VERSION ""

NS_ :

BS_:

BU_: AMP ETC GW ICM IVI NVS PDC TBOX VSP WCM

BO_ 1801 Diag_PhyReq_ICM: 8 GW
 SG_ Diag_PhyReq_ICM_Data : 0|64@1+ (1,0) [0|0] "N/A"  ICM

BO_ 1805 Diag_PhyReq_WCM: 8 GW
 SG_ Diag_PhyReq_WCM_Data : 0|64@1+ (1,0) [0|0] "N/A"  WCM

BO_ 1808 Diag_PhyReq_VSP: 8 GW
 SG_ Diag_PhyReq_VSP_Data : 0|64@1+ (1,0) [0|0] "N/A"  VSP

BO_ 1815 Diag_PhyReq_PDC: 8 GW
 SG_ Diag_PhyReq_PDC_Data : 0|64@1+ (1,0) [0|0] "N/A"  PDC

BO_ 1829 Diag_PhyReq_IVI: 8 GW
 SG_ Diag_PhyReq_IVI_Data : 0|64@1+ (1,0) [0|0] "N/A"  IVI

BO_ 1850 Diag_PhyReq_NVS: 8 GW
 SG_ Diag_PhyReq_NVS_Data : 0|64@1+ (1,0) [0|0] "N/A"  NVS

BO_ 1857 Diag_PhyReq_ETC: 8 GW
 SG_ Diag_PhyReq_ETC_Data : 0|64@1+ (1,0) [0|0] "N/A"  ETC

BO_ 1865 Diag_PhyReq_AMP: 8 GW
 SG_ Diag_PhyReq_AMP_Data : 0|64@1+ (1,0) [0|0] "N/A"  AMP

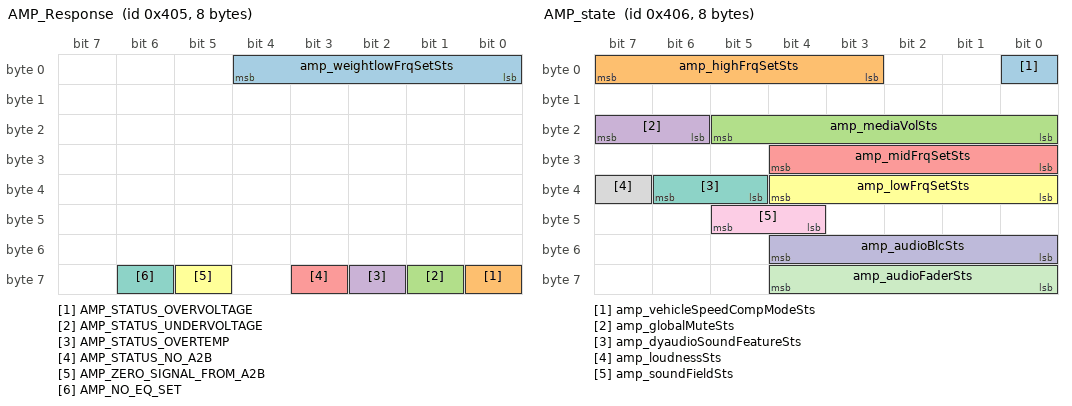
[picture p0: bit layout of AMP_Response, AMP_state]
BO_ 1029 AMP_Response: 8 AMP
 SG_ amp_weightlowFrqSetSts : 0|5@1+ (1,0) [0|31] ""  IVI
 SG_ AMP_STATUS_OVERVOLTAGE : 56|1@1+ (1,0) [0|1] "" Vector__XXX
 SG_ AMP_STATUS_UNDERVOLTAGE : 57|1@1+ (1,0) [0|1] "" Vector__XXX
 SG_ AMP_STATUS_OVERTEMP : 58|1@1+ (1,0) [0|1] "" Vector__XXX
 SG_ AMP_STATUS_NO_A2B : 59|1@1+ (1,0) [0|1] "" Vector__XXX
 SG_ AMP_ZERO_SIGNAL_FROM_A2B : 61|1@1+ (1,0) [0|1] "" Vector__XXX
 SG_ AMP_NO_EQ_SET : 62|1@1+ (1,0) [0|1] "" Vector__XXX

BO_ 1030 AMP_state: 8 AMP
 SG_ amp_vehicleSpeedCompModeSts : 0|1@1+ (1,0) [0|1] ""  IVI
 SG_ amp_highFrqSetSts : 3|5@1+ (1,0) [0|31] ""  IVI
 SG_ amp_mediaVolSts : 16|6@1+ (1,0) [0|63] ""  IVI
 SG_ amp_globalMuteSts : 22|2@1+ (1,0) [0|3] ""  IVI
 SG_ amp_midFrqSetSts : 24|5@1+ (1,0) [0|31] ""  IVI
 SG_ amp_lowFrqSetSts : 32|5@1+ (1,0) [0|31] ""  IVI
 SG_ amp_dyaudioSoundFeatureSts : 37|2@1+ (1,0) [0|3] ""  IVI
 SG_ amp_loudnessSts : 39|1@1+ (1,0) [0|1] ""  IVI
 SG_ amp_soundFieldSts : 44|2@1+ (1,0) [0|3] ""  IVI
 SG_ amp_audioBlcSts : 48|5@1+ (1,0) [0|31] ""  IVI
 SG_ amp_audioFaderSts : 56|5@1+ (1,0) [0|31] ""  IVI

BO_ 1609 NM_AMP: 8 AMP
 SG_ AMP_RMR : 8|1@1+ (1,0) [0|1] ""  ETC,GW,ICM,IVI,TBOX
 SG_ AMP_AWB : 12|1@1+ (1,0) [0|1] ""  ETC,GW,ICM,IVI,TBOX

BO_ 1993 Diag_Resp_AMP: 8 AMP
 SG_ Diag_Resp_AMP_Data : 0|64@1+ (1,0) [0|0] "N/A"  GW,TBOX

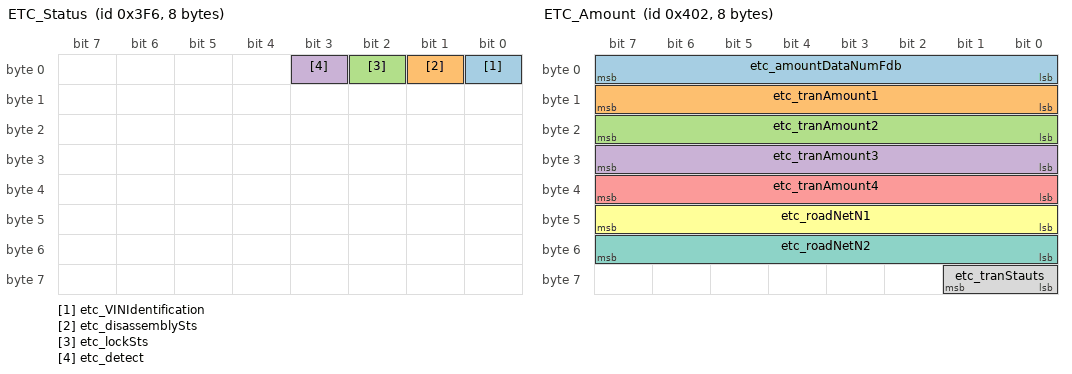
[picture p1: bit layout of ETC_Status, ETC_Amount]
BO_ 1014 ETC_Status: 8 ETC
 SG_ etc_VINIdentification : 0|1@1+ (1,0) [0|1] ""  IVI
 SG_ etc_disassemblySts : 1|1@1+ (1,0) [0|1] ""  IVI
 SG_ etc_lockSts : 2|1@1+ (1,0) [0|1] ""  IVI
 SG_ etc_detect : 3|1@1+ (1,0) [0|1] ""  IVI

BO_ 1026 ETC_Amount: 8 ETC
 SG_ etc_amountDataNumFdb : 0|8@1+ (1,0) [0|255] ""  IVI
 SG_ etc_tranAmount1 : 8|8@1+ (1,0) [0|255] "分"  IVI
 SG_ etc_tranAmount2 : 16|8@1+ (1,0) [0|255] "分"  IVI
 SG_ etc_tranAmount3 : 24|8@1+ (1,0) [0|255] "分"  IVI
 SG_ etc_tranAmount4 : 32|8@1+ (1,0) [0|255] "分"  IVI
 SG_ etc_roadNetN1 : 40|8@1+ (1,0) [0|255] ""  IVI
 SG_ etc_roadNetN2 : 48|8@1+ (1,0) [0|255] ""  IVI
 SG_ etc_tranStauts : 56|2@1+ (1,0) [0|3] ""  IVI

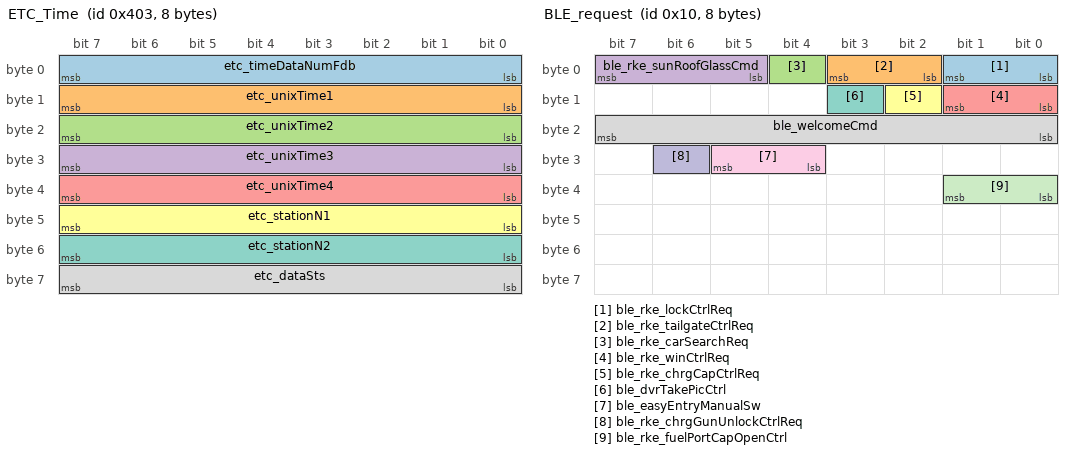
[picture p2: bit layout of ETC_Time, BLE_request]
BO_ 1027 ETC_Time: 8 ETC
 SG_ etc_timeDataNumFdb : 0|8@1+ (1,0) [0|255] ""  IVI
 SG_ etc_unixTime1 : 8|8@1+ (1,0) [0|255] "s"  IVI
 SG_ etc_unixTime2 : 16|8@1+ (1,0) [0|255] "s"  IVI
 SG_ etc_unixTime3 : 24|8@1+ (1,0) [0|255] "s"  IVI
 SG_ etc_unixTime4 : 32|8@1+ (1,0) [0|255] "s"  IVI
 SG_ etc_stationN1 : 40|8@1+ (1,0) [0|255] ""  IVI
 SG_ etc_stationN2 : 48|8@1+ (1,0) [0|255] ""  IVI
 SG_ etc_dataSts : 56|8@1+ (1,0) [0|255] ""  IVI

BO_ 1553 NM_ETC: 8 ETC
 SG_ ETC_RMR : 8|1@1+ (1,0) [0|1] ""  AMP,GW,ICM,IVI,TBOX
 SG_ ETC_AWB : 12|1@1+ (1,0) [0|1] ""  AMP,GW,ICM,IVI,TBOX

BO_ 1985 Diag_Resp_ETC: 8 ETC
 SG_ Diag_Resp_ETC_Data : 0|64@1+ (1,0) [0|0] "N/A"  GW,TBOX

BO_ 16 BLE_request: 8 GW
 SG_ ble_rke_lockCtrlReq : 0|2@1+ (1,0) [0|3] "" Vector__XXX
 SG_ ble_rke_tailgateCtrlReq : 2|2@1+ (1,0) [0|3] "" Vector__XXX
 SG_ ble_rke_carSearchReq : 4|1@1+ (1,0) [0|1] "" Vector__XXX
 SG_ ble_rke_sunRoofGlassCmd : 5|3@1+ (1,0) [0|7] "" Vector__XXX
 SG_ ble_rke_winCtrlReq : 8|2@1+ (1,0) [0|3] "" Vector__XXX
 SG_ ble_rke_chrgCapCtrlReq : 10|1@1+ (1,0) [0|1] "" Vector__XXX
 SG_ ble_dvrTakePicCtrl : 11|1@1+ (1,0) [0|1] ""  AMP,ICM
 SG_ ble_welcomeCmd : 16|8@1+ (1,0) [0|255] "" Vector__XXX
 SG_ ble_easyEntryManualSw : 28|2@1+ (1,0) [0|3] "" Vector__XXX
 SG_ ble_rke_chrgGunUnlockCtrlReq : 30|1@1+ (1,0) [0|1] "" Vector__XXX
 SG_ ble_rke_fuelPortCapOpenCtrl : 32|2@1+ (1,0) [0|3] "" Vector__XXX

BO_ 20 BMS_cellandmodulecnt: 8 GW
 SG_ bms_CellCnt : 0|13@1+ (1,0) [0|8191] ""  TBOX
 SG_ bms_ModuleCnt : 13|5@1+ (1,0) [0|31] ""  TBOX
 SG_ bms_packThermistorCnt : 18|7@1+ (1,0) [0|127] ""  TBOX
 SG_ bms_cellThermistorCnt : 25|7@1+ (1,0) [0|127] ""  TBOX
 SG_ bms_cellTemperatureDifferenceHig : 32|2@1+ (1,0) [0|3] ""  TBOX
 SG_ bms_batteryOverTemperature : 34|2@1+ (1,0) [0|3] ""  TBOX
 SG_ bms_overVoltage : 36|2@1+ (1,0) [0|3] ""  TBOX
 SG_ bms_lowVoltage : 38|2@1+ (1,0) [0|3] ""  TBOX
 SG_ bms_lowSoc : 40|2@1+ (1,0) [0|3] ""  TBOX
 SG_ bms_cellOverVoltage : 42|2@1+ (1,0) [0|3] ""  TBOX
 SG_ bms_cellLowVoltage : 44|2@1+ (1,0) [0|3] ""  TBOX
 SG_ bms_highSoc : 46|2@1+ (1,0) [0|3] ""  TBOX
 SG_ bms_socStepChange : 48|2@1+ (1,0) [0|3] ""  TBOX
 SG_ bms_chargerMismatch : 50|2@1+ (1,0) [0|3] ""  TBOX
 SG_ bms_cellOutOfBalance : 52|2@1+ (1,0) [0|3] ""  TBOX
 SG_ bms_isolationFault : 54|2@1+ (1,0) [0|3] ""  TBOX
 SG_ bms_hvilFault : 56|2@1+ (1,0) [0|3] ""  TBOX
 SG_ bms_batteryOverCharge : 58|2@1+ (1,0) [0|3] ""  TBOX

BO_ 65 BCM_tbox_auth: 8 GW
 SG_ bcm_challengeFrame1 : 0|64@1+ (1,0) [0|65535] ""  TBOX

BO_ 81 BCM_tbox_failCode: 8 GW
 SG_ bcm_failCode : 0|8@1+ (1,0) [0|255] ""  TBOX

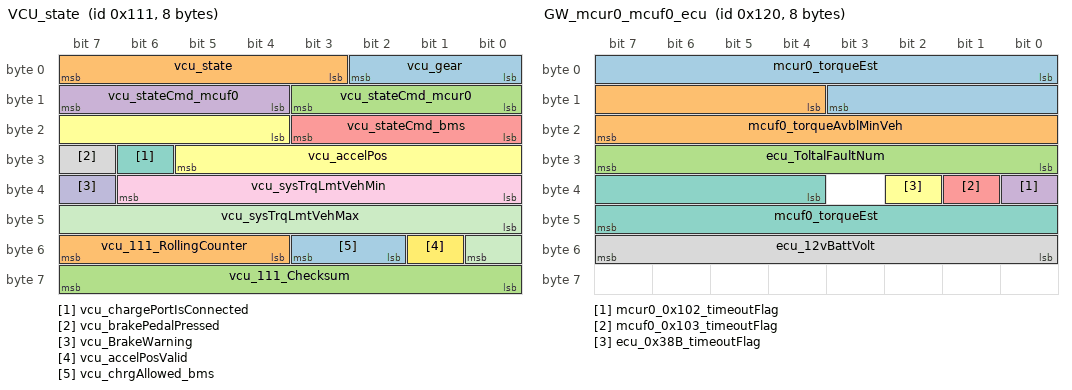
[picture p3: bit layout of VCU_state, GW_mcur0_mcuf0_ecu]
BO_ 273 VCU_state: 8 GW
 SG_ vcu_gear : 0|3@1+ (1,0) [0|7] ""  ETC,TBOX
 SG_ vcu_state : 3|5@1+ (1,0) [0|31] ""  TBOX
 SG_ vcu_stateCmd_mcur0 : 8|4@1+ (1,0) [0|15] ""  TBOX
 SG_ vcu_stateCmd_mcuf0 : 12|4@1+ (1,0) [0|15] ""  TBOX
 SG_ vcu_stateCmd_bms : 16|4@1+ (1,0) [0|15] ""  TBOX
 SG_ vcu_accelPos : 20|10@1+ (0.1,0) [0|100] "%"  IVI,NVS,TBOX
 SG_ vcu_chargePortIsConnected : 30|1@1+ (1,0) [0|1] ""  TBOX
 SG_ vcu_brakePedalPressed : 31|1@1+ (1,0) [0|1] ""  IVI,TBOX
 SG_ vcu_sysTrqLmtVehMin : 32|7@1+ (4,-500) [-500|0] "Nm"  TBOX
 SG_ vcu_BrakeWarning : 39|1@1+ (1,0) [0|1] ""  IVI
 SG_ vcu_sysTrqLmtVehMax : 40|9@1+ (3,0) [0|1200] "Nm"  TBOX
 SG_ vcu_accelPosValid : 49|1@1+ (1,0) [0|1] ""  IVI,NVS,TBOX
 SG_ vcu_chrgAllowed_bms : 50|2@1+ (1,0) [0|3] "" Vector__XXX
 SG_ vcu_111_RollingCounter : 52|4@1+ (1,0) [0|15] ""  IVI,NVS,TBOX
 SG_ vcu_111_Checksum : 56|8@1+ (1,0) [0|255] ""  IVI,NVS,TBOX

BO_ 276 BMS_state: 8 GW
 SG_ bms_state : 0|4@1+ (1,0) [0|15] ""  ICM,IVI,NVS,TBOX
 SG_ bms_dcChargeState : 4|3@1+ (1,0) [0|7] ""  IVI,TBOX
 SG_ bms_acChargeState : 7|3@1+ (1,0) [0|7] ""  IVI,TBOX
 SG_ bms_hvil : 10|1@1+ (1,0) [0|1] "" Vector__XXX
 SG_ bms_isolationState : 11|2@1+ (1,0) [0|3] "" Vector__XXX
 SG_ bms_contactorState : 13|4@1+ (1,0) [0|15] ""  TBOX
 SG_ bms_chargeInhibit : 17|1@1+ (1,0) [0|1] "" Vector__XXX
 SG_ bms_acChargeConnection : 18|1@1+ (1,0) [0|1] ""  IVI,TBOX
 SG_ bms_dcChargeConnection : 19|1@1+ (1,0) [0|1] ""  IVI,TBOX
 SG_ bms_alertLevel : 20|2@1+ (1,0) [0|3] ""  IVI
 SG_ bms_authenticationResult : 22|2@1+ (1,0) [0|3] ""  IVI
 SG_ bms_chargeReq : 24|1@1+ (1,0) [0|1] "" Vector__XXX
 SG_ bms_battWarmState : 25|2@1+ (1,0) [0|3] "" Vector__XXX
 SG_ bms_ptcEna : 27|2@1+ (1,0) [0|3] "" Vector__XXX
 SG_ bms_energyStatus : 29|10@1+ (0.1,0) [0|100] "" Vector__XXX
 SG_ bms_hvState : 39|3@1+ (1,0) [0|7] "" Vector__XXX
 SG_ bms_faultHvShutdownReq : 42|2@1+ (1,0) [0|3] "" Vector__XXX
 SG_ bms_114_Rollingcounter : 52|4@1+ (1,0) [0|15] ""  TBOX
 SG_ bms_114_Checksum : 56|8@1+ (1,0) [0|255] ""  TBOX

BO_ 288 GW_mcur0_mcuf0_ecu: 8 GW
 SG_ mcur0_torqueEst : 0|12@1- (0.8,0) [-1300|1300] "Nm"  TBOX
 SG_ mcuf0_torqueAvblMinVeh : 12|12@1+ (0.4,-1300) [-1300|0] "Nm"  TBOX
 SG_ ecu_ToltalFaultNum : 24|8@1+ (1,0) [0|252] ""  TBOX
 SG_ mcur0_0x102_timeoutFlag : 32|1@1+ (1,0) [0|1] "" Vector__XXX
 SG_ mcuf0_0x103_timeoutFlag : 33|1@1+ (1,0) [0|1] "" Vector__XXX
 SG_ ecu_0x38B_timeoutFlag : 34|1@1+ (1,0) [0|1] "" Vector__XXX
 SG_ mcuf0_torqueEst : 36|12@1- (0.8,0) [-1300|1300] "Nm"  TBOX
 SG_ ecu_12vBattVolt : 48|8@1+ (0.1,0) [0|25] "V"  TBOX

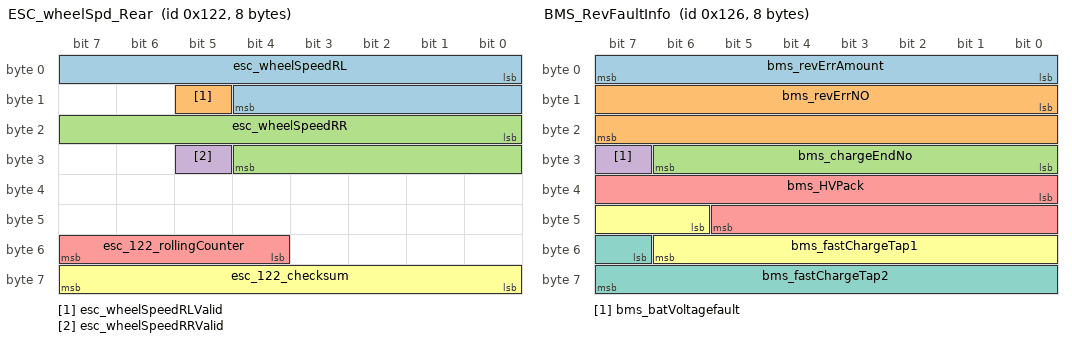
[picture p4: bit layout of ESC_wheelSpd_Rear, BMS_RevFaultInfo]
BO_ 290 ESC_wheelSpd_Rear: 8 GW
 SG_ esc_wheelSpeedRL : 0|13@1+ (0.05625,0) [0|270] "km/h"  IVI,TBOX
 SG_ esc_wheelSpeedRLValid : 13|1@1+ (1,0) [0|1] ""  IVI,TBOX
 SG_ esc_wheelSpeedRR : 16|13@1+ (0.05625,0) [0|270] "km/h"  IVI,TBOX
 SG_ esc_wheelSpeedRRValid : 29|1@1+ (1,0) [0|1] ""  IVI,TBOX
 SG_ esc_122_rollingCounter : 52|4@1+ (1,0) [0|15] ""  IVI
 SG_ esc_122_checksum : 56|8@1+ (1,0) [0|255] ""  IVI

BO_ 294 BMS_RevFaultInfo: 8 GW
 SG_ bms_revErrAmount : 0|8@1+ (1,0) [0|255] ""  TBOX
 SG_ bms_revErrNO : 8|16@1+ (1,0) [0|65535] ""  TBOX
 SG_ bms_chargeEndNo : 24|7@1+ (1,0) [0|127] ""  TBOX
 SG_ bms_batVoltagefault : 31|1@1+ (1,0) [0|1] "" Vector__XXX
 SG_ bms_HVPack : 32|14@1+ (0.05,0) [0|800] "V" Vector__XXX
 SG_ bms_fastChargeTap1 : 46|9@1+ (0.5,-40) [-40|215] "℃"  TBOX
 SG_ bms_fastChargeTap2 : 55|9@1+ (0.5,-40) [-40|215] "℃"  TBOX

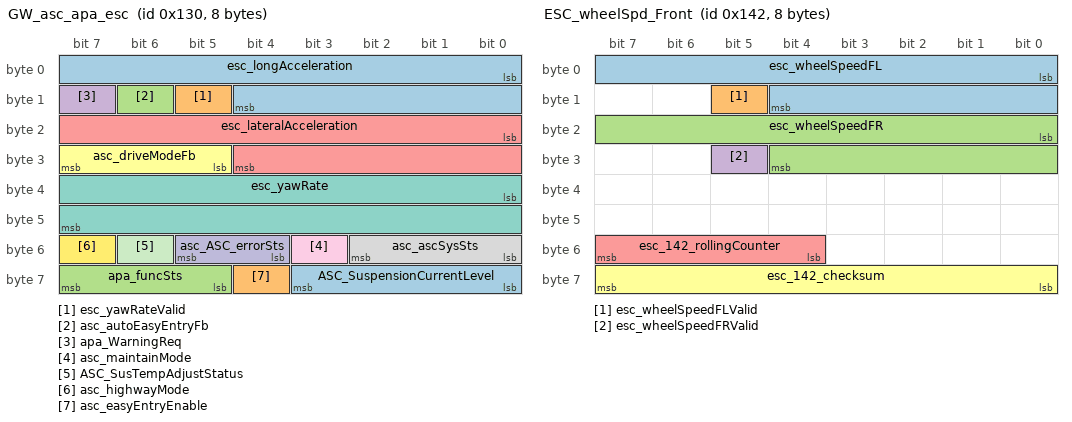
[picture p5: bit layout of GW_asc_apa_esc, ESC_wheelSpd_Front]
BO_ 304 GW_asc_apa_esc: 8 GW
 SG_ esc_longAcceleration : 0|13@1+ (0.01,-21) [-21|21] "m/s2"  ICM
 SG_ esc_yawRateValid : 13|1@1+ (1,0) [0|1] ""  ICM
 SG_ asc_autoEasyEntryFb : 14|1@1+ (1,0) [0|1] ""  IVI
 SG_ apa_WarningReq : 15|1@1+ (1,0) [0|1] ""  IVI
 SG_ esc_lateralAcceleration : 16|13@1+ (0.01,-21) [-21|21] "m/s2"  ICM
 SG_ asc_driveModeFb : 29|3@1+ (1,0) [0|7] ""  IVI
 SG_ esc_yawRate : 32|16@1+ (0.005,-163.84) [-163.84|163.835] "degree/s"  ICM
 SG_ asc_ascSysSts : 48|3@1+ (1,0) [0|7] ""  IVI
 SG_ asc_maintainMode : 51|1@1+ (1,0) [0|1] ""  IVI
 SG_ asc_ASC_errorSts : 52|2@1+ (1,0) [0|3] ""  IVI,TBOX
 SG_ ASC_SusTempAdjustStatus : 54|1@1+ (1,0) [0|1] ""  IVI
 SG_ asc_highwayMode : 55|1@1+ (1,0) [0|1] ""  IVI
 SG_ ASC_SuspensionCurrentLevel : 56|4@1+ (1,0) [0|15] ""  IVI
 SG_ asc_easyEntryEnable : 60|1@1+ (1,0) [0|1] ""  IVI
 SG_ apa_funcSts : 61|3@1+ (1,0) [0|7] ""  IVI

BO_ 320 GW_hcm: 8 GW
 SG_ hcm_0x100_timeoutFlag : 0|1@1+ (1,0) [0|1] ""  IVI
 SG_ hcm_0x110_timeoutFlag : 1|1@1+ (1,0) [0|1] ""  IVI
 SG_ hcm_leftHighBeamFaultSt : 7|1@1+ (1,0) [0|1] ""  IVI
 SG_ hcm_adbFuctionStsLt : 8|2@1+ (1,0) [0|3] ""  IVI
 SG_ hcm_rightHighBeamFaultSt : 10|1@1+ (1,0) [0|1] ""  IVI
 SG_ hcm_adbFuctionStsRt : 11|2@1+ (1,0) [0|3] ""  IVI
 SG_ AC_CompressorActualPower : 24|7@1+ (0.1,0) [0|10] "KW"  TBOX
 SG_ ac_0x3A6_timeoutFlag : 31|1@1+ (1,0) [0|1] ""  TBOX
 SG_ hcm_middleLeftPositionLampFault : 40|1@1+ (1,0) [0|1] ""  IVI
 SG_ hcm_middleRightPositionLampFault : 41|1@1+ (1,0) [0|1] ""  IVI
 SG_ hcm_hcmHeightSetLt : 42|3@1+ (1,0) [0|7] ""  IVI
 SG_ hcm_hcmHeightSetRt : 45|3@1+ (1,0) [0|7] ""  IVI
 SG_ hcm_leftHighBeamLedsFaultSt : 48|1@1+ (1,0) [0|1] ""  IVI
 SG_ hcm_leftHighBeamDriFaultWarning : 49|2@1+ (1,0) [0|2] ""  IVI
 SG_ hcm_leftLowBeamFaultSt : 51|1@1+ (1,0) [0|1] ""  IVI
 SG_ hcm_turnLampWarningLt : 52|1@1+ (1,0) [0|1] ""  IVI
 SG_ hcm_positionLampWarningLt : 53|1@1+ (1,0) [0|1] ""  IVI
 SG_ hcm_dayTimeRunningLampWarningLt : 54|1@1+ (1,0) [0|1] ""  IVI
 SG_ hcm_rightHighBeamLedsFaultSt : 56|1@1+ (1,0) [0|1] ""  IVI
 SG_ hcm_rightHighBeamDriFaultWarning : 57|2@1+ (1,0) [0|2] ""  IVI
 SG_ hcm_rightLowBeamFaultSt : 59|1@1+ (1,0) [0|1] ""  IVI
 SG_ hcm_turnLampWarningRt : 60|1@1+ (1,0) [0|1] ""  IVI
 SG_ hcm_positionLampWarningRt : 61|1@1+ (1,0) [0|1] ""  IVI
 SG_ hcm_dayTimeRunningLampWarningRt : 62|1@1+ (1,0) [0|1] ""  IVI

BO_ 322 ESC_wheelSpd_Front: 8 GW
 SG_ esc_wheelSpeedFL : 0|13@1+ (0.05625,0) [0|270] "km/h"  IVI,TBOX
 SG_ esc_wheelSpeedFLValid : 13|1@1+ (1,0) [0|1] ""  IVI,TBOX
 SG_ esc_wheelSpeedFR : 16|13@1+ (0.05625,0) [0|270] "km/h"  IVI,TBOX
 SG_ esc_wheelSpeedFRValid : 29|1@1+ (1,0) [0|1] ""  IVI,TBOX
 SG_ esc_142_rollingCounter : 52|4@1+ (1,0) [0|15] ""  IVI
 SG_ esc_142_checksum : 56|8@1+ (1,0) [0|255] ""  IVI

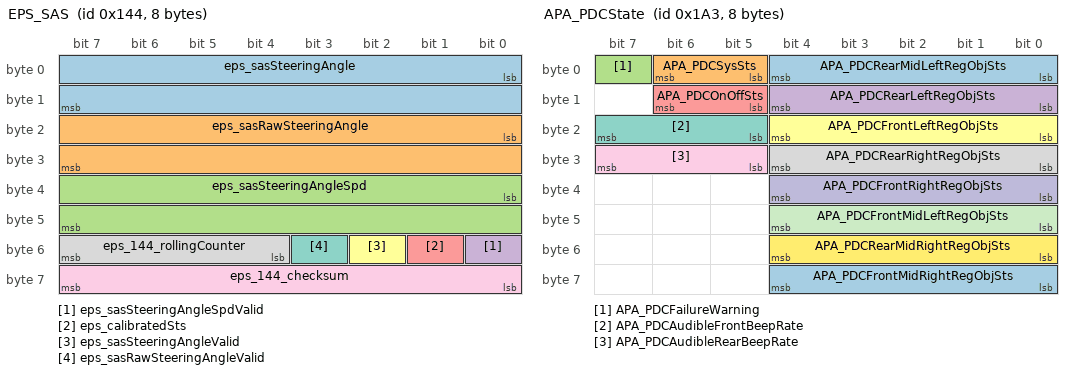
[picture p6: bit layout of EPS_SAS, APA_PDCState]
BO_ 324 EPS_SAS: 8 GW
 SG_ eps_sasSteeringAngle : 0|16@1+ (0.1,-780) [-780|779.9] "deg"  ICM,IVI,NVS,TBOX
 SG_ eps_sasRawSteeringAngle : 16|16@1+ (0.1,-780) [-780|779.9] "deg" Vector__XXX
 SG_ eps_sasSteeringAngleSpd : 32|16@1+ (0.1,-780) [-780|779.9] "deg/s"  NVS
 SG_ eps_sasSteeringAngleSpdValid : 48|1@1+ (1,0) [0|1] ""  NVS
 SG_ eps_calibratedSts : 49|1@1+ (1,0) [0|1] "" Vector__XXX
 SG_ eps_sasSteeringAngleValid : 50|1@1+ (1,0) [0|1] ""  ICM,IVI,NVS
 SG_ eps_sasRawSteeringAngleValid : 51|1@1+ (1,0) [0|1] "" Vector__XXX
 SG_ eps_144_rollingCounter : 52|4@1+ (1,0) [0|15] ""  ICM,IVI,TBOX
 SG_ eps_144_checksum : 56|8@1+ (1,0) [0|255] ""  ICM,IVI,TBOX

BO_ 419 APA_PDCState: 8 GW
 SG_ APA_PDCRearMidLeftRegObjSts : 0|5@1+ (1,0) [0|31] ""  IVI
 SG_ APA_PDCSysSts : 5|2@1+ (1,0) [0|3] ""  IVI
 SG_ APA_PDCFailureWarning : 7|1@1+ (1,0) [0|1] ""  IVI
 SG_ APA_PDCRearLeftRegObjSts : 8|5@1+ (1,0) [0|31] ""  IVI
 SG_ APA_PDCOnOffSts : 13|2@1+ (1,0) [0|3] ""  IVI
 SG_ APA_PDCFrontLeftRegObjSts : 16|5@1+ (1,0) [0|31] ""  IVI
 SG_ APA_PDCAudibleFrontBeepRate : 21|3@1+ (1,0) [0|7] ""  IVI
 SG_ APA_PDCRearRightRegObjSts : 24|5@1+ (1,0) [0|31] ""  IVI
 SG_ APA_PDCAudibleRearBeepRate : 29|3@1+ (1,0) [0|7] ""  IVI
 SG_ APA_PDCFrontRightRegObjSts : 32|5@1+ (1,0) [0|31] ""  IVI
 SG_ APA_PDCFrontMidLeftRegObjSts : 40|5@1+ (1,0) [0|31] ""  IVI
 SG_ APA_PDCRearMidRightRegObjSts : 48|5@1+ (1,0) [0|31] ""  IVI
 SG_ APA_PDCFrontMidRightRegObjSts : 56|5@1+ (1,0) [0|31] ""  IVI

BO_ 515 APA_avmState: 8 GW
 SG_ apa_avmSts : 0|4@1+ (1,0) [0|15] ""  IVI
 SG_ apa_avmHmiIndex : 4|4@1+ (1,0) [0|15] ""  IVI
 SG_ apa_avmViewMode : 8|2@1+ (1,0) [0|3] ""  IVI
 SG_ apa_avmDisplayReq : 10|2@1+ (1,0) [0|3] ""  IVI
 SG_ apa_avmMODSts : 12|2@1+ (1,0) [0|3] ""  IVI
 SG_ apa_avmFrontCaneraFailed : 14|1@1+ (1,0) [0|1] ""  IVI
 SG_ apa_avmRearCaneraFailed : 15|1@1+ (1,0) [0|1] ""  IVI
 SG_ apa_avmLeftCaneraFailed : 16|1@1+ (1,0) [0|1] ""  IVI
 SG_ apa_avmRightCaneraFailed : 17|1@1+ (1,0) [0|1] ""  IVI
 SG_ apa_avmVideoOutputFailed : 18|1@1+ (1,0) [0|1] ""  IVI
 SG_ apa_avmControllerOperatingFailed : 19|1@1+ (1,0) [0|1] ""  IVI
 SG_ apa_keytriggersts : 20|1@1+ (1,0) [0|1] ""  IVI
 SG_ apa_avmTrigByTurnningSts : 21|1@1+ (1,0) [0|1] ""  IVI
 SG_ apa_avmSingleViewSts : 24|5@1+ (1,0) [0|15] ""  IVI
 SG_ apa_avmFrontModWarningSts : 29|1@1+ (1,0) [0|1] ""  IVI
 SG_ apa_avmRearModWarningSts : 30|1@1+ (1,0) [0|1] ""  IVI
 SG_ apa_avmLeftModWarningSts : 31|1@1+ (1,0) [0|1] ""  IVI
 SG_ apa_avmRightModWarningSts : 32|1@1+ (1,0) [0|1] ""  IVI
 SG_ apa_avmCalibrationSts : 33|1@1+ (1,0) [0|1] ""  IVI
 SG_ apa_avmTrajectory_display : 34|1@1+ (1,0) [0|1] ""  IVI
 SG_ apa_avmAutoswitching_display : 35|1@1+ (1,0) [0|1] ""  IVI
 SG_ apa_avmCarBodyTransparent : 36|1@1+ (1,0) [0|1] ""  IVI
 SG_ apa_avmSwSts : 37|1@1+ (1,0) [0|1] ""  IVI
 SG_ apa_avmMonitVideoOutput : 38|1@1+ (1,0) [0|1] ""  IVI,TBOX
 SG_ apa_avmPDCfailureWarn : 40|3@1+ (1,0) [0|7] ""  IVI
 SG_ apa_avm_QuitSw : 43|1@1+ (1,0) [0|1] "" Vector__XXX
 SG_ APA_AVM_Voicefeedback : 44|5@1+ (1,0) [0|31] ""  IVI
 SG_ APA_203_RollingCounter : 52|4@1+ (1,0) [0|15] ""  IVI
 SG_ APA_203_Checksum : 56|8@1+ (1,0) [0|255] ""  IVI

BO_ 520 AVM_state: 8 GW
 SG_ avm_sts : 0|4@1+ (1,0) [0|15] ""  IVI
 SG_ avm_hmiIndex : 4|4@1+ (1,0) [0|15] ""  IVI
 SG_ avm_viewMode : 8|2@1+ (1,0) [0|3] ""  IVI
 SG_ avm_displayReq : 10|2@1+ (1,0) [0|3] ""  IVI
 SG_ avm_MODSts : 12|2@1+ (1,0) [0|3] ""  IVI
 SG_ avm_frontCaneraFailed : 14|1@1+ (1,0) [0|1] ""  IVI
 SG_ avm_rearCaneraFailed : 15|1@1+ (1,0) [0|1] ""  IVI
 SG_ avm_leftCaneraFailed : 16|1@1+ (1,0) [0|1] ""  IVI
 SG_ avm_rightCaneraFailed : 17|1@1+ (1,0) [0|1] ""  IVI
 SG_ avm_videoOutputFailed : 18|1@1+ (1,0) [0|1] ""  IVI
 SG_ avm_controllerOperatingFailed : 19|1@1+ (1,0) [0|1] ""  IVI
 SG_ avm_trigByTurnningSts : 21|1@1+ (1,0) [0|1] ""  IVI
 SG_ avm_singleViewSts : 24|5@1+ (1,0) [0|31] ""  IVI
 SG_ avm_frontModWarningSts : 29|1@1+ (1,0) [0|1] ""  IVI
 SG_ avm_rearModWarningSts : 30|1@1+ (1,0) [0|1] ""  IVI
 SG_ avm_leftModWarningSts : 31|1@1+ (1,0) [0|1] ""  IVI
 SG_ avm_rightModWarningSts : 32|1@1+ (1,0) [0|1] ""  IVI
 SG_ avm_calibrationSts : 33|1@1+ (1,0) [0|1] ""  IVI
 SG_ avm_Trajectory_display : 34|1@1+ (1,0) [0|1] ""  IVI
 SG_ avm_Autoswitching_display : 35|1@1+ (1,0) [0|1] ""  IVI
 SG_ avm_CarBodyTransparent : 36|1@1+ (1,0) [0|1] ""  IVI
 SG_ avm_SwSts : 37|1@1+ (1,0) [0|1] ""  IVI
 SG_ avm_PDCfailureWarn : 40|3@1+ (1,0) [0|7] ""  IVI
 SG_ avm_QuitSw : 43|1@1+ (1,0) [0|1] ""  IVI
 SG_ AVM_208_RollingCounter : 52|4@1+ (1,0) [0|15] ""  IVI
 SG_ AVM_208_Checksum : 56|8@1+ (1,0) [0|255] ""  IVI

BO_ 530 ESC_state1: 8 GW
 SG_ esc_vehicleSpeed : 0|13@1+ (0.05625,0) [0|270] "km/h"  AMP,ETC,ICM,IVI,NVS,PDC,TBOX,VSP
 SG_ esc_vehicleSpeedValid : 13|1@1+ (1,0) [0|1] ""  AMP,ETC,ICM,IVI,NVS,PDC,TBOX,VSP
 SG_ esc_absFault : 14|1@1+ (1,0) [0|1] ""  IVI,NVS,TBOX
 SG_ esc_absActive : 15|1@1+ (1,0) [0|1] ""  TBOX
 SG_ esc_vdcActive : 16|1@1+ (1,0) [0|1] ""  TBOX
 SG_ esc_escActive : 17|1@1+ (1,0) [0|1] ""  IVI,TBOX
 SG_ esc_tcsActive : 18|1@1+ (1,0) [0|1] ""  TBOX
 SG_ esc_OBD_MILOnRq : 20|1@1+ (1,0) [0|1] "" Vector__XXX
 SG_ esc_avhActive : 22|1@1+ (1,0) [0|1] ""  IVI
 SG_ esc_avhStandby : 23|1@1+ (1,0) [0|1] ""  IVI
 SG_ esc_avhAvailable : 24|1@1+ (1,0) [0|1] ""  IVI
 SG_ esc_cdpActive : 25|1@1+ (1,0) [0|1] ""  ICM,TBOX
 SG_ esc_cdpAvailable : 26|1@1+ (1,0) [0|1] "" Vector__XXX
 SG_ esc_hdcSts : 27|2@1+ (1,0) [0|3] ""  IVI
 SG_ esc_hdcAvailable : 29|1@1+ (1,0) [0|1] ""  IVI
 SG_ esc_hhcActive : 30|1@1+ (1,0) [0|1] ""  IVI
 SG_ esc_hhcAvailable : 31|1@1+ (1,0) [0|1] ""  IVI
 SG_ esc_masCylBrakePressure : 32|12@1+ (0.1,0) [0|250] "Bar"  TBOX
 SG_ esc_masCylBrakePressureValid : 44|1@1+ (1,0) [0|1] ""  TBOX
 SG_ esc_wheelCyBrakeForceExist : 45|1@1+ (1,0) [0|1] "" Vector__XXX
 SG_ esc_ebdFault : 46|1@1+ (1,0) [0|1] ""  IVI,TBOX
 SG_ esc_offSts : 47|1@1+ (1,0) [0|1] ""  IVI,TBOX
 SG_ esc_escFault : 48|1@1+ (1,0) [0|1] ""  IVI,TBOX
 SG_ esc_emergencyBrakeSts : 49|1@1+ (1,0) [0|1] "" Vector__XXX
 SG_ esc_dtcActive : 50|1@1+ (1,0) [0|1] ""  TBOX
 SG_ esc_gearholdRequst : 51|1@1+ (1,0) [0|1] "" Vector__XXX
 SG_ esc_212_rollingCounter : 52|4@1+ (1,0) [0|15] ""  IVI
 SG_ esc_212_checksum : 56|8@1+ (1,0) [0|255] ""  IVI

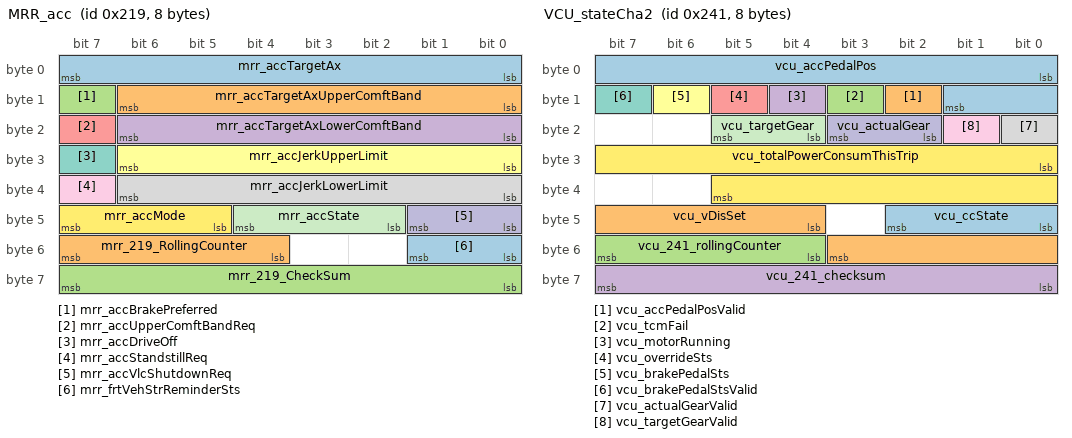
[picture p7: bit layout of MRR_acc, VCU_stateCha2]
BO_ 537 MRR_acc: 8 GW
 SG_ mrr_accTargetAx : 0|8@1+ (0.05,-5) [-5|7.75] "m/s2"  TBOX
 SG_ mrr_accTargetAxUpperComftBand : 8|7@1+ (0.05,0) [0|3.15] "m/s2" Vector__XXX
 SG_ mrr_accBrakePreferred : 15|1@1+ (1,0) [0|1] "" Vector__XXX
 SG_ mrr_accTargetAxLowerComftBand : 16|7@1+ (0.05,0) [0|3.15] "m/s2" Vector__XXX
 SG_ mrr_accUpperComftBandReq : 23|1@1+ (1,0) [0|1] "" Vector__XXX
 SG_ mrr_accJerkUpperLimit : 24|7@1+ (0.1,0) [0|12.7] "m/s3" Vector__XXX
 SG_ mrr_accDriveOff : 31|1@1+ (1,0) [0|1] "" Vector__XXX
 SG_ mrr_accJerkLowerLimit : 32|7@1+ (0.1,-12.7) [-12.7|0] "m/s3" Vector__XXX
 SG_ mrr_accStandstillReq : 39|1@1+ (1,0) [0|1] "" Vector__XXX
 SG_ mrr_accVlcShutdownReq : 40|2@1+ (1,0) [0|3] "" Vector__XXX
 SG_ mrr_accState : 42|3@1+ (1,0) [0|7] ""  TBOX
 SG_ mrr_accMode : 45|3@1+ (1,0) [0|7] ""  IVI
 SG_ mrr_frtVehStrReminderSts : 48|2@1+ (1,0) [0|3] ""  IVI
 SG_ mrr_219_RollingCounter : 52|4@1+ (1,0) [0|15] ""  IVI
 SG_ mrr_219_CheckSum : 56|8@1+ (1,0) [0|255] ""  IVI

BO_ 538 MPC_state: 8 GW
 SG_ mpc_leftVisualization : 0|2@1+ (1,0) [0|3] ""  ICM,IVI
 SG_ mpc_rightVisualization : 2|2@1+ (1,0) [0|3] ""  ICM,IVI
 SG_ mpc_laneAssitType : 4|3@1+ (1,0) [0|7] ""  IVI,TBOX
 SG_ mpc_adasTorqueReqSts : 7|1@1+ (1,0) [0|1] "" Vector__XXX
 SG_ mpc_lasSensitivity : 8|2@1+ (1,0) [0|3] ""  IVI
 SG_ mpc_lasSts : 10|3@1+ (1,0) [0|7] ""  IVI,TBOX
 SG_ mpc_adasTorqueReq : 16|11@1+ (0.02,-20.48) [-20.48|20.46] "Nm"  TBOX
 SG_ mpc_adasTakeoverReq : 27|2@1+ (1,0) [0|3] ""  IVI
 SG_ mpc_tjaSts : 29|3@1+ (1,0) [0|7] ""  IVI,TBOX
 SG_ mpc_isaOverSpdWarningSts : 32|1@1+ (1,0) [0|1] ""  IVI
 SG_ mpc_tjaindinfo : 33|3@1+ (1,0) [0|7] ""  IVI
 SG_ mpc_isaMode : 36|3@1+ (1,0) [0|7] ""  IVI
 SG_ mpc_adasTorqueReqValid : 39|1@1+ (1,0) [0|1] ""  TBOX
 SG_ mpc_isaSpeedLimit : 40|6@1+ (1,0) [0|63] ""  IVI
 SG_ mpc_isaOnOffSts : 48|2@1+ (1,0) [0|3] ""  IVI
 SG_ mpc_21A_rollingCounter : 52|4@1+ (1,0) [0|15] ""  ICM,IVI
 SG_ mpc_21A_checkSum : 56|8@1+ (1,0) [0|255] ""  ICM,IVI

BO_ 569 MRR_pss: 8 GW
 SG_ mrr_aebTargetAx : 0|10@1+ (0.05,-16) [-16|16] "m/s2"  TBOX
 SG_ mrr_aebReq : 10|1@1+ (1,0) [0|1] ""  ICM
 SG_ mrr_abaLevel : 12|2@1+ (1,0) [0|3] "" Vector__XXX
 SG_ mrr_abaReq : 14|1@1+ (1,0) [0|1] "" Vector__XXX
 SG_ mrr_awbReq : 15|1@1+ (1,0) [0|1] "" Vector__XXX
 SG_ mrr_awbLevel : 16|3@1+ (1,0) [0|7] "" Vector__XXX
 SG_ mrr_abpReq : 19|1@1+ (1,0) [0|1] "" Vector__XXX
 SG_ mrr_aebOnOffSts : 20|2@1+ (1,0) [0|3] ""  IVI
 SG_ mrr_accTakeOverReq : 23|1@1+ (1,0) [0|1] ""  IVI
 SG_ mrr_vSetDis : 24|9@1+ (0.5,0) [0|255.5] "KPH"  IVI
 SG_ mrr_PEBSWarning : 33|3@1+ (1,0) [0|7] ""  IVI
 SG_ mrr_timeGapSet : 36|3@1+ (1,0) [0|7] ""  IVI
 SG_ mrr_fcwOnOffSts : 40|2@1+ (1,0) [0|3] ""  IVI
 SG_ mrr_textInfo : 43|5@1+ (1,0) [0|15] ""  IVI
 SG_ mrr_fcwSts : 48|2@1+ (1,0) [0|3] ""  IVI,TBOX
 SG_ mrr_aebSts : 50|2@1+ (1,0) [0|3] ""  IVI,TBOX
 SG_ mrr_239_RollingCounter : 52|4@1+ (1,0) [0|15] ""  IVI
 SG_ mrr_239_CheckSum : 56|8@1+ (1,0) [0|255] "N/A"  IVI

BO_ 571 MRR_R1_state: 8 GW
 SG_ mrr_r1_systemErrorSts : 0|1@1+ (1,0) [0|1] ""  IVI,TBOX
 SG_ mrr_r1_BSDLCAWorkingSts : 1|1@1+ (1,0) [0|1] ""  IVI
 SG_ mrr_r1_RCTAWorkingSts : 2|1@1+ (1,0) [0|1] ""  IVI
 SG_ mrr_r1_DOWWorkingSts : 3|1@1+ (1,0) [0|1] ""  IVI
 SG_ mrr_r1_RCWWorkingSts : 4|1@1+ (1,0) [0|1] ""  IVI
 SG_ mrr_r1_leftBSDLCAWarning : 5|2@1+ (1,0) [0|3] ""  IVI
 SG_ mrr_r1_leftRCTAWarnning : 7|1@1+ (1,0) [0|1] ""  IVI
 SG_ mrr_r1_leftDOWWarnning : 8|2@1+ (1,0) [0|3] ""  IVI
 SG_ mrr_r1_rearCollisionWarning : 10|1@1+ (1,0) [0|1] ""  IVI
 SG_ mrr_r1_rightBSDLCAWarning : 11|2@1+ (1,0) [0|3] ""  IVI
 SG_ mrr_r1_rightRCTAWarnning : 13|1@1+ (1,0) [0|1] ""  IVI
 SG_ mrr_r1_rightDOWWarnning : 14|2@1+ (1,0) [0|3] ""  IVI
 SG_ mrr_r1_targetStsLR : 16|1@1+ (1,0) [0|1] ""  IVI,TBOX
 SG_ mrr_r1_targetLongDisLR : 17|7@1+ (1,-20) [-20|107] "m"  IVI,TBOX
 SG_ mrr_r1_targetLateralDistanceLR : 24|6@1+ (0.1,0) [0|6.3] "m"  IVI,TBOX
 SG_ mrr_r1_targetDangerLevelLR : 30|2@1+ (1,0) [0|3] ""  IVI,TBOX
 SG_ mrr_r1_targetStsRR : 32|1@1+ (1,0) [0|1] ""  IVI,TBOX
 SG_ mrr_r1_targetLongDisRR : 33|7@1+ (1,-20) [-20|107] "m"  IVI,TBOX
 SG_ mrr_r1_targetLateralDistanceRR : 40|6@1+ (0.1,0) [0|6.3] "m"  IVI,TBOX
 SG_ mrr_r1_targetDangerLevelRR : 46|2@1+ (1,0) [0|3] ""  IVI,TBOX
 SG_ mrr_r1_targetTypeLR : 48|3@1+ (1,0) [0|7] ""  IVI,TBOX
 SG_ mrr_r1_targetTypeRR : 51|3@1+ (1,0) [0|7] ""  IVI,TBOX

BO_ 577 VCU_stateCha2: 8 GW
 SG_ vcu_accPedalPos : 0|10@1+ (0.1,0) [0|100] "%"  ICM,TBOX
 SG_ vcu_accPedalPosValid : 10|1@1+ (1,0) [0|1] ""  ICM,TBOX
 SG_ vcu_tcmFail : 11|1@1+ (1,0) [0|1] ""  IVI
 SG_ vcu_motorRunning : 12|1@1+ (1,0) [0|1] "" Vector__XXX
 SG_ vcu_overrideSts : 13|1@1+ (1,0) [0|1] "" Vector__XXX
 SG_ vcu_brakePedalSts : 14|1@1+ (1,0) [0|1] ""  ICM,IVI,NVS,TBOX
 SG_ vcu_brakePedalStsValid : 15|1@1+ (1,0) [0|1] ""  ICM,IVI,NVS,TBOX
 SG_ vcu_actualGearValid : 16|1@1+ (1,0) [0|1] ""  ICM,IVI,NVS,PDC,TBOX,VSP
 SG_ vcu_targetGearValid : 17|1@1+ (1,0) [0|1] "" Vector__XXX
 SG_ vcu_actualGear : 18|2@1+ (1,0) [0|3] ""  ICM,IVI,NVS,PDC,TBOX,VSP
 SG_ vcu_targetGear : 20|2@1+ (1,0) [0|3] "" Vector__XXX
 SG_ vcu_totalPowerConsumThisTrip : 24|14@1+ (0.1,0) [0|1000] "kw/h"  IVI
 SG_ vcu_ccState : 40|3@1+ (1,0) [0|7] ""  IVI
 SG_ vcu_vDisSet : 44|8@1+ (1,0) [0|255] "kw/h"  IVI
 SG_ vcu_241_rollingCounter : 52|4@1+ (1,0) [0|15] ""  ICM,IVI,NVS,PDC,TBOX,VSP
 SG_ vcu_241_checksum : 56|8@1+ (1,0) [0|255] ""  ICM,IVI,NVS,PDC,TBOX,VSP

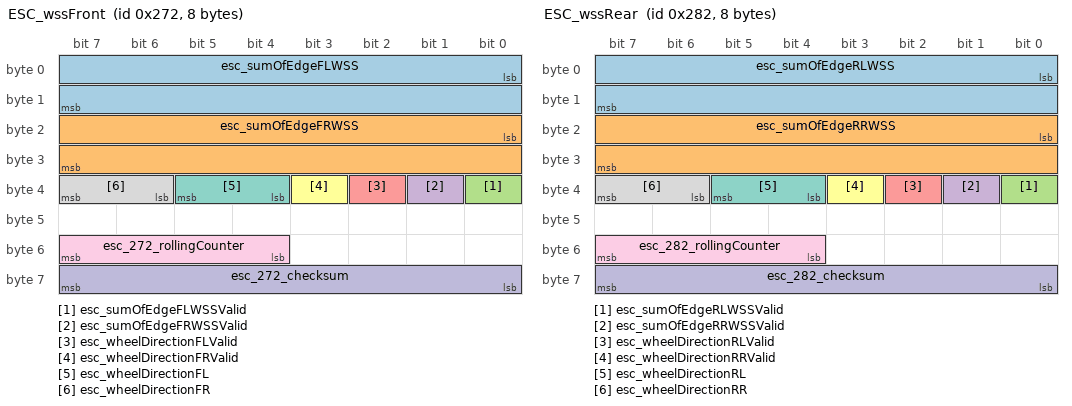
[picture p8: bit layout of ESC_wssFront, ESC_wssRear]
BO_ 626 ESC_wssFront: 8 GW
 SG_ esc_sumOfEdgeFLWSS : 0|16@1+ (1,0) [0|65535] "" Vector__XXX
 SG_ esc_sumOfEdgeFRWSS : 16|16@1+ (1,0) [0|65535] "" Vector__XXX
 SG_ esc_sumOfEdgeFLWSSValid : 32|1@1+ (1,0) [0|1] "" Vector__XXX
 SG_ esc_sumOfEdgeFRWSSValid : 33|1@1+ (1,0) [0|1] "" Vector__XXX
 SG_ esc_wheelDirectionFLValid : 34|1@1+ (1,0) [0|1] "" Vector__XXX
 SG_ esc_wheelDirectionFRValid : 35|1@1+ (1,0) [0|1] "" Vector__XXX
 SG_ esc_wheelDirectionFL : 36|2@1+ (1,0) [0|3] ""  PDC
 SG_ esc_wheelDirectionFR : 38|2@1+ (1,0) [0|3] ""  PDC
 SG_ esc_272_rollingCounter : 52|4@1+ (1,0) [0|15] ""  PDC
 SG_ esc_272_checksum : 56|8@1+ (1,0) [0|255] ""  PDC

BO_ 642 ESC_wssRear: 8 GW
 SG_ esc_sumOfEdgeRLWSS : 0|16@1+ (1,0) [0|65535] "" Vector__XXX
 SG_ esc_sumOfEdgeRRWSS : 16|16@1+ (1,0) [0|65535] "" Vector__XXX
 SG_ esc_sumOfEdgeRLWSSValid : 32|1@1+ (1,0) [0|1] "" Vector__XXX
 SG_ esc_sumOfEdgeRRWSSValid : 33|1@1+ (1,0) [0|1] "" Vector__XXX
 SG_ esc_wheelDirectionRLValid : 34|1@1+ (1,0) [0|1] "" Vector__XXX
 SG_ esc_wheelDirectionRRValid : 35|1@1+ (1,0) [0|1] "" Vector__XXX
 SG_ esc_wheelDirectionRL : 36|2@1+ (1,0) [0|3] ""  PDC
 SG_ esc_wheelDirectionRR : 38|2@1+ (1,0) [0|3] ""  PDC
 SG_ esc_282_rollingCounter : 52|4@1+ (1,0) [0|15] ""  PDC
 SG_ esc_282_checksum : 56|8@1+ (1,0) [0|255] ""  PDC

BO_ 673 BCM_state: 8 GW
 SG_ bcm_turnLampSerialReq : 0|2@1+ (1,0) [0|3] "" Vector__XXX
 SG_ bcm_turnLampFlickerReq : 2|2@1+ (1,0) [0|3] "" Vector__XXX
 SG_ bcm_drlReq : 4|1@1+ (1,0) [0|1] "" Vector__XXX
 SG_ bcm_posLampReq : 5|1@1+ (1,0) [0|1] "" Vector__XXX
 SG_ bcm_lowBeamReq : 6|1@1+ (1,0) [0|1] "" Vector__XXX
 SG_ bcm_highBeamReq : 7|1@1+ (1,0) [0|1] "" Vector__XXX
 SG_ bcm_leftTurnLampReq : 8|1@1+ (1,0) [0|1] "" Vector__XXX
 SG_ bcm_rightTurnLampReq : 9|1@1+ (1,0) [0|1] "" Vector__XXX
 SG_ bcm_hoodSts : 10|1@1+ (1,0) [0|1] ""  IVI,TBOX
 SG_ bcm_hazardLightSts : 11|1@1+ (1,0) [0|1] ""  TBOX
 SG_ bcm_leftTurnLampSwSts : 12|1@1+ (1,0) [0|1] ""  IVI
 SG_ bcm_leftTurnLampSts : 13|1@1+ (1,0) [0|1] ""  ICM,IVI,NVS,TBOX
 SG_ bcm_WipperMaintenanceSts : 14|1@1+ (1,0) [0|1] ""  IVI
 SG_ bcm_pdcSwitchSet : 15|1@1+ (1,0) [0|1] ""  PDC
 SG_ bcm_rightTurnLampSts : 16|1@1+ (1,0) [0|1] ""  ICM,IVI,NVS,TBOX
 SG_ bcm_HornSts : 17|1@1+ (1,0) [0|1] ""  TBOX
 SG_ bcm_brakeLightReq : 18|1@1+ (1,0) [0|0] "" Vector__XXX
 SG_ bcm_rightTurnLampSwSts : 19|1@1+ (1,0) [0|1] ""  IVI
 SG_ bcm_doorFLSts : 20|1@1+ (1,0) [0|1] ""  ICM,IVI,TBOX,WCM
 SG_ bcm_doorFRSts : 21|1@1+ (1,0) [0|1] ""  ICM,IVI,TBOX
 SG_ bcm_doorRLSts : 22|1@1+ (1,0) [0|1] ""  ICM,IVI,TBOX
 SG_ bcm_doorRRSts : 23|1@1+ (1,0) [0|1] ""  ICM,IVI,TBOX
 SG_ bcm_doorFLLockSts : 24|1@1+ (1,0) [0|1] ""  ICM,IVI,TBOX
 SG_ bcm_LeftMirrorSw : 25|1@1+ (1,0) [0|1] "" Vector__XXX
 SG_ bcm_rightMirrorSw : 26|1@1+ (1,0) [0|1] "" Vector__XXX
 SG_ bcm_frontWiperParkingSts : 27|1@1+ (1,0) [0|1] "" Vector__XXX
 SG_ bcm_rearWiperParkingSts : 28|1@1+ (1,0) [0|1] "" Vector__XXX
 SG_ bcm_antiTheftSts : 29|3@1+ (1,0) [0|7] ""  ICM,IVI,TBOX
 SG_ bcm_fuelCapSts : 32|2@1+ (1,0) [0|3] ""  IVI,TBOX
 SG_ bcm_frontWiperSts : 34|3@1+ (1,0) [0|7] ""  IVI,TBOX
 SG_ bcm_chrgCapSts : 37|1@1+ (1,0) [0|1] ""  IVI,TBOX
 SG_ bcm_gunUnlockCtrlReq : 38|1@1+ (1,0) [0|1] "" Vector__XXX
 SG_ bcm_readyReq : 39|1@1+ (1,0) [0|1] ""  IVI
 SG_ bcm_mirrorAdjust : 40|3@1+ (1,0) [0|7] "" Vector__XXX
 SG_ bcm_tailgateOpenSW : 43|1@1+ (1,0) [0|1] "" Vector__XXX
 SG_ bcm_apaOnOffSet : 44|1@1+ (1,0) [0|1] "" Vector__XXX
 SG_ bcm_avmOnOffSet : 45|1@1+ (1,0) [0|1] "" Vector__XXX
 SG_ bcm_driveMode : 46|1@1+ (1,0) [0|1] ""  IVI
 SG_ bcm_parkAutoCloseDRLSts : 47|1@1+ (1,0) [0|1] ""  IVI
 SG_ bcm_HvReq : 48|2@1+ (1,0) [0|3] ""  IVI,TBOX
 SG_ BCM_CloselightReq : 50|1@1+ (1,0) [0|1] "" Vector__XXX
 SG_ bcm_2A1_rollingCounter : 52|4@1+ (1,0) [0|15] ""  NVS
 SG_ bcm_2A1_checksum : 56|8@1+ (1,0) [0|255] ""  NVS

BO_ 674 ESC_state2: 8 GW
 SG_ esc_cddActive : 0|1@1+ (1,0) [0|1] ""  TBOX
 SG_ esc_cddAvailable : 1|1@1+ (1,0) [0|1] "" Vector__XXX
 SG_ esc_cddError : 2|1@1+ (1,0) [0|1] "" Vector__XXX
 SG_ esc_cddTempOff : 3|1@1+ (1,0) [0|1] "" Vector__XXX
 SG_ esc_abaActive : 4|1@1+ (1,0) [0|1] "" Vector__XXX
 SG_ esc_abaAvailable : 5|1@1+ (1,0) [0|1] "" Vector__XXX
 SG_ esc_abpActive : 6|1@1+ (1,0) [0|1] "" Vector__XXX
 SG_ esc_abpAvailable : 7|1@1+ (1,0) [0|1] "" Vector__XXX
 SG_ esc_aebActive : 8|1@1+ (1,0) [0|1] ""  TBOX
 SG_ esc_aebAvailable : 9|1@1+ (1,0) [0|1] "" Vector__XXX
 SG_ esc_awbActive : 10|1@1+ (1,0) [0|1] "" Vector__XXX
 SG_ esc_awbAvailable : 11|1@1+ (1,0) [0|1] "" Vector__XXX
 SG_ esc_vehicleStandstill : 12|2@1+ (1,0) [0|3] ""  TBOX
 SG_ esc_vehicleStandstillValid : 14|1@1+ (1,0) [0|1] ""  TBOX
 SG_ esc_brakelightIlluminate : 15|1@1+ (1,0) [0|1] "" Vector__XXX
 SG_ esc_vlcTorqReq : 16|13@1+ (1,-500) [-500|7690] "N.m"  IVI
 SG_ esc_vlcTorqReqActive : 29|1@1+ (1,0) [0|1] ""  IVI
 SG_ esc_vlcError : 30|1@1+ (1,0) [0|1] ""  IVI
 SG_ esc_vlcAvalible : 31|1@1+ (1,0) [0|1] ""  IVI
 SG_ esc_vlcInterTargetAx : 32|8@1+ (0.05,-7) [-7|5.7] "m/s2"  IVI
 SG_ esc_hmiWarningOn : 40|2@1+ (1,0) [0|3] ""  IVI
 SG_ esc_hmiWarningOn_Q : 42|2@1+ (1,0) [0|3] ""  IVI
 SG_ esc_vlcActive : 48|1@1+ (1,0) [0|1] "" Vector__XXX
 SG_ esc_hbbSts : 49|2@1+ (1,0) [0|3] ""  IVI
 SG_ esc_hbbActive : 51|1@1+ (1,0) [0|1] ""  IVI
 SG_ esc_2A2_rollingCounter : 52|4@1+ (1,0) [0|15] ""  IVI
 SG_ esc_2A2_checksum : 56|8@1+ (1,0) [0|255] ""  IVI

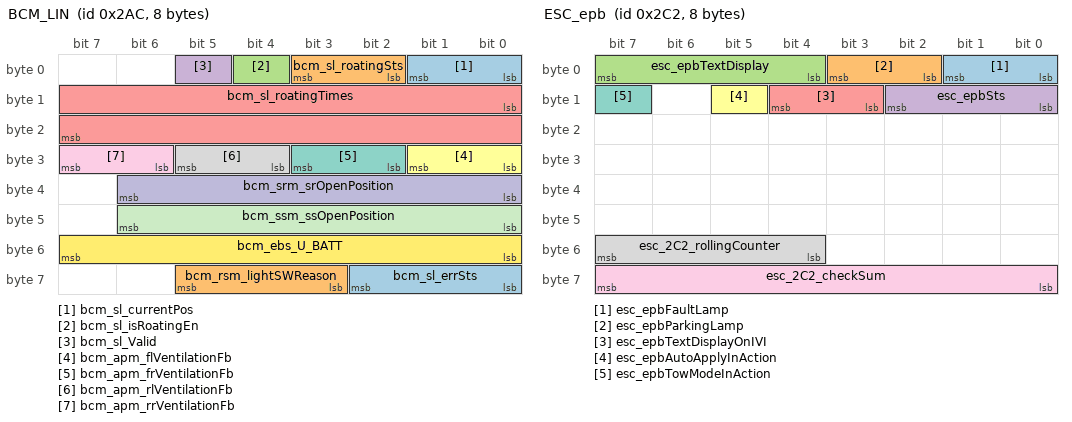
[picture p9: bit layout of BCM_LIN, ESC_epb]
BO_ 684 BCM_LIN: 8 GW
 SG_ bcm_sl_currentPos : 0|2@1+ (1,0) [0|3] ""  IVI,NVS
 SG_ bcm_sl_roatingSts : 2|2@1+ (1,0) [0|3] ""  IVI,NVS
 SG_ bcm_sl_isRoatingEn : 4|1@1+ (1,0) [0|1] ""  IVI,NVS
 SG_ bcm_sl_Valid : 5|1@1+ (1,0) [0|1] ""  IVI,NVS
 SG_ bcm_sl_roatingTimes : 8|16@1+ (1,0) [0|65535] ""  IVI,NVS
 SG_ bcm_apm_flVentilationFb : 24|2@1+ (1,0) [0|3] ""  IVI,TBOX
 SG_ bcm_apm_frVentilationFb : 26|2@1+ (1,0) [0|3] ""  IVI,TBOX
 SG_ bcm_apm_rlVentilationFb : 28|2@1+ (1,0) [0|3] ""  IVI,TBOX
 SG_ bcm_apm_rrVentilationFb : 30|2@1+ (1,0) [0|3] ""  IVI,TBOX
 SG_ bcm_srm_srOpenPosition : 32|7@1+ (1,0) [0|100] ""  IVI
 SG_ bcm_ssm_ssOpenPosition : 40|7@1+ (1,0) [0|100] ""  IVI
 SG_ bcm_ebs_U_BATT : 48|8@1+ (0.1,0) [0|25] ""  ICM,IVI,NVS,TBOX
 SG_ bcm_sl_errSts : 56|3@1+ (1,0) [0|7] ""  IVI
 SG_ bcm_rsm_lightSWReason : 59|3@1+ (1,0) [0|7] ""  IVI,NVS

BO_ 705 BCM_peps: 8 GW
 SG_ bcm_pepsPowerMode : 0|3@1+ (1,0) [0|7] ""  AMP,ETC,ICM,IVI,NVS,TBOX,VSP,WCM
 SG_ bcm_IMMOReleaseIndication : 3|1@1+ (1,0) [0|1] ""  IVI
 SG_ bcm_pepsKeyNotInCarInd : 4|1@1+ (1,0) [0|1] ""  IVI
 SG_ bcm_keyValid : 5|2@1+ (1,0) [0|3] "" Vector__XXX
 SG_ bcm_pepsKeySerchFailInd : 7|1@1+ (1,0) [0|1] ""  IVI
 SG_ bcm_pepsKeyCloserInd : 8|1@1+ (1,0) [0|1] ""  IVI
 SG_ bcm_pepsFobLowBatWarning : 9|1@1+ (1,0) [0|1] ""  IVI
 SG_ bcm_pepsPowerRelayErrWarning : 10|1@1+ (1,0) [0|1] ""  IVI
 SG_ bcm_RearWindowLockSts : 11|1@1+ (1,0) [0|1] ""  IVI
 SG_ bcm_IndicationPressBrake : 12|1@1+ (1,0) [0|1] ""  IVI
 SG_ bcm_LowFrequencyAntennaFault : 13|1@1+ (1,0) [0|1] ""  IVI
 SG_ bcm_remoteMode : 14|2@1+ (1,0) [0|3] ""  IVI,TBOX
 SG_ bcm_ble_response : 16|2@1+ (1,0) [0|3] "" Vector__XXX
 SG_ bcm_autoGlassCloseWarning : 18|1@1+ (1,0) [0|1] ""  IVI,TBOX
 SG_ bcm_rke_fuelPortCapOpenCtrl : 19|2@1+ (1,0) [0|3] "" Vector__XXX
 SG_ bcm_fhcActionLeftFront : 24|2@1+ (1,0) [0|3] "" Vector__XXX
 SG_ bcm_fhcActionRightFront : 26|2@1+ (1,0) [0|3] "" Vector__XXX
 SG_ bcm_fhcActionLeftRear : 28|2@1+ (1,0) [0|3] "" Vector__XXX
 SG_ bcm_fhcActionRightRear : 30|2@1+ (1,0) [0|3] "" Vector__XXX
 SG_ bcm_12VBatterySOC : 32|8@1+ (1,0) [0|100] "%"  IVI,TBOX
 SG_ bcm_pepsKeyInCarInd : 40|1@1+ (1,0) [0|1] ""  IVI,TBOX
 SG_ bcm_tbox_response : 48|2@1+ (1,0) [0|3] ""  ICM,IVI,TBOX
 SG_ bcm_approachingUnlockFedb : 54|2@1+ (1,0) [0|3] ""  IVI
 SG_ bcm_followMeHomeFedb : 56|3@1+ (1,0) [0|7] ""  IVI
 SG_ bcm_awayLockFeedback : 59|2@1+ (1,0) [0|3] ""  IVI
 SG_ bcm_MirrorAutoFoldUnfoldSts : 61|2@1+ (1,0) [0|3] ""  IVI

BO_ 706 ESC_epb: 8 GW
 SG_ esc_epbFaultLamp : 0|2@1+ (1,0) [0|3] ""  IVI,PDC
 SG_ esc_epbParkingLamp : 2|2@1+ (1,0) [0|3] ""  IVI
 SG_ esc_epbTextDisplay : 4|4@1+ (1,0) [0|15] ""  IVI
 SG_ esc_epbSts : 8|3@1+ (1,0) [0|7] ""  ICM,IVI,PDC,TBOX
 SG_ esc_epbTextDisplayOnIVI : 11|2@1+ (1,0) [0|3] ""  IVI
 SG_ esc_epbAutoApplyInAction : 13|1@1+ (1,0) [0|1] "" Vector__XXX
 SG_ esc_epbTowModeInAction : 15|1@1+ (1,0) [0|1] "" Vector__XXX
 SG_ esc_2C2_rollingCounter : 52|4@1+ (1,0) [0|15] ""  ICM,PDC
 SG_ esc_2C2_checkSum : 56|8@1+ (1,0) [0|255] "N/A"  ICM,PDC

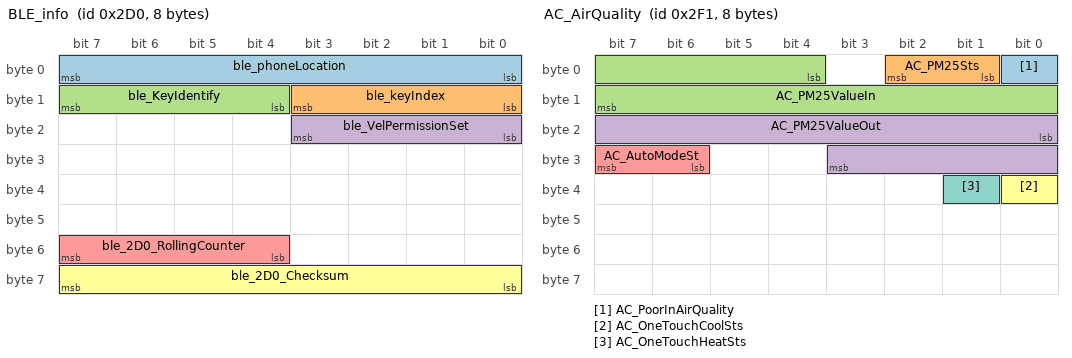
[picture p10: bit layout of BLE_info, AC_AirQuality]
BO_ 720 BLE_info: 8 GW
 SG_ ble_phoneLocation : 0|8@1+ (1,0) [0|255] ""  IVI
 SG_ ble_keyIndex : 8|4@1+ (1,0) [0|15] "" Vector__XXX
 SG_ ble_KeyIdentify : 12|4@1+ (1,0) [0|15] ""  IVI
 SG_ ble_VelPermissionSet : 16|4@1+ (1,0) [0|15] "" Vector__XXX
 SG_ ble_2D0_RollingCounter : 52|4@1+ (1,0) [0|15] ""  IVI
 SG_ ble_2D0_Checksum : 56|8@1+ (1,0) [0|255] ""  IVI

BO_ 753 AC_AirQuality: 8 GW
 SG_ AC_PoorInAirQuality : 0|1@1+ (1,0) [0|1] "" Vector__XXX
 SG_ AC_PM25Sts : 1|2@1+ (1,0) [0|3] ""  IVI
 SG_ AC_PM25ValueIn : 4|12@1+ (1,0) [0|1575] ""  IVI
 SG_ AC_PM25ValueOut : 16|12@1+ (1,0) [0|1575] ""  IVI
 SG_ AC_AutoModeSt : 30|2@1+ (1,0) [0|3] ""  IVI
 SG_ AC_OneTouchCoolSts : 32|1@1+ (1,0) [0|1] ""  TBOX
 SG_ AC_OneTouchHeatSts : 33|1@1+ (1,0) [0|1] ""  TBOX

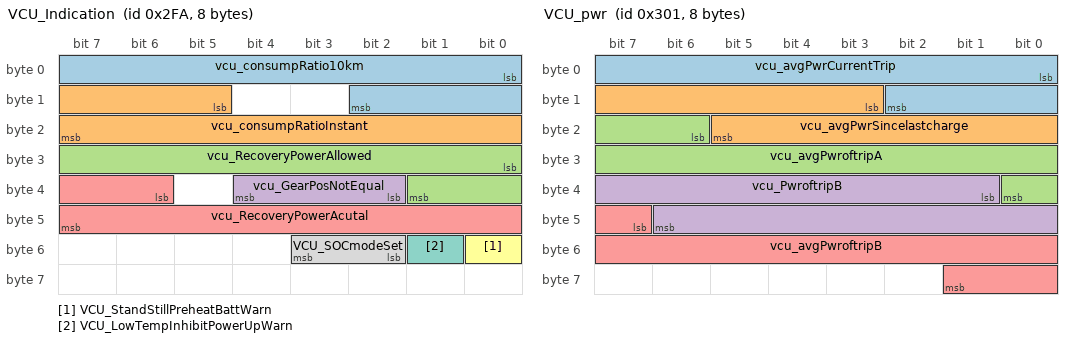
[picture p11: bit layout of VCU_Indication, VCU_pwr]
BO_ 762 VCU_Indication: 8 GW
 SG_ vcu_consumpRatio10km : 0|11@1+ (0.1,-50) [-50|150] "KWh/100km"  TBOX
 SG_ vcu_consumpRatioInstant : 13|11@1+ (0.1,-50) [-50|150] "KWh/100km"  IVI,TBOX
 SG_ vcu_RecoveryPowerAllowed : 24|10@1+ (0.5,0) [0|511] "kW"  IVI
 SG_ vcu_GearPosNotEqual : 34|3@1+ (1,0) [0|7] ""  IVI
 SG_ vcu_RecoveryPowerAcutal : 38|10@1+ (0.5,0) [0|511] "kW"  IVI
 SG_ VCU_StandStillPreheatBattWarn : 48|1@1+ (1,0) [0|1] ""  IVI
 SG_ VCU_LowTempInhibitPowerUpWarn : 49|1@1+ (1,0) [0|1] ""  IVI
 SG_ VCU_SOCmodeSet : 50|2@1+ (1,0) [0|3] ""  IVI

BO_ 769 VCU_pwr: 8 GW
 SG_ vcu_avgPwrCurrentTrip : 0|11@1+ (0.1,-50) [-50|150] "kWh/100km"  IVI,TBOX
 SG_ vcu_avgPwrSincelastcharge : 11|11@1+ (0.1,-50) [-50|150] "kWh/100km"  IVI,TBOX
 SG_ vcu_avgPwroftripA : 22|11@1+ (0.1,-50) [-50|150] "kWh/100km"  IVI
 SG_ vcu_PwroftripB : 33|14@1+ (0.1,-500) [-500|1000] "kWh"  IVI
 SG_ vcu_avgPwroftripB : 47|11@1+ (0.1,-50) [-50|150] "kWh/100km"  IVI

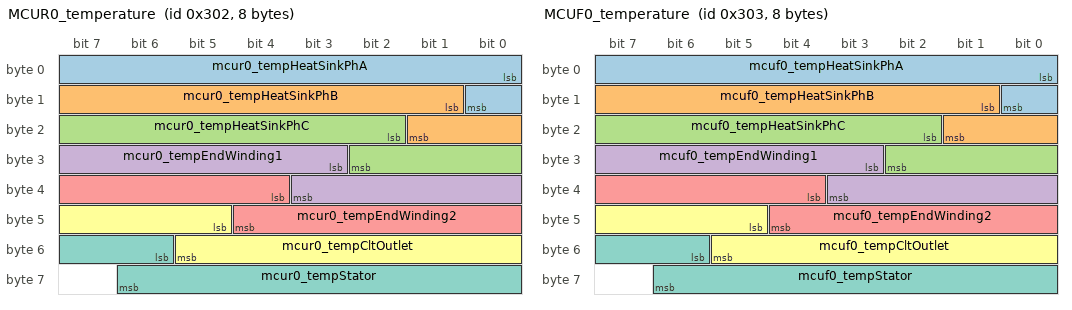
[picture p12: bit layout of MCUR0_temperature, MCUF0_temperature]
BO_ 770 MCUR0_temperature: 8 GW
 SG_ mcur0_tempHeatSinkPhA : 0|9@1+ (0.5,-40) [-40|215.5] "℃"  TBOX
 SG_ mcur0_tempHeatSinkPhB : 9|9@1+ (0.5,-40) [-40|215.5] "℃" Vector__XXX
 SG_ mcur0_tempHeatSinkPhC : 18|9@1+ (0.5,-40) [-40|215.5] "℃" Vector__XXX
 SG_ mcur0_tempEndWinding1 : 27|9@1+ (0.5,-40) [-40|215.5] "℃"  TBOX
 SG_ mcur0_tempEndWinding2 : 36|9@1+ (0.5,-40) [-40|215.5] "℃" Vector__XXX
 SG_ mcur0_tempCltOutlet : 45|9@1+ (0.5,-40) [-40|215.5] "℃"  TBOX
 SG_ mcur0_tempStator : 54|9@1+ (0.5,-40) [-40|215.5] "℃"  TBOX

BO_ 771 MCUF0_temperature: 8 GW
 SG_ mcuf0_tempHeatSinkPhA : 0|9@1+ (0.5,-40) [-40|215.5] "℃"  TBOX
 SG_ mcuf0_tempHeatSinkPhB : 9|9@1+ (0.5,-40) [-40|215.5] "℃" Vector__XXX
 SG_ mcuf0_tempHeatSinkPhC : 18|9@1+ (0.5,-40) [-40|215.5] "℃" Vector__XXX
 SG_ mcuf0_tempEndWinding1 : 27|9@1+ (0.5,-40) [-40|215.5] "℃"  TBOX
 SG_ mcuf0_tempEndWinding2 : 36|9@1+ (0.5,-40) [-40|215.5] "℃" Vector__XXX
 SG_ mcuf0_tempCltOutlet : 45|9@1+ (0.5,-40) [-40|215.5] "℃"  TBOX
 SG_ mcuf0_tempStator : 54|9@1+ (0.5,-40) [-40|215.5] "℃"  TBOX

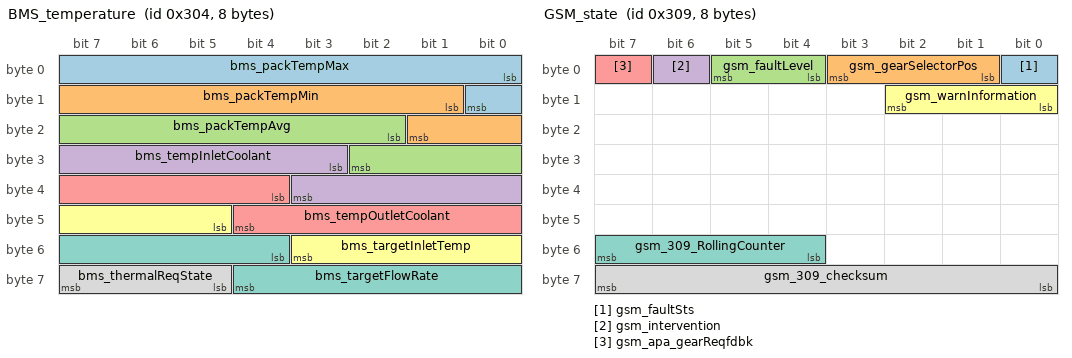
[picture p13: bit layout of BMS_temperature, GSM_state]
BO_ 772 BMS_temperature: 8 GW
 SG_ bms_packTempMax : 0|9@1+ (0.5,-40) [-40|125] "℃"  TBOX
 SG_ bms_packTempMin : 9|9@1+ (0.5,-40) [-40|125] "℃"  TBOX
 SG_ bms_packTempAvg : 18|9@1+ (0.5,-40) [-40|125] "℃"  TBOX
 SG_ bms_tempInletCoolant : 27|9@1+ (0.5,-40) [-40|125] "℃"  TBOX
 SG_ bms_tempOutletCoolant : 36|9@1+ (0.5,-40) [-40|125] "℃"  TBOX
 SG_ bms_targetInletTemp : 45|7@1+ (0.5,-20) [-20|40] "℃"  TBOX
 SG_ bms_targetFlowRate : 52|9@1+ (0.5,0) [0|100] "L/min"  TBOX
 SG_ bms_thermalReqState : 61|3@1+ (1,0) [0|7] ""  TBOX

BO_ 777 GSM_state: 8 GW
 SG_ gsm_faultSts : 0|1@1+ (1,0) [0|1] "" Vector__XXX
 SG_ gsm_gearSelectorPos : 1|3@1+ (1,0) [0|7] ""  IVI
 SG_ gsm_faultLevel : 4|2@1+ (1,0) [0|3] ""  IVI
 SG_ gsm_intervention : 6|1@1+ (1,0) [0|1] "" Vector__XXX
 SG_ gsm_apa_gearReqfdbk : 7|1@1+ (1,0) [0|1] "" Vector__XXX
 SG_ gsm_warnInformation : 8|3@1+ (1,0) [0|7] ""  IVI
 SG_ gsm_309_RollingCounter : 52|4@1+ (1,0) [0|15] ""  IVI
 SG_ gsm_309_checksum : 56|8@1+ (1,0) [0|255] ""  IVI

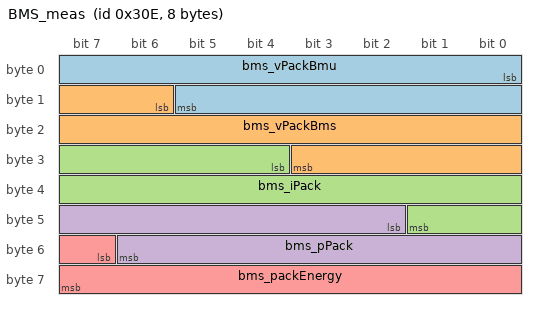
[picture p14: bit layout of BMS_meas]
BO_ 782 BMS_meas: 8 GW
 SG_ bms_vPackBmu : 0|14@1+ (0.05,0) [0|800] "V"  IVI,TBOX
 SG_ bms_vPackBms : 14|14@1+ (0.05,0) [0|800] "V"  IVI,TBOX
 SG_ bms_iPack : 28|14@1+ (0.2,-600) [-600|2500] "A"  IVI,TBOX
 SG_ bms_pPack : 42|13@1+ (0.25,-200) [-200|1000] "KW"  IVI,TBOX
 SG_ bms_packEnergy : 55|9@1+ (0.2,0) [0|100] "kWh" Vector__XXX

BO_ 793 SWM_Set: 8 GW
 SG_ swm_Photo : 0|1@1+ (1,0) [0|1] ""  ICM,IVI
 SG_ swm_ACCSW : 1|1@1+ (1,0) [0|1] ""  IVI
 SG_ swm_ACCSWValid : 2|1@1+ (1,0) [0|1] ""  IVI
 SG_ swm_ACCRESorAdd : 3|1@1+ (1,0) [0|1] ""  IVI
 SG_ swm_ACCRESorAddValid : 4|1@1+ (1,0) [0|1] ""  IVI
 SG_ swm_ACCSETorSub : 5|1@1+ (1,0) [0|1] ""  IVI
 SG_ swm_ACCSETorSubValid : 6|1@1+ (1,0) [0|1] ""  IVI
 SG_ swm_ACCInterval : 7|1@1+ (1,0) [0|1] ""  IVI
 SG_ swm_ACCIntervalValid : 8|1@1+ (1,0) [0|1] ""  IVI
 SG_ swm_CNCL : 11|1@1+ (1,0) [0|1] ""  IVI
 SG_ swm_CNCLValid : 12|1@1+ (1,0) [0|1] ""  IVI
 SG_ swm_TJAHWASwtich : 13|1@1+ (1,0) [0|1] ""  IVI
 SG_ swm_TJAHWASwtichValid : 14|1@1+ (1,0) [0|1] ""  IVI
 SG_ swm_menu : 15|1@1+ (1,0) [0|1] ""  IVI
 SG_ swm_OK : 16|1@1+ (1,0) [0|1] ""  IVI
 SG_ swm_upAdd : 17|1@1+ (1,0) [0|1] ""  IVI
 SG_ swm_downMinus : 18|1@1+ (1,0) [0|1] ""  IVI
 SG_ swm_leftLast : 19|1@1+ (1,0) [0|1] ""  IVI
 SG_ swm_rightNext : 20|1@1+ (1,0) [0|1] ""  IVI
 SG_ swm_nvsSwitch : 21|1@1+ (1,0) [0|1] ""  IVI,NVS
 SG_ swm_phone : 22|1@1+ (1,0) [0|1] ""  IVI
 SG_ swm_voice : 23|1@1+ (1,0) [0|1] ""  IVI
 SG_ swm_highbeam : 24|1@1+ (1,0) [0|1] ""  IVI
 SG_ swm_overtakingLight : 25|1@1+ (1,0) [0|1] ""  IVI
 SG_ swm_turnSW : 26|2@1+ (1,0) [0|3] ""  IVI
 SG_ swm_changeLaneSW : 28|2@1+ (1,0) [0|3] ""  IVI
 SG_ swm_frontWashing : 30|1@1+ (1,0) [0|1] ""  IVI
 SG_ swm_frontWiper : 32|3@1+ (1,0) [0|7] ""  IVI
 SG_ swm_backWiper : 35|2@1+ (1,0) [0|3] ""  IVI
 SG_ swm_backWashing : 37|1@1+ (1,0) [0|1] ""  IVI
 SG_ swm_autoWiper : 40|3@1+ (1,0) [0|7] ""  IVI
 SG_ swm_trumpet : 43|1@1+ (1,0) [0|1] ""  IVI
 SG_ swm_userdefined : 44|1@1+ (1,0) [0|1] ""  IVI
 SG_ swm_CCSwitch : 45|1@1+ (1,0) [0|1] ""  IVI
 SG_ swm_CCSwitchInvalid : 46|1@1+ (1,0) [0|1] ""  IVI
 SG_ swm_319_Rollingcounter : 52|4@1+ (1,0) [0|15] ""  IVI
 SG_ swm_319_Checksum : 56|8@1+ (1,0) [0|255] ""  IVI

BO_TX_BU_ 1801 : GW,TBOX;
BO_TX_BU_ 1805 : GW,TBOX;
BO_TX_BU_ 1808 : GW,TBOX;
BO_TX_BU_ 1815 : GW,TBOX;
BO_TX_BU_ 1829 : GW,TBOX;
BO_TX_BU_ 1850 : GW,TBOX;
BO_TX_BU_ 1857 : GW,TBOX;
BO_TX_BU_ 1865 : GW,TBOX;

CM_ "Version:V1.0,Date:2019/8/31,Author:付余,Review:,Approval:,Description:(ASC/VCU/APA/AVM/EPS/ESC/BCM/IVI/OBC/TBOX/POT/AC/MPC/MRR)CHACAN中节点
1、删除ASC原发送报文和信号，新建发送的报文ASC_state1、ASC_state2【ASC为新增件】
2、根据ASC的子系统功能规范确定ASC要接收的信号，并在这些信号的接收方中添加ASC
3、在ASC发送的信号的接收方中添加MPC、MRR、APA；并在ASC发送的表示故障、高度、状态、开关的信号接收方中添加AVM
4、报文ASC_state1中的信号asc_ascSysSts的信号值描述值增加0x4:Function Shutdown（随速调节功能屏蔽）
5、修改报文ASC_state2中的4个车轮高度信号的内容【信号的长度由11bit变成12bit、最小最大值由-45/45变成-150/150、单位由deg变成mm】
6、报文ASC_state2中表示限速请求的信号asc_limitingVelocityRequest排布到报文ASC_state1中
7、ASC接收BCM发送的报文BCM_state（0x2AE）中的信号bcm_doorFLLockSts
8、ASC接收BCM发送的报文报文BCM_peps（0x2CE）中的信号bcm_remoteMode
9、ASC接收BCM发送的报文BCM_state2中表示迎宾状态的信号bcm_welcomeSts;
Version:V1.0,Date:2019/9/4,Author:付余,Review:,Approval:,Description:(ACU/ESC/EPS/VCU/BCM/MRR)";
CM_ SG_ 1801 Diag_PhyReq_ICM_Data "Diagnostic Physical Request Data to ICM";
CM_ SG_ 1805 Diag_PhyReq_WCM_Data "Diagnostic Physical Request Data to WCM";
CM_ SG_ 1808 Diag_PhyReq_VSP_Data "Diagnostic Physical Request Data to VSP";
CM_ SG_ 1815 Diag_PhyReq_PDC_Data "Diagnostic Physical Request Data to PDC";
CM_ SG_ 1829 Diag_PhyReq_IVI_Data "Diagnostic Physical Request Data to IVI";
CM_ SG_ 1850 Diag_PhyReq_NVS_Data "Diagnostic Physical Request Data to NVS";
CM_ SG_ 1857 Diag_PhyReq_ETC_Data "Diagnostic Physical Request Data to ETC";
CM_ SG_ 1865 Diag_PhyReq_AMP_Data "Diagnostic Physical Request Data to AMP";
CM_ SG_ 1029 amp_weightlowFrqSetSts "重低音设置反馈";
CM_ SG_ 1029 AMP_STATUS_OVERVOLTAGE "AMP侦测电压>18V";
CM_ SG_ 1029 AMP_STATUS_UNDERVOLTAGE "AMP侦测电压<9V";
CM_ SG_ 1029 AMP_STATUS_OVERTEMP "温度超出范围，温度>85℃";
CM_ SG_ 1029 AMP_STATUS_NO_A2B "AMP没有A2B信号";
CM_ SG_ 1029 AMP_ZERO_SIGNAL_FROM_A2B "AMP没有收到任何A2B信号";
CM_ SG_ 1029 AMP_NO_EQ_SET "没有设置EQ";
CM_ SG_ 1030 amp_vehicleSpeedCompModeSts "Vehicle Speed Compensation Mode (on/off) request";
CM_ SG_ 1030 amp_highFrqSetSts "AMP feedback high frequency audio set";
CM_ SG_ 1030 amp_mediaVolSts "Media Volume Adjustment  (A2B Ch 5~6)";
CM_ SG_ 1030 amp_globalMuteSts "Mute all speakers";
CM_ SG_ 1030 amp_midFrqSetSts "Mid Frequency Audio Status";
CM_ SG_ 1030 amp_lowFrqSetSts "AMP feedback low frequency audio set";
CM_ SG_ 1030 amp_dyaudioSoundFeatureSts "音响模式";
CM_ SG_ 1030 amp_loudnessSts "声音补偿状态";
CM_ SG_ 1030 amp_soundFieldSts "声场状态";
CM_ SG_ 1030 amp_audioBlcSts "Left/Right Audio Balance Status";
CM_ SG_ 1030 amp_audioFaderSts "Front/Rear Audio Fader Status";
CM_ SG_ 1609 AMP_RMR "Repeat Message Request";
CM_ SG_ 1609 AMP_AWB "Active Wakeup Bit";
CM_ SG_ 1993 Diag_Resp_AMP_Data "Diagnostic Physical response Data from AMP";
CM_ SG_ 1014 etc_VINIdentification "VIN码认证状态";
CM_ SG_ 1014 etc_disassemblySts "ETC激活状态";
CM_ SG_ 1014 etc_lockSts "ETC锁定状态";
CM_ SG_ 1014 etc_detect "ETC自检状态";
CM_ SG_ 1026 etc_amountDataNumFdb "交易数据编号（用于读取历史记录，预留）";
CM_ SG_ 1026 etc_tranAmount1 "ETC本次交易金额";
CM_ SG_ 1026 etc_tranAmount2 "ETC本次交易金额";
CM_ SG_ 1026 etc_tranAmount3 "ETC本次交易金额";
CM_ SG_ 1026 etc_tranAmount4 "ETC本次交易金额";
CM_ SG_ 1026 etc_roadNetN1 "省级行政区划分代码";
CM_ SG_ 1026 etc_roadNetN2 "省级网络编码";
CM_ SG_ 1026 etc_tranStauts "交易状态（成功/失败）";
CM_ SG_ 1027 etc_timeDataNumFdb "交易数据编号（用于读取历史记录，预留）";
CM_ SG_ 1027 etc_unixTime1 "交易时间";
CM_ SG_ 1027 etc_unixTime2 "交易时间";
CM_ SG_ 1027 etc_unixTime3 "交易时间";
CM_ SG_ 1027 etc_unixTime4 "交易时间";
CM_ SG_ 1027 etc_stationN1 "网内公路序号";
CM_ SG_ 1027 etc_stationN2 "收费站编号";
CM_ SG_ 1027 etc_dataSts "高速出入口状态";
CM_ SG_ 1553 ETC_RMR "Repeat Message Request";
CM_ SG_ 1553 ETC_AWB "Active Wakeup Bit";
CM_ SG_ 1985 Diag_Resp_ETC_Data "Diagnostic Physical response Data from ETC";
CM_ SG_ 16 ble_rke_lockCtrlReq "蓝牙遥控解闭锁请求";
CM_ SG_ 16 ble_rke_tailgateCtrlReq "蓝牙遥控后背门请求";
CM_ SG_ 16 ble_rke_carSearchReq "蓝牙遥控寻车请求";
CM_ SG_ 16 ble_rke_sunRoofGlassCmd "蓝牙遥控天窗请求";
CM_ SG_ 16 ble_rke_winCtrlReq "蓝牙遥控车窗请求";
CM_ SG_ 16 ble_rke_chrgCapCtrlReq "蓝牙遥控充电口盖解锁请求";
CM_ SG_ 16 ble_dvrTakePicCtrl "蓝牙DVR拍照请求";
CM_ SG_ 16 ble_welcomeCmd "蓝牙钥匙迎宾命令";
CM_ SG_ 16 ble_easyEntryManualSw "蓝牙钥匙手动悬架升降开关";
CM_ SG_ 16 ble_rke_chrgGunUnlockCtrlReq "蓝牙钥匙充电枪解锁";
CM_ SG_ 16 ble_rke_fuelPortCapOpenCtrl "加油口盖蓝牙控制";
CM_ SG_ 20 bms_CellCnt "Cell counter.";
CM_ SG_ 20 bms_ModuleCnt "Module counter.";
CM_ SG_ 20 bms_packThermistorCnt "Pack thermistor counter.";
CM_ SG_ 20 bms_cellThermistorCnt "Cell thermistor counter.";
CM_ SG_ 20 bms_cellTemperatureDifferenceHig "Cell temperature difference high.";
CM_ SG_ 20 bms_batteryOverTemperature "Battery over temperature.";
CM_ SG_ 20 bms_overVoltage "Over voltage warming.";
CM_ SG_ 20 bms_lowVoltage "Low voltage warming.";
CM_ SG_ 20 bms_lowSoc "Low SOC warming";
CM_ SG_ 20 bms_cellOverVoltage "Cell over voltage.";
CM_ SG_ 20 bms_cellLowVoltage "Cell low voltage warming.";
CM_ SG_ 20 bms_highSoc "High SOC warming.";
CM_ SG_ 20 bms_socStepChange "Warning for battery pack SOC step change.";
CM_ SG_ 20 bms_chargerMismatch "Charger mismatch.";
CM_ SG_ 20 bms_cellOutOfBalance "Cell out of balance.";
CM_ SG_ 20 bms_isolationFault "Isolation fault.";
CM_ SG_ 20 bms_hvilFault "High voltage interlock fault.";
CM_ SG_ 20 bms_batteryOverCharge "Battery over charge.";
CM_ SG_ 65 bcm_challengeFrame1 "BCM challenge Frame1.";
CM_ SG_ 81 bcm_failCode "Remote Control Fail Code";
CM_ SG_ 273 vcu_gear "Vehicle gear.";
CM_ SG_ 273 vcu_state "VCU state.";
CM_ SG_ 273 vcu_stateCmd_mcur0 "VCU State command for MCUR0.";
CM_ SG_ 273 vcu_stateCmd_mcuf0 "VCU State command for MCUF0.";
CM_ SG_ 273 vcu_stateCmd_bms "VCU State command for BMS.";
CM_ SG_ 273 vcu_accelPos "Acceleration pedal position.";
CM_ SG_ 273 vcu_chargePortIsConnected "Charge portIs connected.";
CM_ SG_ 273 vcu_brakePedalPressed "Brake pedal pressed.";
CM_ SG_ 273 vcu_sysTrqLmtVehMin "The system limits the minimum torque of the vehicle.";
CM_ SG_ 273 vcu_BrakeWarning "Brake warning.";
CM_ SG_ 273 vcu_sysTrqLmtVehMax "The system limits the maximum torque of the vehicle.";
CM_ SG_ 273 vcu_accelPosValid "Acceleration pedal position valid.";
CM_ SG_ 273 vcu_chrgAllowed_bms "Charge request allowed for BMS.";
CM_ SG_ 273 vcu_111_RollingCounter "State counter.";
CM_ SG_ 273 vcu_111_Checksum "State checksum.";
CM_ SG_ 276 bms_state "BMS state.";
CM_ SG_ 276 bms_dcChargeState "DC charge state.";
CM_ SG_ 276 bms_acChargeState "AC charge state.";
CM_ SG_ 276 bms_hvil "High voltage interlock.";
CM_ SG_ 276 bms_isolationState "Isolation state.";
CM_ SG_ 276 bms_contactorState "Contactor state.";
CM_ SG_ 276 bms_chargeInhibit "Charge inhibit.";
CM_ SG_ 276 bms_acChargeConnection "AC charge connection.";
CM_ SG_ 276 bms_dcChargeConnection "DC charge connection.";
CM_ SG_ 276 bms_alertLevel "Alert level.";
CM_ SG_ 276 bms_authenticationResult "Authentication result.";
CM_ SG_ 276 bms_chargeReq "Charge request.";
CM_ SG_ 276 bms_battWarmState "Battery warm state.";
CM_ SG_ 276 bms_ptcEna "Battery PTC enable.";
CM_ SG_ 276 bms_faultHvShutdownReq "High voltage fault shutdown request.";
CM_ SG_ 276 bms_114_Rollingcounter "State counter.";
CM_ SG_ 276 bms_114_Checksum "State checksum.";
CM_ SG_ 288 mcur0_torqueEst "MCU R0 estimated torque.";
CM_ SG_ 288 mcuf0_torqueAvblMinVeh "MCU F0 available torque min in vehicle frame.";
CM_ SG_ 288 ecu_ToltalFaultNum "ECU Toltal Fault Number.";
CM_ SG_ 288 mcur0_0x102_timeoutFlag "GW信号指示MCUR0节点在源网段是否超时。
指示以下信号是否超时：
1. mcur0_torqueEst";
CM_ SG_ 288 mcuf0_0x103_timeoutFlag "GW信号指示MCUF0节点在源网段是否超时。
指示以下信号是否超时：
1. mcuf0_torqueAvblMinVeh";
CM_ SG_ 288 ecu_0x38B_timeoutFlag "GW信号指示ECU节点在源网段是否超时。
指示以下信号是否超时：
1. ecu_tankState（BOCAN判断该信号）
2. ecu_ToltalFaultNum（INFOCAN判断该信号）";
CM_ SG_ 288 mcuf0_torqueEst "MCU F0 estimated torque.";
CM_ SG_ 288 ecu_12vBattVolt "12v Power Supply voltage.";
CM_ SG_ 290 esc_wheelSpeedRL "Rear left wheel speed .";
CM_ SG_ 290 esc_wheelSpeedRLValid "Rear left wheel speed front valid signal.";
CM_ SG_ 290 esc_wheelSpeedRR "Rear right wheel speed.";
CM_ SG_ 290 esc_wheelSpeedRRValid "Rear right wheel speed front valid signal.";
CM_ SG_ 290 esc_122_rollingCounter "every message increments the counter.";
CM_ SG_ 290 esc_122_checksum "CRC8, checksum.";
CM_ SG_ 294 bms_revErrAmount "Error Amount.";
CM_ SG_ 294 bms_revErrNO "Error number.";
CM_ SG_ 294 bms_chargeEndNo "charge end number.";
CM_ SG_ 294 bms_batVoltagefault "BMS battery Voltage fault.";
CM_ SG_ 294 bms_HVPack "High voltage pack .";
CM_ SG_ 294 bms_fastChargeTap1 "fast Charge temperature1.";
CM_ SG_ 294 bms_fastChargeTap2 "fast Charge temperature2.";
CM_ SG_ 304 esc_longAcceleration "longitudinal acceleration signal.";
CM_ SG_ 304 esc_yawRateValid "Yaw rate valid signal.
clockwise is negative；counterclockwise is positive";
CM_ SG_ 304 asc_autoEasyEntryFb "IVI自动便利上下车设置反馈";
CM_ SG_ 304 apa_WarningReq "APA sound alarm request.
APA声音提醒";
CM_ SG_ 304 esc_lateralAcceleration "Laterak acceleration signal.
clockwise is negative；counterclockwise is positive";
CM_ SG_ 304 asc_driveModeFb "驾驶模式反馈信号";
CM_ SG_ 304 esc_yawRate "Yaw rate.
clockwise is negative；counterclockwise is positive";
CM_ SG_ 304 asc_ascSysSts "空气弹簧系统当前状态";
CM_ SG_ 304 asc_maintainMode "indicte the AirS is in maintain mode or not.";
CM_ SG_ 304 asc_ASC_errorSts "空气弹簧系统故障";
CM_ SG_ 304 ASC_SusTempAdjustStatus "空气悬架系统暂时不可调节，比如：车门开启，压缩机过热，气罐压力无法支持便捷上下车功能。";
CM_ SG_ 304 asc_highwayMode "自动设置高速公路调节功能的反馈信号";
CM_ SG_ 304 ASC_SuspensionCurrentLevel "当前车身高度等级";
CM_ SG_ 304 asc_easyEntryEnable "easy Entry Enable.";
CM_ SG_ 304 apa_funcSts "APA function status.";
CM_ SG_ 320 hcm_0x100_timeoutFlag "GW信号指示HCM节点在源网段是否超时。
指示以下信号是否超时：
1. hcm_leftHighBeamFaultSt
2. hcm_adbFuctionStsLt
3. hcm_middleLeftPositionLampFault
4. hcm_hcmHeightSetLt
5. hcm_leftHighBeamLedsFaultSt
6. hcm_leftHighBeamDriFaultWarning
7. hcm_leftLowBeamFaultSt
8. hcm_turnLampWarningLt
9. hcm_positionLampWarningLt
10. hcm_dayTimeRunningLampWarningLt";
CM_ SG_ 320 hcm_0x110_timeoutFlag "GW信号指示HCM节点在源网段是否超时。
指示以下信号是否超时：
1. hcm_rightHighBeamFaultSt
2. hcm_adbFuctionStsRt
3. hcm_middleRightPositionLampFault
4. hcm_hcmHeightSetRt
5. hcm_rightHighBeamLedsFaultSt
6. hcm_rightHighBeamDriFaultWarning
7. hcm_rightLowBeamFaultSt
8. hcm_turnLampWarningRt
9. hcm_positionLampWarningRt
10. hcm_dayTimeRunningLampWarningRt";
CM_ SG_ 320 hcm_leftHighBeamFaultSt "left High beam fault status.";
CM_ SG_ 320 hcm_adbFuctionStsLt "The status of left ADB module.";
CM_ SG_ 320 hcm_rightHighBeamFaultSt "Right High beam fault status.";
CM_ SG_ 320 hcm_adbFuctionStsRt "The status of right ADB module.";
CM_ SG_ 320 AC_CompressorActualPower "AC compressor actual power.";
CM_ SG_ 320 ac_0x3A6_timeoutFlag "GW信号指示AC节点在源网段是否超时。
指示以下信号是否超时：
1. AC_CompressorActualPower";
CM_ SG_ 320 hcm_middleLeftPositionLampFault "前部中间位置灯故障";
CM_ SG_ 320 hcm_middleRightPositionLampFault "前部中间位置灯故障";
CM_ SG_ 320 hcm_hcmHeightSetLt "left hcm Height Set";
CM_ SG_ 320 hcm_hcmHeightSetRt "right hcm Height Set";
CM_ SG_ 320 hcm_leftHighBeamLedsFaultSt "Left light source module LED fault status alarm.";
CM_ SG_ 320 hcm_leftHighBeamDriFaultWarning "Left HCM fault alarm.";
CM_ SG_ 320 hcm_leftLowBeamFaultSt "left low beam fault status.";
CM_ SG_ 320 hcm_turnLampWarningLt "left turn Lamp abnormal warning.";
CM_ SG_ 320 hcm_positionLampWarningLt "位置灯异常提醒";
CM_ SG_ 320 hcm_dayTimeRunningLampWarningLt "日行灯异常提醒";
CM_ SG_ 320 hcm_rightHighBeamLedsFaultSt "Right light source module LED fault status alarm.";
CM_ SG_ 320 hcm_rightHighBeamDriFaultWarning "Right HCM fault alarm.";
CM_ SG_ 320 hcm_rightLowBeamFaultSt "Right low beam fault status.";
CM_ SG_ 320 hcm_turnLampWarningRt "Right turn Lamp abnormal warning.";
CM_ SG_ 320 hcm_positionLampWarningRt "位置灯异常提醒";
CM_ SG_ 320 hcm_dayTimeRunningLampWarningRt "日行灯异常提醒";
CM_ SG_ 322 esc_wheelSpeedFL "Front left wheel speed.";
CM_ SG_ 322 esc_wheelSpeedFLValid "Front left wheel speed front valid signal.";
CM_ SG_ 322 esc_wheelSpeedFR "Front right wheel speed.";
CM_ SG_ 322 esc_wheelSpeedFRValid "Front right wheel speed front valid signal.";
CM_ SG_ 322 esc_142_rollingCounter "every message increments the counter.";
CM_ SG_ 322 esc_142_checksum "CRC8, checksum.";
CM_ SG_ 324 eps_sasSteeringAngle "SAS steering angle(Left positive, right negtive).";
CM_ SG_ 324 eps_sasRawSteeringAngle "The current angle of the steering wheel without offset value(Left positive, right negtive).";
CM_ SG_ 324 eps_sasSteeringAngleSpd "SAS steering angle speed.";
CM_ SG_ 324 eps_sasSteeringAngleSpdValid "SAS steering angle speed valid signal.";
CM_ SG_ 324 eps_calibratedSts "The calibration status of steering angle sensor.";
CM_ SG_ 324 eps_sasSteeringAngleValid "Valid data of signal EPS_SAS steering angle.";
CM_ SG_ 324 eps_sasRawSteeringAngleValid "Valid data of signal EPS_SAS raw steering angle.";
CM_ SG_ 324 eps_144_rollingCounter "144 Message counter for the message.";
CM_ SG_ 324 eps_144_checksum "CRC8, 144 message checksum.";
CM_ SG_ 419 APA_PDCRearMidLeftRegObjSts "Parking Assistantce Rear Middle Left Region Object Status.";
CM_ SG_ 419 APA_PDCSysSts "PAS System Status.";
CM_ SG_ 419 APA_PDCFailureWarning "PDC failure warning";
CM_ SG_ 419 APA_PDCRearLeftRegObjSts "Parking Assistantce Rear Left Region Object Status.";
CM_ SG_ 419 APA_PDCOnOffSts "indicate the PAS switch status.";
CM_ SG_ 419 APA_PDCFrontLeftRegObjSts "Parking Assistantce Front Left Region Object Status.";
CM_ SG_ 419 APA_PDCAudibleFrontBeepRate "audible Beep Rate.";
CM_ SG_ 419 APA_PDCRearRightRegObjSts "Parking Assistantce Rear Right Region Object Status.";
CM_ SG_ 419 APA_PDCAudibleRearBeepRate "audible Beep Rate.";
CM_ SG_ 419 APA_PDCFrontRightRegObjSts "Parking Assistantce Front Right Region Object Status.";
CM_ SG_ 419 APA_PDCFrontMidLeftRegObjSts "Parking Assistantce Front Middle Left Region Object Status.";
CM_ SG_ 419 APA_PDCRearMidRightRegObjSts "Parking Assistantce Rear Middle Right Region Object Status.";
CM_ SG_ 419 APA_PDCFrontMidRightRegObjSts "Parking Assistantce Front Middle Right Region Object Status.";
CM_ SG_ 515 apa_avmSts "Indicate the current work status of AVM.";
CM_ SG_ 515 apa_avmHmiIndex "Indicate the current HMI interface of AVM.";
CM_ SG_ 515 apa_avmViewMode "The view state of AVM mode.";
CM_ SG_ 515 apa_avmDisplayReq "Indicate the current display requirement of AVM.";
CM_ SG_ 515 apa_avmMODSts "Indicate the MOD running status of AVM. When the system is in initializtion, the signal is set to 0x0.";
CM_ SG_ 515 apa_avmFrontCaneraFailed "Indicate failed of front camera";
CM_ SG_ 515 apa_avmRearCaneraFailed "Indicate failed of rear camera.";
CM_ SG_ 515 apa_avmLeftCaneraFailed "Indicate failed of left camera.";
CM_ SG_ 515 apa_avmRightCaneraFailed "Indicate failed of right camera.";
CM_ SG_ 515 apa_avmVideoOutputFailed "Indicate failed of video output.";
CM_ SG_ 515 apa_avmControllerOperatingFailed "Indicate failed of controller operating.";
CM_ SG_ 515 apa_keytriggersts "Keys triggering status";
CM_ SG_ 515 apa_avmTrigByTurnningSts "The function status of AVM_TRIGGER_BY_TURNNING'.";
CM_ SG_ 515 apa_avmSingleViewSts "Indicate the status of single view .";
CM_ SG_ 515 apa_avmFrontModWarningSts "Indicate the front MOD warning status of AVM.";
CM_ SG_ 515 apa_avmRearModWarningSts "Indicate the rear MOD warning status of AVM.";
CM_ SG_ 515 apa_avmLeftModWarningSts "Indicate the left MOD warning status of AVM.";
CM_ SG_ 515 apa_avmRightModWarningSts "Indicate the right MOD warning status of AVM.";
CM_ SG_ 515 apa_avmCalibrationSts "Indicate the status of calibration.";
CM_ SG_ 515 apa_avmTrajectory_display "Indicate the status of trajectory display（轨迹线显示）";
CM_ SG_ 515 apa_avmAutoswitching_display "Indicate the status of Auto switching display(智能视角切换)";
CM_ SG_ 515 apa_avmCarBodyTransparent "Indicate the status of car body transparent(透明车辆)";
CM_ SG_ 515 apa_avmSwSts "AVM switch status. ( AVM开关状态)";
CM_ SG_ 515 apa_avmMonitVideoOutput "AVM monitor video output request.(哨兵功能AVM录制视频信号输出请求)";
CM_ SG_ 515 apa_avmPDCfailureWarn "APA/ AVM / PDC failure warning. (IVI显示的弹窗提醒信号)";
CM_ SG_ 515 apa_avm_QuitSw "AVM Quit switch status.";
CM_ SG_ 515 APA_AVM_Voicefeedback "APA语音播报反馈信号";
CM_ SG_ 515 APA_203_RollingCounter "Rolling Counter";
CM_ SG_ 515 APA_203_Checksum "CRC8 checksum.";
CM_ SG_ 520 avm_sts "Indicate the current work status of AVM.";
CM_ SG_ 520 avm_hmiIndex "Indicate the current HMI interface of AVM.";
CM_ SG_ 520 avm_viewMode "The view state of AVM mode.";
CM_ SG_ 520 avm_displayReq "Indicate the current display requirement of AVM.";
CM_ SG_ 520 avm_MODSts "Indicate the MOD running status of AVM. When the system is in initializtion, the signal is set to 0x0.";
CM_ SG_ 520 avm_frontCaneraFailed "Indicate failed of front camera";
CM_ SG_ 520 avm_rearCaneraFailed "Indicate failed of rear camera.";
CM_ SG_ 520 avm_leftCaneraFailed "Indicate failed of left camera.";
CM_ SG_ 520 avm_rightCaneraFailed "Indicate failed of right camera.";
CM_ SG_ 520 avm_videoOutputFailed "Indicate failed of video output.";
CM_ SG_ 520 avm_controllerOperatingFailed "Indicate failed of controller operating.";
CM_ SG_ 520 avm_trigByTurnningSts "The function status of AVM_TRIGGER_BY_TURNNING'.";
CM_ SG_ 520 avm_singleViewSts "Indicate the status of single view .";
CM_ SG_ 520 avm_frontModWarningSts "Indicate the front MOD warning status of AVM.";
CM_ SG_ 520 avm_rearModWarningSts "Indicate the rear MOD warning status of AVM.";
CM_ SG_ 520 avm_leftModWarningSts "Indicate the left MOD warning status of AVM.";
CM_ SG_ 520 avm_rightModWarningSts "Indicate the right MOD warning status of AVM.";
CM_ SG_ 520 avm_calibrationSts "Indicate the status of calibration.";
CM_ SG_ 520 avm_Trajectory_display "Indicate the status of trajectory display（轨迹线显示）";
CM_ SG_ 520 avm_Autoswitching_display "Indicate the status of Auto switching display(智能视角切换)";
CM_ SG_ 520 avm_CarBodyTransparent "Indicate the status of car body transparent(透明车辆)";
CM_ SG_ 520 avm_SwSts "AVM switch status. ( AVM开关状态)";
CM_ SG_ 520 avm_PDCfailureWarn "APA/ AVM / PDC failure warning. (IVI显示的弹窗提醒信号)";
CM_ SG_ 520 avm_QuitSw "AVM Quit switch status.";
CM_ SG_ 520 AVM_208_RollingCounter "Rolling Counter";
CM_ SG_ 520 AVM_208_Checksum "CRC8 checksum.";
CM_ SG_ 530 esc_vehicleSpeed "vehicle reference speed.";
CM_ SG_ 530 esc_vehicleSpeedValid "vehicle reference speed valid signal.";
CM_ SG_ 530 esc_absFault "ABS system has detected a failure which does not allow a reliable ABS regulation and is therefore switched off.";
CM_ SG_ 530 esc_absActive "indicates  ABS intervention active.";
CM_ SG_ 530 esc_vdcActive "VDC controller active: Oversteering brake intervention or Understeering brake intervention.";
CM_ SG_ 530 esc_escActive "Indication that VDC/TCS(engine torque control or brake torque control) system currently performs a brake/engine intervention.";
CM_ SG_ 530 esc_tcsActive "indicates  TCS intervention active，TCS will detect spinning wheels and request torque reduction/limitation.";
CM_ SG_ 530 esc_OBD_MILOnRq "MIL indicator light";
CM_ SG_ 530 esc_avhActive "indicates AVH in active or not .";
CM_ SG_ 530 esc_avhStandby "indicates AVH in standby mode or not.";
CM_ SG_ 530 esc_avhAvailable "HMI Responsible,CAN get degrateAVH statement from DSW and send out.";
CM_ SG_ 530 esc_cdpActive "Indicate CDP Control Active";
CM_ SG_ 530 esc_cdpAvailable "HMI Responsible,CAN get degrateCDP statement from DSW and send out.";
CM_ SG_ 530 esc_hdcSts "indicates HDC control status.";
CM_ SG_ 530 esc_hdcAvailable "HMI Responsible,CAN get degrateHDC statement from DSW and send out.";
CM_ SG_ 530 esc_hhcActive "Indicate HHC active signal";
CM_ SG_ 530 esc_hhcAvailable "HMI Responsible, CAN get degrade HHC statement from DSW and send out.";
CM_ SG_ 530 esc_masCylBrakePressure "Pressure in the master cylinder (offset included).";
CM_ SG_ 530 esc_masCylBrakePressureValid "master cylinder pressure valid.";
CM_ SG_ 530 esc_wheelCyBrakeForceExist "LDM indication brake force at wheel.";
CM_ SG_ 530 esc_ebdFault "ABS system has detected a heavy fault, which does not even allow a reliable electronic brake distribution and is therefore completely shut down.";
CM_ SG_ 530 esc_offSts "ESP OFF SW  close,ESP function passive(PATA)";
CM_ SG_ 530 esc_escFault "VDC/TCS is switched off due to detected failure.";
CM_ SG_ 530 esc_emergencyBrakeSts "Emergency brakes status signal.";
CM_ SG_ 530 esc_dtcActive "Drag torque control active.";
CM_ SG_ 530 esc_gearholdRequst "Gearhold-requst (reserved).";
CM_ SG_ 530 esc_212_rollingCounter "every message increments the counter.";
CM_ SG_ 530 esc_212_checksum "CRC8, message checksum.";
CM_ SG_ 537 mrr_accTargetAx "ACC target acceleration.";
CM_ SG_ 537 mrr_accTargetAxUpperComftBand "Upper boundary of the comfort tolerance band.";
CM_ SG_ 537 mrr_accBrakePreferred "BrakePreferred from ACC request and relevant request.";
CM_ SG_ 537 mrr_accTargetAxLowerComftBand "Lower boundary of the comfort tolerance band.";
CM_ SG_ 537 mrr_accUpperComftBandReq "From ACC side, after override, ACC should send the bit until the vehcile speed decease and reach the ACC set speed in order to have a smooth brake.";
CM_ SG_ 537 mrr_accJerkUpperLimit "Maximum allowed jerk of the target acceleration.";
CM_ SG_ 537 mrr_accDriveOff "ACC request the VLC to drive off.";
CM_ SG_ 537 mrr_accJerkLowerLimit "Minimum allowed jerk of the target acceleration.";
CM_ SG_ 537 mrr_accStandstillReq "ACC request the VLC to decelerate to stop.";
CM_ SG_ 537 mrr_accVlcShutdownReq "The shutdown mode request to ESC VLC.";
CM_ SG_ 537 mrr_accState "The status of the ACC control unit.
The ACC mode should be contained in every message sent by ACC.";
CM_ SG_ 537 mrr_accMode "ACC mode received by HMI.";
CM_ SG_ 537 mrr_frtVehStrReminderSts "前车驶离提醒功能使能状态";
CM_ SG_ 537 mrr_219_RollingCounter "every message increments the counter.";
CM_ SG_ 537 mrr_219_CheckSum "CRC8, message checksum.";
CM_ SG_ 538 mpc_leftVisualization "Left line tracking status.";
CM_ SG_ 538 mpc_rightVisualization "Right line tracking status.";
CM_ SG_ 538 mpc_laneAssitType "Operation mode of LKS.";
CM_ SG_ 538 mpc_adasTorqueReqSts "LKS torque request staus.";
CM_ SG_ 538 mpc_lasSensitivity "LAS sensitivity.";
CM_ SG_ 538 mpc_lasSts "LAS status.";
CM_ SG_ 538 mpc_adasTorqueReq "Output LKS torque request.";
CM_ SG_ 538 mpc_adasTakeoverReq "Take over request to driver.";
CM_ SG_ 538 mpc_tjaSts "TJA/ICA  status";
CM_ SG_ 538 mpc_isaOverSpdWarningSts "ISA Over speed warning status.";
CM_ SG_ 538 mpc_tjaindinfo "TJA/ICA indicator information";
CM_ SG_ 538 mpc_isaMode "ISA function Status.";
CM_ SG_ 538 mpc_adasTorqueReqValid "Output LKS torque request valid signal.";
CM_ SG_ 538 mpc_isaSpeedLimit "RSF output speed limit.";
CM_ SG_ 538 mpc_isaOnOffSts "SLA ON/OFF set.";
CM_ SG_ 538 mpc_21A_rollingCounter "every message increments the counter.";
CM_ SG_ 538 mpc_21A_checkSum "CRC8, message checksum.";
CM_ SG_ 569 mrr_aebTargetAx "target deceleration value from AEB/EBA/AEB-VRU.";
CM_ SG_ 569 mrr_aebReq "Request of the AEB deceleration control.";
CM_ SG_ 569 mrr_abaLevel "ABA level to the ESP HBA.";
CM_ SG_ 569 mrr_abaReq "Request of the ABA support from ESP.";
CM_ SG_ 569 mrr_awbReq "Request of the brake jerk warning to ESP.";
CM_ SG_ 569 mrr_awbLevel "Different level request of the brake jerk.";
CM_ SG_ 569 mrr_abpReq "Request of the Prefill to ESP.";
CM_ SG_ 569 mrr_aebOnOffSts "AEB ON OFF status for HMI.";
CM_ SG_ 569 mrr_accTakeOverReq "The limits of the ACC control reaches, driver should take over.";
CM_ SG_ 569 mrr_vSetDis "The set speed from driver, should be available as long as ACC is active.";
CM_ SG_ 569 mrr_PEBSWarning "PEBSWarning，include PreWarning and emergency Warning.";
CM_ SG_ 569 mrr_timeGapSet "The set timeGap from driver, should be displayed to driver and if the set value changes.";
CM_ SG_ 569 mrr_fcwOnOffSts "Indicating FCW function OnOff status for HMI";
CM_ SG_ 569 mrr_textInfo "Textinfo for Driver which is displayed in Dashboard.";
CM_ SG_ 569 mrr_fcwSts "FCW status.";
CM_ SG_ 569 mrr_aebSts "AEB status.";
CM_ SG_ 569 mrr_239_RollingCounter "every message increments the counter.";
CM_ SG_ 569 mrr_239_CheckSum "CRC8, message checksum.";
CM_ SG_ 571 mrr_r1_systemErrorSts "system Error Status.";
CM_ SG_ 571 mrr_r1_BSDLCAWorkingSts "BSD/LCA Working Status.";
CM_ SG_ 571 mrr_r1_RCTAWorkingSts "RCTA Working Status.";
CM_ SG_ 571 mrr_r1_DOWWorkingSts "DOW Working Status.";
CM_ SG_ 571 mrr_r1_RCWWorkingSts "RCW Working Status.";
CM_ SG_ 571 mrr_r1_leftBSDLCAWarning "left BSD/LCA Warning.";
CM_ SG_ 571 mrr_r1_leftRCTAWarnning "left RCTA Warning.";
CM_ SG_ 571 mrr_r1_leftDOWWarnning "left DOW Warning.";
CM_ SG_ 571 mrr_r1_rearCollisionWarning "rear Collision Warning.";
CM_ SG_ 571 mrr_r1_rightBSDLCAWarning "right BSD/LCA Warning.";
CM_ SG_ 571 mrr_r1_rightRCTAWarnning "right RCTA Warnning.";
CM_ SG_ 571 mrr_r1_rightDOWWarnning "right DOW Warnning.";
CM_ SG_ 571 mrr_r1_targetStsLR "Left rear target status.";
CM_ SG_ 571 mrr_r1_targetLongDisLR "Left rear target longitudinal distance.";
CM_ SG_ 571 mrr_r1_targetLateralDistanceLR "Left rear target lateral distance.";
CM_ SG_ 571 mrr_r1_targetDangerLevelLR "Left rear target danger level.";
CM_ SG_ 571 mrr_r1_targetStsRR "Right rear target status.";
CM_ SG_ 571 mrr_r1_targetLongDisRR "Right  rear target longitudinal distance.";
CM_ SG_ 571 mrr_r1_targetLateralDistanceRR "Right  rear target lateral distance.";
CM_ SG_ 571 mrr_r1_targetDangerLevelRR "Right  rear target danger level.";
CM_ SG_ 571 mrr_r1_targetTypeLR "Left rear target type.";
CM_ SG_ 571 mrr_r1_targetTypeRR "Right rear target type.";
CM_ SG_ 577 vcu_accPedalPos "Actual acceleration pedal position.";
CM_ SG_ 577 vcu_accPedalPosValid "Acceleration pedal position valid .";
CM_ SG_ 577 vcu_tcmFail "Indicating VCU in limp-home (error) mode.";
CM_ SG_ 577 vcu_motorRunning "Indicator of electronic engine running or not.";
CM_ SG_ 577 vcu_overrideSts "Indicating the torque demanded by the driver is higher than the torque demanded by ACC.";
CM_ SG_ 577 vcu_brakePedalSts "Indicating brake pedal activated by driver or not.";
CM_ SG_ 577 vcu_brakePedalStsValid "Indicating the valid bit for brake pedal status.";
CM_ SG_ 577 vcu_actualGearValid "Actual gear valid signal.";
CM_ SG_ 577 vcu_targetGearValid "Target gear valid .";
CM_ SG_ 577 vcu_actualGear "Actual gear engaged.";
CM_ SG_ 577 vcu_targetGear "Target gear.";
CM_ SG_ 577 vcu_totalPowerConsumThisTrip "total power consum this trip";
CM_ SG_ 577 vcu_ccState "定速巡航状态";
CM_ SG_ 577 vcu_vDisSet "定速巡航设置速度";
CM_ SG_ 577 vcu_241_rollingCounter "Message counter for the message";
CM_ SG_ 577 vcu_241_checksum "CRC8, message checksum.";
CM_ SG_ 626 esc_sumOfEdgeFLWSS "Sum of the front left edges wheel speed status.";
CM_ SG_ 626 esc_sumOfEdgeFRWSS "Sum of the front righ edges wheel speed status.";
CM_ SG_ 626 esc_sumOfEdgeFLWSSValid "Sum of the front left edges wheel speed status Valid.";
CM_ SG_ 626 esc_sumOfEdgeFRWSSValid "Sum of the front righ edges wheel speed status Valid.";
CM_ SG_ 626 esc_wheelDirectionFLValid "Front left wheel moving direction.";
CM_ SG_ 626 esc_wheelDirectionFRValid "Front right wheel moving direction.";
CM_ SG_ 626 esc_wheelDirectionFL "Front left wheel moving direction.";
CM_ SG_ 626 esc_wheelDirectionFR "Front right wheel moving direction.";
CM_ SG_ 626 esc_272_rollingCounter "every message increments the counter.";
CM_ SG_ 626 esc_272_checksum "CRC8, message checksum.";
CM_ SG_ 642 esc_sumOfEdgeRLWSS "Sum of the rear left edges wheel speed status.";
CM_ SG_ 642 esc_sumOfEdgeRRWSS "Sum of the rear righ edges wheel speed status.";
CM_ SG_ 642 esc_sumOfEdgeRLWSSValid "Sum of the rear left edges wheel speed status Valid.";
CM_ SG_ 642 esc_sumOfEdgeRRWSSValid "Sum of the rear righ edges wheel speed status Valid.";
CM_ SG_ 642 esc_wheelDirectionRLValid "Rear left wheel moving direction.";
CM_ SG_ 642 esc_wheelDirectionRRValid "Rear right wheel moving direction.";
CM_ SG_ 642 esc_wheelDirectionRL "Rear left wheel moving direction.";
CM_ SG_ 642 esc_wheelDirectionRR "Rear right wheel moving direction.";
CM_ SG_ 642 esc_282_rollingCounter "every message increments the counter.";
CM_ SG_ 642 esc_282_checksum "CRC8, message checksum.";
CM_ SG_ 673 bcm_turnLampSerialReq "turn Lamp Serial  Request";
CM_ SG_ 673 bcm_turnLampFlickerReq "turn Lamp Flicker Request";
CM_ SG_ 673 bcm_drlReq "DRL  Request.";
CM_ SG_ 673 bcm_posLampReq "Position lamp Request.";
CM_ SG_ 673 bcm_lowBeamReq "Low beam Request.";
CM_ SG_ 673 bcm_highBeamReq "high beam Request.";
CM_ SG_ 673 bcm_leftTurnLampReq "left turn lamp request";
CM_ SG_ 673 bcm_rightTurnLampReq "right turn lamp request";
CM_ SG_ 673 bcm_hoodSts "Hood status.";
CM_ SG_ 673 bcm_hazardLightSts "Hazard light status.
bcm_hazardLightSts触发的功能只包括危险报警灯、远程危险报警灯。当功能激活时bcm_hazardLightSts=0x1:on，当功能退出时，bcm_hazardLightSts=0x0:off";
CM_ SG_ 673 bcm_leftTurnLampSwSts "left turn lamp switch status.";
CM_ SG_ 673 bcm_leftTurnLampSts "left turn lamp status.";
CM_ SG_ 673 bcm_WipperMaintenanceSts "Wipper Maintenance State";
CM_ SG_ 673 bcm_pdcSwitchSet "PDC Switch set";
CM_ SG_ 673 bcm_rightTurnLampSts "right turn lamp status.";
CM_ SG_ 673 bcm_HornSts "喇叭状态";
CM_ SG_ 673 bcm_brakeLightReq "brake light request";
CM_ SG_ 673 bcm_rightTurnLampSwSts "right turn lamp switch status.";
CM_ SG_ 673 bcm_doorFLSts "Front left door status.";
CM_ SG_ 673 bcm_doorFRSts "Front right door status.";
CM_ SG_ 673 bcm_doorRLSts "Rear left door status.";
CM_ SG_ 673 bcm_doorRRSts "Rear right door status.";
CM_ SG_ 673 bcm_doorFLLockSts "Front left door lock status.";
CM_ SG_ 673 bcm_LeftMirrorSw "left mirror switch.";
CM_ SG_ 673 bcm_rightMirrorSw "right mirror switch.";
CM_ SG_ 673 bcm_frontWiperParkingSts "Front wiper park status.";
CM_ SG_ 673 bcm_rearWiperParkingSts "rear wiper park status.";
CM_ SG_ 673 bcm_antiTheftSts "Anti-theft status.";
CM_ SG_ 673 bcm_fuelCapSts "Fuel cap status.";
CM_ SG_ 673 bcm_frontWiperSts "Front wiper status.";
CM_ SG_ 673 bcm_chrgCapSts "Charging cap status.";
CM_ SG_ 673 bcm_gunUnlockCtrlReq "遥控钥匙触发的枪解锁";
CM_ SG_ 673 bcm_readyReq "BCM ready request";
CM_ SG_ 673 bcm_mirrorAdjust "Rearview mirror adjust.";
CM_ SG_ 673 bcm_tailgateOpenSW "Tailgate open switch.";
CM_ SG_ 673 bcm_apaOnOffSet "APA开关信号";
CM_ SG_ 673 bcm_avmOnOffSet "AVM开关信号";
CM_ SG_ 673 bcm_driveMode "驾驶模式切换";
CM_ SG_ 673 bcm_parkAutoCloseDRLSts "驻车自动关闭日行灯状态信号";
CM_ SG_ 673 bcm_HvReq "High voltage on request.";
CM_ SG_ 673 BCM_CloselightReq "接近照明请求";
CM_ SG_ 673 bcm_2A1_rollingCounter "every message increments the counter.";
CM_ SG_ 673 bcm_2A1_checksum "CRC8, checksum.";
CM_ SG_ 674 esc_cddActive "Indicate CDD is active or not.";
CM_ SG_ 674 esc_cddAvailable "Indicate CDD is available or not.";
CM_ SG_ 674 esc_cddError "Means not able to execute ACC commands.";
CM_ SG_ 674 esc_cddTempOff "Indicating brake temperature too high or not.";
CM_ SG_ 674 esc_abaActive "Indicate HBA(ABA) is active or not.";
CM_ SG_ 674 esc_abaAvailable "Indicate HBA(ABA) is available or not.";
CM_ SG_ 674 esc_abpActive "Prefill(ABP) is active or not.";
CM_ SG_ 674 esc_abpAvailable "Prefill(ABP) is available or not.";
CM_ SG_ 674 esc_aebActive "ESP is excuting AEB/EBA/AEB-VRU  braking function.";
CM_ SG_ 674 esc_aebAvailable "AEB/EBA/AEB-VRU is available.";
CM_ SG_ 674 esc_awbActive "Indicate AWB is active or not.";
CM_ SG_ 674 esc_awbAvailable "Indicate AWB is available or not.";
CM_ SG_ 674 esc_vehicleStandstill "Indicating whether the vehicle is standstill or not; Cannot be set until standstill is surely reached.";
CM_ SG_ 674 esc_vehicleStandstillValid "Vehicle Standstill state valid signal.";
CM_ SG_ 674 esc_brakelightIlluminate "LDM requires to illuminate brake light.";
CM_ SG_ 674 esc_vlcTorqReq "VLC engine Torque Request.";
CM_ SG_ 674 esc_vlcTorqReqActive "VLC engine Torque Request Active.";
CM_ SG_ 674 esc_vlcError "Indicate the failure status of VLC.";
CM_ SG_ 674 esc_vlcAvalible "Indicating whether VLC is basically ready for activation or not. It could be combined with VLCFail.";
CM_ SG_ 674 esc_vlcInterTargetAx "Internal VLC target acceleration.";
CM_ SG_ 674 esc_hmiWarningOn "With this signal ESC requests the warning lamp  in the dashboard.";
CM_ SG_ 674 esc_hmiWarningOn_Q "Qualifier of esc_hmiWarningOn.";
CM_ SG_ 674 esc_vlcActive "Indicates VLC is active or not.";
CM_ SG_ 674 esc_hbbSts "This signal indicates the status of HBB.";
CM_ SG_ 674 esc_hbbActive "This signal indicates if HBB is active or not.";
CM_ SG_ 674 esc_2A2_rollingCounter "every message increments the counter";
CM_ SG_ 674 esc_2A2_checksum "CRC8, message checksum.";
CM_ SG_ 684 bcm_sl_currentPos "Current Position";
CM_ SG_ 684 bcm_sl_roatingSts "Roating Status";
CM_ SG_ 684 bcm_sl_isRoatingEn "Whether or not Roating";
CM_ SG_ 684 bcm_sl_Valid "Valid signal";
CM_ SG_ 684 bcm_sl_roatingTimes "Roating time";
CM_ SG_ 684 bcm_apm_flVentilationFb "左前车窗通风降窗反馈";
CM_ SG_ 684 bcm_apm_frVentilationFb "右前车窗通风降窗反馈";
CM_ SG_ 684 bcm_apm_rlVentilationFb "左后车窗通风降窗反馈";
CM_ SG_ 684 bcm_apm_rrVentilationFb "右后车窗通风降窗反馈";
CM_ SG_ 684 bcm_srm_srOpenPosition "valid value from 0 to 100,which means 0~100%";
CM_ SG_ 684 bcm_ssm_ssOpenPosition "valid value from 0 to 100,which means 0~100%";
CM_ SG_ 684 bcm_ebs_U_BATT "Battery voltage";
CM_ SG_ 684 bcm_sl_errSts "Error Status";
CM_ SG_ 684 bcm_rsm_lightSWReason "Light_Switch_Reason
光线传感器亮度级别";
CM_ SG_ 705 bcm_pepsPowerMode "peps Power Mode.";
CM_ SG_ 705 bcm_IMMOReleaseIndication "IMMO Release Indication.";
CM_ SG_ 705 bcm_pepsKeyNotInCarInd "peps Key is not in car indication.";
CM_ SG_ 705 bcm_keyValid "key Valid.";
CM_ SG_ 705 bcm_pepsKeySerchFailInd "Search key failed warning.";
CM_ SG_ 705 bcm_pepsKeyCloserInd "peps Key Closer indication.";
CM_ SG_ 705 bcm_pepsFobLowBatWarning "peps Fob battery low warning.";
CM_ SG_ 705 bcm_pepsPowerRelayErrWarning "peps Power relay error warning.";
CM_ SG_ 705 bcm_RearWindowLockSts "后窗和儿童锁状态";
CM_ SG_ 705 bcm_IndicationPressBrake "提示请踩刹车启动";
CM_ SG_ 705 bcm_LowFrequencyAntennaFault "提示低频天线故障";
CM_ SG_ 705 bcm_remoteMode "Remote mode.";
CM_ SG_ 705 bcm_ble_response "ble_response.";
CM_ SG_ 705 bcm_autoGlassCloseWarning "下雨自动关窗失败报警";
CM_ SG_ 705 bcm_rke_fuelPortCapOpenCtrl "加油口盖RKE控制";
CM_ SG_ 705 bcm_fhcActionLeftFront "Left Front Handle Action to Perform.
如果事件触发，相应的信号值连发3~5帧，然后跳变到信号值0x0；";
CM_ SG_ 705 bcm_fhcActionRightFront "Right Front Handle Action to Perform.
如果事件触发，相应的信号值连发3~5帧，然后跳变到信号值0x0；";
CM_ SG_ 705 bcm_fhcActionLeftRear "Left Rear Handle Action to Perform.
如果事件触发，相应的信号值连发3~5帧，然后跳变到信号值0x0；";
CM_ SG_ 705 bcm_fhcActionRightRear "Right Rear Handle Action to Perform.
如果事件触发，相应的信号值连发3~5帧，然后跳变到信号值0x0；";
CM_ SG_ 705 bcm_12VBatterySOC "12V Battery SOC.";
CM_ SG_ 705 bcm_pepsKeyInCarInd "peps Key in car indication.";
CM_ SG_ 705 bcm_tbox_response "tbox_response.";
CM_ SG_ 705 bcm_approachingUnlockFedb "approaching unlock set feedback.";
CM_ SG_ 705 bcm_followMeHomeFedb "Follow me home function set feedback .";
CM_ SG_ 705 bcm_awayLockFeedback "away lock control status.";
CM_ SG_ 705 bcm_MirrorAutoFoldUnfoldSts "Mirror auto fold/unfold function set status.";
CM_ SG_ 706 esc_epbFaultLamp "EPB fault lamp.";
CM_ SG_ 706 esc_epbParkingLamp "EPB parking lamp.";
CM_ SG_ 706 esc_epbTextDisplay "EPB text information for display.";
CM_ SG_ 706 esc_epbSts "EPB system status.";
CM_ SG_ 706 esc_epbTextDisplayOnIVI "epb text display on IVI.";
CM_ SG_ 706 esc_epbAutoApplyInAction "epb Auto ApplyIn Action.";
CM_ SG_ 706 esc_epbTowModeInAction "epb Tow Mode In Action.";
CM_ SG_ 706 esc_2C2_rollingCounter "every message increments the counter.";
CM_ SG_ 706 esc_2C2_checkSum "CRC8, message checksum.";
CM_ SG_ 720 ble_phoneLocation "蓝牙钥匙位置信息";
CM_ SG_ 720 ble_keyIndex "蓝牙钥匙索引号";
CM_ SG_ 720 ble_KeyIdentify "钥匙身份信号";
CM_ SG_ 720 ble_VelPermissionSet "分享钥匙权限设置";
CM_ SG_ 720 ble_2D0_RollingCounter "Message counter for the message.";
CM_ SG_ 720 ble_2D0_Checksum "CRC8, checksum.";
CM_ SG_ 753 AC_PoorInAirQuality "Poor Air Quality Indoor
车内空气质量差";
CM_ SG_ 753 AC_PM25Sts "PM2.5的运行状态";
CM_ SG_ 753 AC_PM25ValueIn "车内PM2.5数值";
CM_ SG_ 753 AC_PM25ValueOut "车外PM2.5数值";
CM_ SG_ 753 AC_AutoModeSt "AUTO MODE Status";
CM_ SG_ 753 AC_OneTouchCoolSts "AC one touch cool status（一键清凉）";
CM_ SG_ 753 AC_OneTouchHeatSts "AC one touch heat status（一键加热）";
CM_ SG_ 762 vcu_RecoveryPowerAllowed "allowed driving power, for IC INDICATION";
CM_ SG_ 762 vcu_GearPosNotEqual "vcu_gear is not equal to gsm_gearSelectorPos, for IC INDICATION";
CM_ SG_ 762 vcu_RecoveryPowerAcutal "actual driving power, for IC INDICATION";
CM_ SG_ 762 VCU_StandStillPreheatBattWarn "Battery warm warning when battery temperature is low.";
CM_ SG_ 762 VCU_LowTempInhibitPowerUpWarn "Inhibit HV power up when battery temperature is lower than -30℃.";
CM_ SG_ 762 VCU_SOCmodeSet "Feedback SOC set mode to IVI.";
CM_ SG_ 769 vcu_avgPwrCurrentTrip "Average Power of Current Trip.";
CM_ SG_ 769 vcu_avgPwrSincelastcharge "Average Power Since the last charge.";
CM_ SG_ 769 vcu_avgPwroftripA "Average Power of tripA.";
CM_ SG_ 769 vcu_PwroftripB "Power of tripB.";
CM_ SG_ 769 vcu_avgPwroftripB "Average Power of tripB.";
CM_ SG_ 770 mcur0_tempHeatSinkPhA "Temperature heat sink PhA.";
CM_ SG_ 770 mcur0_tempHeatSinkPhB "Temperature heat sink PhB.";
CM_ SG_ 770 mcur0_tempHeatSinkPhC "Temperature heat sink PhC.";
CM_ SG_ 770 mcur0_tempEndWinding1 "Temperature end winding1.";
CM_ SG_ 770 mcur0_tempEndWinding2 "Temperature end winding2.";
CM_ SG_ 770 mcur0_tempCltOutlet "Temperature  coolant outlet.";
CM_ SG_ 770 mcur0_tempStator "Temperature stator.";
CM_ SG_ 771 mcuf0_tempHeatSinkPhA "Temperature heat sink PhA.";
CM_ SG_ 771 mcuf0_tempHeatSinkPhB "Temperature heat sink PhB.";
CM_ SG_ 771 mcuf0_tempHeatSinkPhC "Temperature heat sink PhC.";
CM_ SG_ 771 mcuf0_tempEndWinding1 "Temperature end winding1.";
CM_ SG_ 771 mcuf0_tempEndWinding2 "Temperature end winding2.";
CM_ SG_ 771 mcuf0_tempCltOutlet "Temperature coolant Outlet.";
CM_ SG_ 771 mcuf0_tempStator "Temperature stator.";
CM_ SG_ 772 bms_packTempMax "Maximum pack temperature.";
CM_ SG_ 772 bms_packTempMin "Minimum pack temperature.";
CM_ SG_ 772 bms_packTempAvg "Pack temperature average.";
CM_ SG_ 772 bms_tempInletCoolant "Temperature  inlet coolant.";
CM_ SG_ 772 bms_tempOutletCoolant "Temperature outlet coolant.";
CM_ SG_ 772 bms_targetInletTemp "Target inlet temperature.";
CM_ SG_ 772 bms_targetFlowRate "Target flow rate.";
CM_ SG_ 772 bms_thermalReqState "Battery pack thermal state request.";
CM_ SG_ 777 gsm_faultSts "GSM fault status.";
CM_ SG_ 777 gsm_gearSelectorPos "Gear selector position.";
CM_ SG_ 777 gsm_faultLevel "GSM fault level.";
CM_ SG_ 777 gsm_intervention "Driver intervention";
CM_ SG_ 777 gsm_apa_gearReqfdbk "Gear request feedback";
CM_ SG_ 777 gsm_warnInformation "warn informations";
CM_ SG_ 777 gsm_309_RollingCounter "Message counter for the message.";
CM_ SG_ 777 gsm_309_checksum "CRC8, message checksum.";
CM_ SG_ 782 bms_vPackBmu "Current battery pack voltage.";
CM_ SG_ 782 bms_vPackBms "Current battery pack voltage.";
CM_ SG_ 782 bms_iPack "Current battery pack current.";
CM_ SG_ 782 bms_pPack "Current battery pack power.";
CM_ SG_ 782 bms_packEnergy "battery pack  Energy";
CM_ SG_ 793 swm_Photo "Photo.";
CM_ SG_ 793 swm_ACCSW "ACC Swich.";
CM_ SG_ 793 swm_ACCSWValid "ACC Swich Valid.";
CM_ SG_ 793 swm_ACCRESorAdd "ACC RES/+.";
CM_ SG_ 793 swm_ACCRESorAddValid "ACC RES/+ Valid.";
CM_ SG_ 793 swm_ACCSETorSub "ACC SET/-.";
CM_ SG_ 793 swm_ACCSETorSubValid "ACC SET/-Valid.";
CM_ SG_ 793 swm_ACCInterval "ACC Interval Swich.";
CM_ SG_ 793 swm_ACCIntervalValid "ACC Interval Swich Valid.";
CM_ SG_ 793 swm_CNCL "CNCL.";
CM_ SG_ 793 swm_CNCLValid "CNCL Valid.";
CM_ SG_ 793 swm_TJAHWASwtich "TJA/HWA Swtich.";
CM_ SG_ 793 swm_TJAHWASwtichValid "TJA/HWA Swtich Valid.";
CM_ SG_ 793 swm_menu "menu.";
CM_ SG_ 793 swm_OK "OK.";
CM_ SG_ 793 swm_upAdd "up/ volume Add.";
CM_ SG_ 793 swm_downMinus "down / volume minus";
CM_ SG_ 793 swm_leftLast "left/Last.";
CM_ SG_ 793 swm_rightNext "right/Next.";
CM_ SG_ 793 swm_nvsSwitch "Night vision switch.";
CM_ SG_ 793 swm_phone "Phone answer/end.";
CM_ SG_ 793 swm_voice "voice recognition.";
CM_ SG_ 793 swm_highbeam "High beam switch.";
CM_ SG_ 793 swm_overtakingLight "Overtaking light switch.";
CM_ SG_ 793 swm_turnSW "Left and right turn light switch.";
CM_ SG_ 793 swm_changeLaneSW "Left and right lane change light switch.";
CM_ SG_ 793 swm_frontWashing "Front washing switch.";
CM_ SG_ 793 swm_frontWiper "Working status of front wiper.";
CM_ SG_ 793 swm_backWiper "Working status of rear wiper.";
CM_ SG_ 793 swm_backWashing "Rear washing switch.";
CM_ SG_ 793 swm_autoWiper "Working state of the wiper when the front wiper is auto.";
CM_ SG_ 793 swm_trumpet "trumpet switch.";
CM_ SG_ 793 swm_userdefined "user defined switch.";
CM_ SG_ 793 swm_CCSwitch "CC Swich.";
CM_ SG_ 793 swm_CCSwitchInvalid "CC Swich Valid.";
CM_ SG_ 793 swm_319_Rollingcounter "Message counter for the message.";
CM_ SG_ 793 swm_319_Checksum "CRC8, message checksum.";
BA_DEF_ BO_  "NmMessage" ENUM  "No","Yes";
BA_DEF_ BO_  "DiagState" ENUM  "No","Yes";
BA_DEF_ BO_  "GenMsgSendType" ENUM  "Cyclic","Event","IfActive","CE","CA","NoMsgSendType";
BA_DEF_ BO_  "GenMsgCycleTime" INT 0 0;
BA_DEF_ SG_  "GenSigSendType" ENUM  "Cyclic","OnChange","OnWrite","IfActive","OnChangeWithRepetition","OnWriteWithRepetition","IfActiveWithRepetition","NoSigSendType","OnChangeAndIfActive","OnChangeAndIfActiveWithRepetition","CA","CE","Event";
BA_DEF_ SG_  "GenSigStartValue" INT 0 0;
BA_DEF_ SG_  "GenSigInactiveValue" INT 0 0;
BA_DEF_ BO_  "GenMsgCycleTimeFast" INT 0 0;
BA_DEF_ BO_  "GenMsgNrOfRepetition" INT 0 0;
BA_DEF_  "DBName" STRING ;
BA_DEF_ BU_  "NodeLayerModules" STRING ;
BA_DEF_ BU_  "NmNode" ENUM  "Not","Yes";
BA_DEF_  "NmBaseAddress" HEX 0 2047;
BA_DEF_  "NmMessageCount" INT 0 255;
BA_DEF_  "BusType" STRING ;
BA_DEF_DEF_  "NmMessage" "No";
BA_DEF_DEF_  "DiagState" "No";
BA_DEF_DEF_  "GenMsgSendType" "Cyclic";
BA_DEF_DEF_  "GenMsgCycleTime" 0;
BA_DEF_DEF_  "GenSigSendType" "Cyclic";
BA_DEF_DEF_  "GenSigStartValue" 0;
BA_DEF_DEF_  "GenSigInactiveValue" 0;
BA_DEF_DEF_  "GenMsgCycleTimeFast" 0;
BA_DEF_DEF_  "GenMsgNrOfRepetition" 0;
BA_DEF_DEF_  "DBName" "";
BA_DEF_DEF_  "NodeLayerModules" "CANoeILNLVector.dll";
BA_DEF_DEF_  "NmNode" "Not";
BA_DEF_DEF_  "NmBaseAddress" 1024;
BA_DEF_DEF_  "NmMessageCount" 128;
BA_DEF_DEF_  "BusType" "CAN";
BA_ "DBName" "HiFire_H97_INFOCAN_Matrix_CAN_V2";
BA_ "GenMsgSendType" BO_ 1801 1;
BA_ "GenMsgSendType" BO_ 1805 1;
BA_ "GenMsgSendType" BO_ 1808 1;
BA_ "GenMsgSendType" BO_ 1815 1;
BA_ "GenMsgSendType" BO_ 1829 1;
BA_ "GenMsgSendType" BO_ 1850 1;
BA_ "GenMsgSendType" BO_ 1857 1;
BA_ "GenMsgSendType" BO_ 1865 1;
BA_ "GenMsgCycleTime" BO_ 1029 200;
BA_ "GenMsgCycleTime" BO_ 1030 200;
BA_ "GenMsgSendType" BO_ 1609 1;
BA_ "NmMessage" BO_ 1609 1;
BA_ "GenMsgSendType" BO_ 1993 1;
BA_ "GenMsgCycleTime" BO_ 1014 1000;
BA_ "GenMsgSendType" BO_ 1026 1;
BA_ "GenMsgSendType" BO_ 1027 1;
BA_ "GenMsgSendType" BO_ 1553 1;
BA_ "NmMessage" BO_ 1553 1;
BA_ "GenMsgSendType" BO_ 1985 1;
BA_ "GenMsgSendType" BO_ 16 1;
BA_ "GenMsgCycleTime" BO_ 20 1000;
BA_ "GenMsgSendType" BO_ 65 1;
BA_ "GenMsgSendType" BO_ 81 1;
BA_ "GenMsgCycleTime" BO_ 273 10;
BA_ "GenMsgCycleTime" BO_ 276 100;
BA_ "GenMsgCycleTime" BO_ 288 10;
BA_ "GenMsgCycleTime" BO_ 290 20;
BA_ "GenMsgCycleTime" BO_ 294 100;
BA_ "GenMsgCycleTime" BO_ 304 20;
BA_ "GenMsgCycleTime" BO_ 320 40;
BA_ "GenMsgCycleTime" BO_ 322 20;
BA_ "GenMsgCycleTime" BO_ 324 10;
BA_ "GenMsgCycleTime" BO_ 419 50;
BA_ "GenMsgCycleTime" BO_ 515 100;
BA_ "GenMsgCycleTime" BO_ 520 100;
BA_ "GenMsgCycleTime" BO_ 530 20;
BA_ "GenMsgCycleTime" BO_ 537 20;
BA_ "GenMsgCycleTime" BO_ 538 20;
BA_ "GenMsgCycleTime" BO_ 569 20;
BA_ "GenMsgNrOfRepetition" BO_ 571 3;
BA_ "GenMsgCycleTimeFast" BO_ 571 20;
BA_ "GenMsgCycleTime" BO_ 571 100;
BA_ "GenMsgSendType" BO_ 571 3;
BA_ "GenMsgCycleTime" BO_ 577 20;
BA_ "GenMsgCycleTime" BO_ 626 20;
BA_ "GenMsgCycleTime" BO_ 642 20;
BA_ "GenMsgCycleTime" BO_ 673 20;
BA_ "GenMsgCycleTime" BO_ 674 20;
BA_ "GenMsgCycleTime" BO_ 684 100;
BA_ "GenMsgCycleTime" BO_ 705 20;
BA_ "GenMsgCycleTime" BO_ 706 20;
BA_ "GenMsgCycleTime" BO_ 720 100;
BA_ "GenMsgCycleTime" BO_ 753 100;
BA_ "GenMsgCycleTime" BO_ 762 100;
BA_ "GenMsgCycleTime" BO_ 769 100;
BA_ "GenMsgCycleTime" BO_ 770 100;
BA_ "GenMsgCycleTime" BO_ 771 100;
BA_ "GenMsgCycleTime" BO_ 772 100;
BA_ "GenMsgCycleTime" BO_ 777 20;
BA_ "GenMsgCycleTime" BO_ 782 50;
BA_ "GenMsgCycleTime" BO_ 793 100;
BA_ "GenSigSendType" SG_ 1801 Diag_PhyReq_ICM_Data 2;
BA_ "GenSigSendType" SG_ 1805 Diag_PhyReq_WCM_Data 2;
BA_ "GenSigSendType" SG_ 1808 Diag_PhyReq_VSP_Data 2;
BA_ "GenSigSendType" SG_ 1815 Diag_PhyReq_PDC_Data 2;
BA_ "GenSigSendType" SG_ 1829 Diag_PhyReq_IVI_Data 2;
BA_ "GenSigSendType" SG_ 1850 Diag_PhyReq_NVS_Data 2;
BA_ "GenSigSendType" SG_ 1857 Diag_PhyReq_ETC_Data 2;
BA_ "GenSigSendType" SG_ 1865 Diag_PhyReq_AMP_Data 2;
BA_ "GenSigStartValue" SG_ 1029 amp_weightlowFrqSetSts 31;
BA_ "GenSigStartValue" SG_ 1030 amp_highFrqSetSts 31;
BA_ "GenSigStartValue" SG_ 1030 amp_mediaVolSts 63;
BA_ "GenSigStartValue" SG_ 1030 amp_globalMuteSts 3;
BA_ "GenSigStartValue" SG_ 1030 amp_midFrqSetSts 31;
BA_ "GenSigStartValue" SG_ 1030 amp_lowFrqSetSts 31;
BA_ "GenSigStartValue" SG_ 1030 amp_audioBlcSts 31;
BA_ "GenSigStartValue" SG_ 1030 amp_audioFaderSts 31;
BA_ "GenSigSendType" SG_ 1609 AMP_RMR 2;
BA_ "GenSigSendType" SG_ 1609 AMP_AWB 2;
BA_ "GenSigSendType" SG_ 1993 Diag_Resp_AMP_Data 2;
BA_ "GenSigSendType" SG_ 1026 etc_amountDataNumFdb 1;
BA_ "GenSigSendType" SG_ 1026 etc_tranAmount1 1;
BA_ "GenSigSendType" SG_ 1026 etc_tranAmount2 1;
BA_ "GenSigSendType" SG_ 1026 etc_tranAmount3 1;
BA_ "GenSigSendType" SG_ 1026 etc_tranAmount4 1;
BA_ "GenSigSendType" SG_ 1026 etc_roadNetN1 1;
BA_ "GenSigSendType" SG_ 1026 etc_roadNetN2 1;
BA_ "GenSigSendType" SG_ 1026 etc_tranStauts 1;
BA_ "GenSigSendType" SG_ 1027 etc_timeDataNumFdb 1;
BA_ "GenSigSendType" SG_ 1027 etc_unixTime1 1;
BA_ "GenSigSendType" SG_ 1027 etc_unixTime2 1;
BA_ "GenSigSendType" SG_ 1027 etc_unixTime3 1;
BA_ "GenSigSendType" SG_ 1027 etc_unixTime4 1;
BA_ "GenSigSendType" SG_ 1027 etc_stationN1 1;
BA_ "GenSigSendType" SG_ 1027 etc_stationN2 1;
BA_ "GenSigSendType" SG_ 1027 etc_dataSts 1;
BA_ "GenSigSendType" SG_ 1553 ETC_RMR 2;
BA_ "GenSigSendType" SG_ 1553 ETC_AWB 2;
BA_ "GenSigSendType" SG_ 1985 Diag_Resp_ETC_Data 2;
BA_ "GenSigSendType" SG_ 16 ble_rke_lockCtrlReq 1;
BA_ "GenSigSendType" SG_ 16 ble_rke_tailgateCtrlReq 1;
BA_ "GenSigSendType" SG_ 16 ble_rke_carSearchReq 1;
BA_ "GenSigSendType" SG_ 16 ble_rke_sunRoofGlassCmd 1;
BA_ "GenSigSendType" SG_ 16 ble_rke_winCtrlReq 1;
BA_ "GenSigSendType" SG_ 16 ble_rke_chrgCapCtrlReq 1;
BA_ "GenSigSendType" SG_ 16 ble_dvrTakePicCtrl 1;
BA_ "GenSigSendType" SG_ 16 ble_welcomeCmd 1;
BA_ "GenSigSendType" SG_ 16 ble_easyEntryManualSw 1;
BA_ "GenSigSendType" SG_ 16 ble_rke_chrgGunUnlockCtrlReq 1;
BA_ "GenSigSendType" SG_ 16 ble_rke_fuelPortCapOpenCtrl 1;
BA_ "GenSigStartValue" SG_ 65 bcm_challengeFrame1 65535;
BA_ "GenSigSendType" SG_ 65 bcm_challengeFrame1 2;
BA_ "GenSigSendType" SG_ 81 bcm_failCode 1;
BA_ "GenSigStartValue" SG_ 290 esc_wheelSpeedRL 8190;
BA_ "GenSigStartValue" SG_ 290 esc_wheelSpeedRR 8190;
BA_ "GenSigStartValue" SG_ 294 bms_fastChargeTap1 80;
BA_ "GenSigStartValue" SG_ 294 bms_fastChargeTap2 80;
BA_ "GenSigStartValue" SG_ 322 esc_wheelSpeedFL 8190;
BA_ "GenSigStartValue" SG_ 322 esc_wheelSpeedFR 8190;
BA_ "GenSigStartValue" SG_ 530 esc_vehicleSpeed 8190;
BA_ "GenSigStartValue" SG_ 530 esc_avhAvailable 1;
BA_ "GenSigStartValue" SG_ 530 esc_offSts 1;
BA_ "GenSigStartValue" SG_ 530 esc_escFault 1;
BA_ "GenSigStartValue" SG_ 537 mrr_accJerkLowerLimit 127;
BA_ "GenSigStartValue" SG_ 537 mrr_accVlcShutdownReq 3;
BA_ "GenSigStartValue" SG_ 538 mpc_adasTorqueReq 1024;
BA_ "GenSigStartValue" SG_ 538 mpc_adasTorqueReqValid 1;
BA_ "GenSigStartValue" SG_ 569 mrr_aebOnOffSts 1;
BA_ "GenSigStartValue" SG_ 569 mrr_fcwOnOffSts 1;
BA_ "GenSigStartValue" SG_ 569 mrr_fcwSts 1;
BA_ "GenSigStartValue" SG_ 569 mrr_aebSts 1;
BA_ "GenSigSendType" SG_ 571 mrr_r1_leftBSDLCAWarning 4;
BA_ "GenSigSendType" SG_ 571 mrr_r1_leftRCTAWarnning 4;
BA_ "GenSigSendType" SG_ 571 mrr_r1_leftDOWWarnning 4;
BA_ "GenSigSendType" SG_ 571 mrr_r1_rearCollisionWarning 4;
BA_ "GenSigSendType" SG_ 571 mrr_r1_rightBSDLCAWarning 4;
BA_ "GenSigSendType" SG_ 571 mrr_r1_rightRCTAWarnning 4;
BA_ "GenSigSendType" SG_ 571 mrr_r1_rightDOWWarnning 4;
BA_ "GenSigStartValue" SG_ 571 mrr_r1_targetLongDisLR 20;
BA_ "GenSigStartValue" SG_ 571 mrr_r1_targetLongDisRR 20;
BA_ "GenSigStartValue" SG_ 577 vcu_brakePedalStsValid 1;
BA_ "GenSigStartValue" SG_ 577 vcu_actualGearValid 1;
BA_ "GenSigStartValue" SG_ 673 bcm_LeftMirrorSw 1;
BA_ "GenSigStartValue" SG_ 673 bcm_rightMirrorSw 1;
BA_ "GenSigStartValue" SG_ 674 esc_vlcTorqReq 8191;
BA_ "GenSigStartValue" SG_ 674 esc_vlcInterTargetAx 255;
BA_ "GenSigStartValue" SG_ 684 bcm_srm_srOpenPosition 127;
BA_ "GenSigStartValue" SG_ 684 bcm_ssm_ssOpenPosition 127;
BA_ "GenSigStartValue" SG_ 684 bcm_ebs_U_BATT 255;
BA_ "GenSigStartValue" SG_ 705 bcm_approachingUnlockFedb 1;
BA_ "GenSigStartValue" SG_ 705 bcm_followMeHomeFedb 3;
BA_ "GenSigStartValue" SG_ 705 bcm_awayLockFeedback 1;
BA_ "GenSigStartValue" SG_ 762 vcu_consumpRatio10km 500;
BA_ "GenSigStartValue" SG_ 762 vcu_consumpRatioInstant 500;
BA_ "GenSigStartValue" SG_ 769 vcu_avgPwrCurrentTrip 500;
BA_ "GenSigStartValue" SG_ 769 vcu_avgPwrSincelastcharge 500;
BA_ "GenSigStartValue" SG_ 769 vcu_avgPwroftripA 500;
BA_ "GenSigStartValue" SG_ 769 vcu_PwroftripB 5000;
BA_ "GenSigStartValue" SG_ 769 vcu_avgPwroftripB 500;
VAL_ 1029 amp_weightlowFrqSetSts 31 "No Command" 30 "Reserved" 29 "Reserved" 28 "Reserved" 27 "Reserved" 26 "Reserved" 25 "Reserved" 24 "Reserved" 23 "Reserved" 22 "Reserved" 21 "Reserved" 20 "10" 19 "9" 18 "8" 17 "7" 16 "6" 15 "5" 14 "4" 13 "3" 12 "2" 11 "1" 10 "0" 9 "-1" 8 "-2" 7 "-3" 6 "-4" 5 "-5" 4 "-6" 3 "-7" 2 "-8" 1 "-9" 0 "-10" ;
VAL_ 1029 AMP_STATUS_OVERVOLTAGE 1 "OverVoltage" 0 "Normal" ;
VAL_ 1029 AMP_STATUS_UNDERVOLTAGE 1 "UnderVoltage" 0 "Normal" ;
VAL_ 1029 AMP_STATUS_OVERTEMP 1 "OverTemp" 0 "Normal" ;
VAL_ 1029 AMP_STATUS_NO_A2B 1 "AMP No A2B" 0 "Normal" ;
VAL_ 1029 AMP_ZERO_SIGNAL_FROM_A2B 1 "No Signal from A2B" 0 "Normal" ;
VAL_ 1029 AMP_NO_EQ_SET 1 "No EQ Set" 0 "Normal" ;
VAL_ 1030 amp_vehicleSpeedCompModeSts 1 "ON" 0 "OFF" ;
VAL_ 1030 amp_highFrqSetSts 31 "No Command" 30 "Reserved" 29 "Reserved" 28 "Reserved" 27 "Reserved" 26 "Reserved" 25 "Reserved" 24 "Reserved" 23 "Reserved" 22 "Reserved" 21 "Reserved" 20 "10" 19 "9" 18 "8" 17 "7" 16 "6" 15 "5" 14 "4" 13 "3" 12 "2" 11 "1" 10 "0" 9 "-1" 8 "-2" 7 "-3" 6 "-4" 5 "-5" 4 "-6" 3 "-7" 2 "-8" 1 "-9" 0 "-10" ;
VAL_ 1030 amp_mediaVolSts 63 "No Request" 62 "Reserved" 61 "Reserved" 60 "Reserved" 59 "Reserved" 58 "Reserved" 57 "Reserved" 56 "Reserved" 55 "Reserved" 54 "Reserved" 53 "Reserved" 52 "Reserved" 51 "Reserved" 50 "Reserved" 49 "Reserved" 48 "Reserved" 47 "Reserved" 46 "Reserved" 45 "Reserved" 44 "Reserved" 43 "Reserved" 42 "Reserved" 41 "Reserved" 40 "Reserved" 39 "Reserved" 38 "Reserved" 37 "Reserved" 36 "Reserved" 35 "Reserved" 34 "Reserved" 33 "Reserved" 32 "Reserved" 31 "Reserved" 30 "30" 29 "29" 28 "28" 27 "27" 26 "26" 25 "25" 24 "24" 23 "23" 22 "22" 21 "21" 20 "20" 19 "19" 18 "18" 17 "17" 16 "16" 15 "15" 14 "14" 13 "13" 12 "12" 11 "11" 10 "10" 9 "9" 8 "8" 7 "7" 6 "6" 5 "5" 4 "4" 3 "3" 2 "2" 1 "1" 0 "0" ;
VAL_ 1030 amp_globalMuteSts 3 "No Command" 2 "Reserved" 1 "Mute" 0 "Unmute" ;
VAL_ 1030 amp_midFrqSetSts 31 "No Command" 30 "Reserved" 29 "Reserved" 28 "Reserved" 27 "Reserved" 26 "Reserved" 25 "Reserved" 24 "Reserved" 23 "Reserved" 22 "Reserved" 21 "Reserved" 20 "10" 19 "9" 18 "8" 17 "7" 16 "6" 15 "5" 14 "4" 13 "3" 12 "2" 11 "1" 10 "0" 9 "-1" 8 "-2" 7 "-3" 6 "-4" 5 "-5" 4 "-6" 3 "-7" 2 "-8" 1 "-9" 0 "-10" ;
VAL_ 1030 amp_lowFrqSetSts 31 "No Command" 30 "Reserved" 29 "Reserved" 28 "Reserved" 27 "Reserved" 26 "Reserved" 25 "Reserved" 24 "Reserved" 23 "Reserved" 22 "Reserved" 21 "Reserved" 20 "10" 19 "9" 18 "8" 17 "7" 16 "6" 15 "5" 14 "4" 13 "3" 12 "2" 11 "1" 10 "0" 9 "-1" 8 "-2" 7 "-3" 6 "-4" 5 "-5" 4 "-6" 3 "-7" 2 "-8" 1 "-9" 0 "-10" ;
VAL_ 1030 amp_dyaudioSoundFeatureSts 3 "Speech mode" 2 "Soft mode" 1 "Dynamic mode" 0 "Original sound mode" ;
VAL_ 1030 amp_loudnessSts 1 "Off" 0 "On" ;
VAL_ 1030 amp_soundFieldSts 3 "Back row passenger" 2 "Front passenger" 1 "Driver" 0 "All passenger" ;
VAL_ 1030 amp_audioBlcSts 31 "No Command" 30 "Reserved" 29 "Reserved" 28 "Reserved" 27 "Reserved" 26 "Reserved" 25 "Reserved" 24 "Reserved" 23 "Reserved" 22 "Reserved" 21 "Reserved" 20 "Right+10" 19 "Right+9" 18 "Right+8" 17 "Right+7" 16 "Right+6" 15 "Right+5" 14 "Right+4" 13 "Right+3" 12 "Right+2" 11 "Right+1" 10 "Center" 9 "Left+1" 8 "Left+2" 7 "Left+3" 6 "Left+4" 5 "Left+5" 4 "Left+6" 3 "Left+7" 2 "Left+8" 1 "Left+9" 0 "Left+10" ;
VAL_ 1030 amp_audioFaderSts 31 "No Command" 30 "Reserved" 29 "Reserved" 28 "Reserved" 27 "Reserved" 26 "Reserved" 25 "Reserved" 24 "Reserved" 23 "Reserved" 22 "Reserved" 21 "Reserved" 20 "Front+10" 19 "Front+9" 18 "Front+8" 17 "Front+7" 16 "Front+6" 15 "Front+5" 14 "Front+4" 13 "Front+3" 12 "Front+2" 11 "Front+1" 10 "Center" 9 "Rear+1" 8 "Rear+2" 7 "Rear+3" 6 "Rear+4" 5 "Rear+5" 4 "Rear+6" 3 "Rear+7" 2 "Rear+8" 1 "Rear+9" 0 "Rear+10" ;
VAL_ 1609 AMP_RMR 1 "Repeat Message State requested" 0 "Repeat Message State not requested" ;
VAL_ 1609 AMP_AWB 1 "Node has woken up the network (active Wakeup)" 0 "Node has not woken up the network (passive wakeup)" ;
VAL_ 1014 etc_VINIdentification 1 "Difference" 0 "No difference" ;
VAL_ 1014 etc_disassemblySts 1 "Inactive" 0 "Active" ;
VAL_ 1014 etc_lockSts 1 "Lock" 0 "Unlock" ;
VAL_ 1014 etc_detect 1 "Error" 0 "OK" ;
VAL_ 1026 etc_tranStauts 1 "Fail" 0 "Successful" ;
VAL_ 1027 etc_dataSts 4 "Exit Data" 3 "Entrance Data" 0 "Reserved" ;
VAL_ 1553 ETC_RMR 1 "Repeat Message State requested" 0 "Repeat Message State not requested" ;
VAL_ 1553 ETC_AWB 1 "Node has woken up the network (active Wakeup)" 0 "Node has not woken up the network (passive wakeup)" ;
VAL_ 16 ble_rke_lockCtrlReq 3 "Reserved" 2 "Lock" 1 "Unlock" 0 "No Request" ;
VAL_ 16 ble_rke_tailgateCtrlReq 3 "Reserved" 2 "Close" 1 "Open" 0 "No Request" ;
VAL_ 16 ble_rke_carSearchReq 1 "Request" 0 "No Request" ;
VAL_ 16 ble_rke_sunRoofGlassCmd 3 "Reserved" 2 "Glass Close" 1 "Glass Open" 0 "No Request" ;
VAL_ 16 ble_rke_winCtrlReq 3 "Reserved" 2 "Window Down" 1 "Window Up" 0 "No Request" ;
VAL_ 16 ble_rke_chrgCapCtrlReq 1 "Request" 0 "No Request" ;
VAL_ 16 ble_dvrTakePicCtrl 1 "Request" 0 "No Request" ;
VAL_ 16 ble_welcomeCmd 3 "远离自动闭锁" 2 "靠近自动解锁" 1 "迎宾请求" 0 "Invalid" ;
VAL_ 16 ble_easyEntryManualSw 3 "Reserved" 2 "Off（手动上升）" 1 "On（手动下降）" 0 "No request" ;
VAL_ 16 ble_rke_chrgGunUnlockCtrlReq 1 "Request" 0 "No request" ;
VAL_ 16 ble_rke_fuelPortCapOpenCtrl 3 "INVALID" 2 "RESERVED" 1 "OPEN_FUELPORT" 0 "NO_COMMAND_FUELPORT" ;
VAL_ 20 bms_cellTemperatureDifferenceHig 3 "Level3" 2 "Level2" 1 "Level1" 0 "No error" ;
VAL_ 20 bms_batteryOverTemperature 3 "Level3" 2 "Level2" 1 "Level1" 0 "No error" ;
VAL_ 20 bms_overVoltage 3 "Level3" 2 "Level2" 1 "Level1" 0 "No error" ;
VAL_ 20 bms_lowVoltage 3 "Level3" 2 "Level2" 1 "Level1" 0 "No error" ;
VAL_ 20 bms_lowSoc 3 "Level3" 2 "Level2" 1 "Level1" 0 "No error" ;
VAL_ 20 bms_cellOverVoltage 3 "Level3" 2 "Level2" 1 "Level1" 0 "No error" ;
VAL_ 20 bms_cellLowVoltage 3 "Level3" 2 "Level2" 1 "Level1" 0 "No error" ;
VAL_ 20 bms_highSoc 3 "Level3" 2 "Level2" 1 "Level1" 0 "No error" ;
VAL_ 20 bms_socStepChange 3 "Level3" 2 "Level2" 1 "Level1" 0 "No error" ;
VAL_ 20 bms_chargerMismatch 3 "Level3" 2 "Level2" 1 "Level1" 0 "No error" ;
VAL_ 20 bms_cellOutOfBalance 3 "Level3" 2 "Level2" 1 "Level1" 0 "No error" ;
VAL_ 20 bms_isolationFault 3 "Level3" 2 "Level2" 1 "Level1" 0 "No error" ;
VAL_ 20 bms_hvilFault 3 "Level3" 2 "Level2" 1 "Level1" 0 "No error" ;
VAL_ 20 bms_batteryOverCharge 3 "Level3" 2 "Level2" 1 "Level1" 0 "No error" ;
VAL_ 81 bcm_failCode 255 "INVALID" 254 "Reserved" 253 "Reserved" 252 "Reserved" 251 "Reserved" 250 "Reserved" 249 "Reserved" 248 "Reserved" 247 "Reserved" 246 "Reserved" 245 "Reserved" 244 "Reserved" 243 "Reserved" 242 "Reserved" 241 "Reserved" 240 "Reserved" 239 "Reserved" 238 "Reserved" 237 "Reserved" 236 "Reserved" 235 "Reserved" 234 "Reserved" 233 "Reserved" 232 "Reserved" 231 "Reserved" 230 "Reserved" 229 "Reserved" 228 "Reserved" 227 "Reserved" 226 "Reserved" 225 "Reserved" 224 "Reserved" 223 "Reserved" 222 "Reserved" 221 "Reserved" 220 "Reserved" 219 "Reserved" 218 "Reserved" 217 "Reserved" 216 "Reserved" 215 "Reserved" 214 "Reserved" 213 "Reserved" 212 "Reserved" 211 "Reserved" 210 "Reserved" 209 "Reserved" 208 "Reserved" 207 "Reserved" 206 "Reserved" 205 "Reserved" 204 "Reserved" 203 "Reserved" 202 "Reserved" 201 "Reserved" 200 "Reserved" 199 "Reserved" 198 "Reserved" 197 "Reserved" 196 "Reserved" 195 "Reserved" 194 "Reserved" 193 "Reserved" 192 "Reserved" 191 "Reserved" 190 "Reserved" 189 "Reserved" 188 "Reserved" 187 "Reserved" 186 "Reserved" 185 "Reserved" 184 "Reserved" 183 "Reserved" 182 "Reserved" 181 "Reserved" 180 "Reserved" 179 "Reserved" 178 "Reserved" 177 "Reserved" 176 "Reserved" 175 "Reserved" 174 "Reserved" 173 "Reserved" 172 "Reserved" 171 "Reserved" 170 "Reserved" 169 "Reserved" 168 "Reserved" 167 "Reserved" 166 "Reserved" 165 "Reserved" 164 "Reserved" 163 "Reserved" 162 "Reserved" 161 "Reserved" 160 "Reserved" 159 "Reserved" 158 "Reserved" 157 "Reserved" 156 "Reserved" 155 "Reserved" 154 "Reserved" 153 "Reserved" 152 "Reserved" 151 "Reserved" 150 "Reserved" 149 "Reserved" 148 "Reserved" 147 "Reserved" 146 "Reserved" 145 "Reserved" 144 "Reserved" 143 "Reserved" 142 "Reserved" 141 "Reserved" 140 "Reserved" 139 "Reserved" 138 "Reserved" 137 "Reserved" 136 "Reserved" 135 "Reserved" 134 "Reserved" 133 "Reserved" 132 "Reserved" 131 "Reserved" 130 "Reserved" 129 "Reserved" 128 "Reserved" 127 "Reserved" 126 "Reserved" 125 "Reserved" 124 "Reserved" 123 "Reserved" 122 "Reserved" 121 "Reserved" 120 "Reserved" 119 "Reserved" 118 "Reserved" 117 "Reserved" 116 "Reserved" 115 "Reserved" 114 "Reserved" 113 "Reserved" 112 "Reserved" 111 "Reserved" 110 "Reserved" 109 "Reserved" 108 "Reserved" 107 "Reserved" 106 "Reserved" 105 "Reserved" 104 "Reserved" 103 "Reserved" 102 "Reserved" 101 "Reserved" 100 "Reserved" 99 "Reserved" 98 "Reserved" 97 "Reserved" 96 "Reserved" 95 "Reserved" 94 "Reserved" 93 "Reserved" 92 "Reserved" 91 "Reserved" 90 "Reserved" 89 "Reserved" 88 "Reserved" 87 "Reserved" 86 "Reserved" 85 "Reserved" 84 "Reserved" 83 "Reserved" 82 "Reserved" 81 "Reserved" 80 "Reserved" 79 "Reserved" 78 "Reserved" 77 "Reserved" 76 "Reserved" 75 "Reserved" 74 "Reserved" 73 "Reserved" 72 "Reserved" 71 "Reserved" 70 "Reserved" 69 "Reserved" 68 "Reserved" 67 "Reserved" 66 "Reserved" 65 "Reserved" 64 "Reserved" 63 "Reserved" 62 "Reserved" 61 "Reserved" 60 "Reserved" 59 "Reserved" 58 "Reserved" 57 "Reserved" 56 "Reserved" 55 "Reserved" 54 "Reserved" 53 "Reserved" 52 "Reserved" 51 "Reserved" 50 "Reserved" 49 "Reserved" 48 "Reserved" 47 "Reserved" 46 "Reserved" 45 "Reserved" 44 "Reserved" 43 "Reserved" 42 "Reserved" 41 "Reserved" 40 "Reserved" 39 "Reserved" 38 "Reserved" 37 "Reserved" 36 "Reserved" 35 "Reserved" 34 "Reserved" 33 "Reserved" 32 "Reserved" 31 "Reserved" 30 "Reserved" 29 "Reserved" 28 "Reserved" 27 "Reserved" 26 "Reserved" 25 "Reserved" 24 "Reserved" 23 "Reserved" 22 "vehicle is in Crash states" 21 "Communication error （CAN lost or BUSOFF）" 20 "RemotePower on by gear shift isn’t P" 19 "RemotePower on refuse by vehicle speed" 18 "BCM/BMS authentication failure" 17 "SSB is pressed" 15 "Brake is pressed" 14 "HV is NOT ON" 13 "key found in cabin" 12 "Voltage out of range" 11 "RemoteCarATWSStatusNotArmed" 10 "RemoteCarTeleOptionNotSet" 9 "RemoteSunRoofTeleOptionNotSet" 8 "RemoteLiftWindowTeleOptionNotSet" 7 "Hood not closed" 6 "Any door of 4 doors not closed" 5 "Remote? Command by powermode isn‘t? normal OFF" 4 "RemotePowerCtrl_TRY_CNT_Max" 3 "RemotePowerCtrl_CNT _Max" 2 "BCM / TBOX authentication fails" 1 "PEPS not learnt" 0 "Not fail" ;
VAL_ 273 vcu_gear 3 "D" 2 "N" 1 "R" 0 "P" ;
VAL_ 273 vcu_state 17 "BATTPACK_CHARGE" 16 "AC_CHARGE_SHUT_DOWN" 15 "AC_CHARGE_ENABLE" 14 "AC_CHARGE_STANDBY" 13 "PRECHARGE_SHUT_DOWN" 12 "PRECHARGE_INIT" 11 "UNIT_IDLE" 10 "UNIT_ENABLE" 9 "UNIT_STANDBY" 8 "PT_HV_SHUT_DOWN" 7 "PT_HV_STANDBY_NO_DRIVE" 6 "PT_HV_INIT_NO_DRIVE" 5 "PT_HV_STANDBY_DRIVE" 4 "PT_HV_INIT_DRIVE" 3 "IMMOBILISER" 2 "PT_LV_OFF" 1 "PT_LV_STANDBY" 0 "INIT" ;
VAL_ 273 vcu_stateCmd_mcur0 15 "None" 14 "None" 13 "None" 12 "None" 11 "None" 10 "OFF" 9 "ACTIVE_DISCHARGE" 8 "IDLE" 7 "AUTO_RETRY" 6 "HARD_FAULT" 5 "GPO" 4 "LIMP" 3 "ENABLE" 2 "STANDBY" 1 "SOPT" 0 "INIT" ;
VAL_ 273 vcu_stateCmd_mcuf0 15 "None" 14 "None" 13 "None" 12 "None" 11 "None" 10 "OFF" 9 "ACTIVE_DISCHARGE" 8 "IDLE" 7 "AUTO_RETRY" 6 "HARD_FAULT" 5 "GPO" 4 "TURTLE" 3 "ENABLE" 2 "STANDBY" 1 "SOPT" 0 "INIT" ;
VAL_ 273 vcu_stateCmd_bms 15 "None" 14 "None" 13 "None" 12 "None" 11 "None" 10 "DC_PREHEAT" 9 "AC_PREHEAT" 8 "FAULT" 7 "OFF" 6 "SHUT_DOWN" 5 "DC_CHARGE" 4 "AC_CHARGE" 3 "CONTACTORS_CLOSED" 2 "PRECHARGE" 1 "STANDBY" 0 "INIT" ;
VAL_ 273 vcu_chargePortIsConnected 1 "CONNECT" 0 "DISCONNECT" ;
VAL_ 273 vcu_brakePedalPressed 1 "TRUE" 0 "FALSE" ;
VAL_ 273 vcu_BrakeWarning 1 "Request" 0 "No_Request" ;
VAL_ 273 vcu_accelPosValid 1 "VALID" 0 "INVALID" ;
VAL_ 273 vcu_chrgAllowed_bms 3 "RESERVED" 2 "PAUSED" 1 "ALLOWED" 0 "NOT_ALLOWED" ;
VAL_ 276 bms_state 9 "PREHEAT" 8 "FAULT" 7 "OFF" 6 "SHUT_DOWN" 5 "DC_CHARGE" 4 "AC_CHARGE" 3 "CONTACTORS_CLOSED" 2 "PRECHARGE" 1 "STANDBY" 0 "INIT" ;
VAL_ 276 bms_dcChargeState 6 "FAULT" 5 "RECOVERY_FAULT" 4 "CHARGE_END" 3 "CHARGING" 2 "STANDBY" 1 "INIT" 0 "OFF" ;
VAL_ 276 bms_acChargeState 6 "FAULT" 5 "RECOVERY_FAULT" 4 "CHARGE_END" 3 "CHARGING" 2 "STANDBY" 1 "INIT" 0 "OFF" ;
VAL_ 276 bms_hvil 1 "ON" 0 "OFF" ;
VAL_ 276 bms_isolationState 3 "None" 2 "FAULT" 1 "NORMAL" 0 "UNKNOWN" ;
VAL_ 276 bms_contactorState 15 "None" 14 "FAULT" 13 "SD_FINISH" 12 "SHUTDOWN" 11 "SD_START" 10 "CMC_FINISH" 9 "CMC_OPEN_PRECHG" 8 "CMC_WAIT_POST_NEG" 7 "CMC_CLOSE_POS_MAIN" 6 "CMC_START" 5 "PRECHG_FINISH" 4 "PRECHG_CLOSE_PRECHG" 3 "PRECHG_WAIT_POST_NEG" 2 "PRECHG_CLOSE_NEG_MAIN" 1 "PRECHG_START" 0 "IDLE" ;
VAL_ 276 bms_chargeInhibit 1 "TRUE" 0 "FALSE" ;
VAL_ 276 bms_acChargeConnection 1 "CONNECT" 0 "DISCONNECT" ;
VAL_ 276 bms_dcChargeConnection 1 "CONNECT" 0 "DISCONNECT" ;
VAL_ 276 bms_alertLevel 3 "Level3" 2 "Level2" 1 "Level1" 0 "No Error" ;
VAL_ 276 bms_authenticationResult 3 "RESERVE_AUTH" 2 "AUTH_SUCCESS" 1 "AUTH_FAILED" 0 "UINITIAL_OR_AUTH_INPROGRESS" ;
VAL_ 276 bms_chargeReq 1 "Request" 0 "No_Request" ;
VAL_ 276 bms_battWarmState 3 "ENABLE" 2 "STANDBY" 1 "INIT" 0 "OFF" ;
VAL_ 276 bms_ptcEna 1 "ENABLE" 0 "DISABLE" ;
VAL_ 276 bms_faultHvShutdownReq 3 "INVALID1" 2 "REQUEST" 1 "NO_REQUEST" 0 "INVALID0" ;
VAL_ 288 ecu_ToltalFaultNum 255 "Invalid" ;
VAL_ 288 mcur0_0x102_timeoutFlag 1 "Timeout" 0 "Normal" ;
VAL_ 288 mcuf0_0x103_timeoutFlag 1 "Timeout" 0 "Normal" ;
VAL_ 288 ecu_0x38B_timeoutFlag 1 "Timeout" 0 "Normal" ;
VAL_ 290 esc_wheelSpeedRL 8191 "Invalid" ;
VAL_ 290 esc_wheelSpeedRLValid 1 "VALID" 0 "INVALID" ;
VAL_ 290 esc_wheelSpeedRR 8191 "Invalid" ;
VAL_ 290 esc_wheelSpeedRRValid 1 "VALID" 0 "INVALID" ;
VAL_ 294 bms_revErrAmount 255 "Invalid" ;
VAL_ 294 bms_revErrNO 8191 "Invalid" ;
VAL_ 294 bms_batVoltagefault 1 "fault" 0 "No_fault" ;
VAL_ 294 bms_fastChargeTap1 511 "Invalid" ;
VAL_ 294 bms_fastChargeTap2 511 "Invalid" ;
VAL_ 304 esc_longAcceleration 8191 "Invalid" ;
VAL_ 304 esc_yawRateValid 1 "VALID" 0 "INVALID" ;
VAL_ 304 asc_autoEasyEntryFb 1 "Enable" 0 "Not Enable" ;
VAL_ 304 apa_WarningReq 1 "Warning" 0 "No Warning" ;
VAL_ 304 esc_lateralAcceleration 8191 "Invalid" ;
VAL_ 304 asc_driveModeFb 7 "Reserved" 6 "Reserved" 5 "Individual mode" 4 "Offroad mode" 3 "Sport mode" 2 "Comfort mode" 1 "ECO mode" 0 "No  request" ;
VAL_ 304 esc_yawRate 65535 "Invalid" ;
VAL_ 304 asc_ascSysSts 4 "Function Shutdown" 3 "AxisHolding" 2 "AxisLowering" 1 "AxisLifting" 0 "InValid" ;
VAL_ 304 asc_maintainMode 1 "Active" 0 "Inactive" ;
VAL_ 304 asc_ASC_errorSts 3 "fault priority 3(Very seriously)" 2 "fault priority 2(seriously)" 1 "fault priority 1(minor)" 0 "no error" ;
VAL_ 304 ASC_SusTempAdjustStatus 1 "Disable" 0 "Enable" ;
VAL_ 304 asc_highwayMode 1 "Active" 0 "Inactive" ;
VAL_ 304 ASC_SuspensionCurrentLevel 15 "Reserved" 14 "Reserved" 13 "Reserved" 12 "Reserved" 11 "Reserved" 10 "Reserved" 9 "Very low level" 8 "Between low and very low level" 7 "Low level" 6 "Between normal and low level" 5 "Normal level" 4 "Between high and normal level" 3 "High level" 2 "Between very high and high level" 1 "Very high level" 0 "Invalid" ;
VAL_ 304 asc_easyEntryEnable 1 "Enable" 0 "Not Enable" ;
VAL_ 304 apa_funcSts 7 "Invalid" 6 "Suspend" 5 "Failure" 4 "Completed Sucessfully" 3 "Guidance active" 2 "Searching" 1 "Standby" 0 "Off" ;
VAL_ 320 hcm_0x100_timeoutFlag 1 "Timeout" 0 "Normal" ;
VAL_ 320 hcm_0x110_timeoutFlag 1 "Timeout" 0 "Normal" ;
VAL_ 320 hcm_leftHighBeamFaultSt 1 "fault" 0 "no fault" ;
VAL_ 320 hcm_adbFuctionStsLt 3 "active" 2 "enable" 1 "standby" 0 "Init" ;
VAL_ 320 hcm_rightHighBeamFaultSt 1 "fault" 0 "no fault" ;
VAL_ 320 hcm_adbFuctionStsRt 3 "active" 2 "enable" 1 "standby" 0 "Init" ;
VAL_ 320 ac_0x3A6_timeoutFlag 1 "Timeout" 0 "Normal" ;
VAL_ 320 hcm_middleLeftPositionLampFault 1 "fault" 0 "good" ;
VAL_ 320 hcm_middleRightPositionLampFault 1 "fault" 0 "good" ;
VAL_ 320 hcm_hcmHeightSetLt 7 "Reserved" 6 "Reserved" 5 "Level 5" 4 "Level 4" 3 "Level 3" 2 "Level 2" 1 "Level 1" 0 "UNDEFINED" ;
VAL_ 320 hcm_hcmHeightSetRt 7 "Reserved" 6 "Reserved" 5 "Level 5" 4 "Level 4" 3 "Level 3" 2 "Level 2" 1 "Level 1" 0 "UNDEFINEDt" ;
VAL_ 320 hcm_leftHighBeamLedsFaultSt 1 "fault" 0 "no fault" ;
VAL_ 320 hcm_leftHighBeamDriFaultWarning 2 "undervoltage warning" 1 "overvoltage warning" 0 "no warning" ;
VAL_ 320 hcm_leftLowBeamFaultSt 1 "fault" 0 "no fault" ;
VAL_ 320 hcm_turnLampWarningLt 1 "Warning" 0 "No Warning" ;
VAL_ 320 hcm_positionLampWarningLt 1 "Warning" 0 "No Warning" ;
VAL_ 320 hcm_dayTimeRunningLampWarningLt 1 "Warning" 0 "No Warning" ;
VAL_ 320 hcm_rightHighBeamLedsFaultSt 1 "fault" 0 "no fault" ;
VAL_ 320 hcm_rightHighBeamDriFaultWarning 2 "undervoltage warning" 1 "overvoltage warning" 0 "no warning" ;
VAL_ 320 hcm_rightLowBeamFaultSt 1 "fault" 0 "no fault" ;
VAL_ 320 hcm_turnLampWarningRt 1 "Warning" 0 "No Warning" ;
VAL_ 320 hcm_positionLampWarningRt 1 "Warning" 0 "No Warning" ;
VAL_ 320 hcm_dayTimeRunningLampWarningRt 1 "Warning" 0 "No Warning" ;
VAL_ 322 esc_wheelSpeedFL 8191 "Invalid" ;
VAL_ 322 esc_wheelSpeedFLValid 1 "VALID" 0 "INVALID" ;
VAL_ 322 esc_wheelSpeedFR 8191 "Invalid" ;
VAL_ 322 esc_wheelSpeedFRValid 1 "VALID" 0 "INVALID" ;
VAL_ 324 eps_sasSteeringAngle 65535 "Invalid" ;
VAL_ 324 eps_sasRawSteeringAngle 65535 "Invalid" ;
VAL_ 324 eps_sasSteeringAngleSpd 65535 "Invalid" ;
VAL_ 324 eps_sasSteeringAngleSpdValid 1 "VALID" 0 "INVALID" ;
VAL_ 324 eps_calibratedSts 1 "CALIBRATED" 0 "NOT_CALIBRATED" ;
VAL_ 324 eps_sasSteeringAngleValid 1 "VALID" 0 "INVALID" ;
VAL_ 324 eps_sasRawSteeringAngleValid 1 "VALID" 0 "INVALID" ;
VAL_ 419 APA_PDCRearMidLeftRegObjSts 30 "Error" 25 "150cm" 24 "145cm" 23 "140cm" 22 "135cm" 21 "130cm" 20 "125cm" 19 "120cm" 18 "115cm" 17 "110cm" 16 "105cm" 15 "100cm" 14 "95cm" 13 "90cm" 12 "85cm" 11 "80cm" 10 "75cm" 9 "70cm" 8 "65cm" 7 "60cm" 6 "55cm" 5 "50cm" 4 "45cm" 3 "40cm" 2 "35cm" 1 "≤30cm" 0 "No Object" ;
VAL_ 419 APA_PDCSysSts 2 "Failed" 1 "Active" 0 "Inactive" ;
VAL_ 419 APA_PDCFailureWarning 1 "Warning on" 0 "No warning" ;
VAL_ 419 APA_PDCRearLeftRegObjSts 30 "Error" 25 "150cm" 24 "145cm" 23 "140cm" 22 "135cm" 21 "130cm" 20 "125cm" 19 "120cm" 18 "115cm" 17 "110cm" 16 "105cm" 15 "100cm" 14 "95cm" 13 "90cm" 12 "85cm" 11 "80cm" 10 "75cm" 9 "70cm" 8 "65cm" 7 "60cm" 6 "55cm" 5 "50cm" 4 "45cm" 3 "40cm" 2 "35cm" 1 "≤30cm" 0 "No Object" ;
VAL_ 419 APA_PDCOnOffSts 3 "PAS SW Inhibited" 2 "PAS SW OFF" 1 "PAS SW ON" 0 "Invalid" ;
VAL_ 419 APA_PDCFrontLeftRegObjSts 30 "Error" 25 "150cm" 24 "145cm" 23 "140cm" 22 "135cm" 21 "130cm" 20 "125cm" 19 "120cm" 18 "115cm" 17 "110cm" 16 "105cm" 15 "100cm" 14 "95cm" 13 "90cm" 12 "85cm" 11 "80cm" 10 "75cm" 9 "70cm" 8 "65cm" 7 "60cm" 6 "55cm" 5 "50cm" 4 "45cm" 3 "40cm" 2 "35cm" 1 "≤30cm" 0 "No Object" ;
VAL_ 419 APA_PDCAudibleFrontBeepRate 7 "Reserved" 6 "Reserved" 5 "Reserved" 4 "Warning on" 3 "4 Hz" 2 "2 Hz" 1 "1 Hz" 0 "No warning" ;
VAL_ 419 APA_PDCRearRightRegObjSts 30 "Error" 25 "150cm" 24 "145cm" 23 "140cm" 22 "135cm" 21 "130cm" 20 "125cm" 19 "120cm" 18 "115cm" 17 "110cm" 16 "105cm" 15 "100cm" 14 "95cm" 13 "90cm" 12 "85cm" 11 "80cm" 10 "75cm" 9 "70cm" 8 "65cm" 7 "60cm" 6 "55cm" 5 "50cm" 4 "45cm" 3 "40cm" 2 "35cm" 1 "≤30cm" 0 "No Object" ;
VAL_ 419 APA_PDCAudibleRearBeepRate 7 "Reserved" 6 "Reserved" 5 "Reserved" 4 "Warning on" 3 "4 Hz" 2 "2 Hz" 1 "1 Hz" 0 "No warning" ;
VAL_ 419 APA_PDCFrontRightRegObjSts 30 "Error" 25 "150cm" 24 "145cm" 23 "140cm" 22 "135cm" 21 "130cm" 20 "125cm" 19 "120cm" 18 "115cm" 17 "110cm" 16 "105cm" 15 "100cm" 14 "95cm" 13 "90cm" 12 "85cm" 11 "80cm" 10 "75cm" 9 "70cm" 8 "65cm" 7 "60cm" 6 "55cm" 5 "50cm" 4 "45cm" 3 "40cm" 2 "35cm" 1 "≤30cm" 0 "No Object" ;
VAL_ 419 APA_PDCFrontMidLeftRegObjSts 30 "Error" 25 "150cm" 24 "145cm" 23 "140cm" 22 "135cm" 21 "130cm" 20 "125cm" 19 "120cm" 18 "115cm" 17 "110cm" 16 "105cm" 15 "100cm" 14 "95cm" 13 "90cm" 12 "85cm" 11 "80cm" 10 "75cm" 9 "70cm" 8 "65cm" 7 "60cm" 6 "55cm" 5 "50cm" 4 "45cm" 3 "40cm" 2 "35cm" 1 "≤30cm" 0 "No Object" ;
VAL_ 419 APA_PDCRearMidRightRegObjSts 30 "Error" 25 "150cm" 24 "145cm" 23 "140cm" 22 "135cm" 21 "130cm" 20 "125cm" 19 "120cm" 18 "115cm" 17 "110cm" 16 "105cm" 15 "100cm" 14 "95cm" 13 "90cm" 12 "85cm" 11 "80cm" 10 "75cm" 9 "70cm" 8 "65cm" 7 "60cm" 6 "55cm" 5 "50cm" 4 "45cm" 3 "40cm" 2 "35cm" 1 "≤30cm" 0 "No Object" ;
VAL_ 419 APA_PDCFrontMidRightRegObjSts 30 "Error" 25 "150cm" 24 "145cm" 23 "140cm" 22 "135cm" 21 "130cm" 20 "125cm" 19 "120cm" 18 "115cm" 17 "110cm" 16 "105cm" 15 "100cm" 14 "95cm" 13 "90cm" 12 "85cm" 11 "80cm" 10 "75cm" 9 "70cm" 8 "65cm" 7 "60cm" 6 "55cm" 5 "50cm" 4 "45cm" 3 "40cm" 2 "35cm" 1 "≤30cm" 0 "No Object" ;
VAL_ 515 apa_avmSts 15 "Reserved" 14 "Reserved" 13 "Reserved" 12 "Reserved" 11 "Reserved" 10 "Reserved" 9 "Reserved" 8 "Reserved" 7 "Reserved" 6 "Reserved" 5 "Reserved" 4 "Reserved" 3 "ACC on, APA temporarily unavailable" 2 "APA ON" 1 "AVM ON" 0 "Standby state" ;
VAL_ 515 apa_avmHmiIndex 15 "Reserved" 14 "Reserved" 13 "Reserved" 12 "Reserved" 11 "Reserved" 10 "Reserved" 9 "Reserved" 8 "Reserved" 7 "Reserved" 6 "Reserved" 5 "Reserved" 4 "Reserved" 3 "Reserved" 2 "EOL/Test" 1 "Main screen" 0 "OFF" ;
VAL_ 515 apa_avmViewMode 3 "Reserved" 2 "Reserved" 1 "2D View Mode" 0 "3D View Mode" ;
VAL_ 515 apa_avmDisplayReq 3 "Reserved" 2 "Request to display small View" 1 "Request to display normal view" 0 "No request" ;
VAL_ 515 apa_avmMODSts 3 "Reserved" 2 "Reserved" 1 "ON" 0 "OFF" ;
VAL_ 515 apa_avmFrontCaneraFailed 1 "Fault" 0 "No Fault" ;
VAL_ 515 apa_avmRearCaneraFailed 1 "Fault" 0 "No Fault" ;
VAL_ 515 apa_avmLeftCaneraFailed 1 "Fault" 0 "No Fault" ;
VAL_ 515 apa_avmRightCaneraFailed 1 "Fault" 0 "No Fault" ;
VAL_ 515 apa_avmVideoOutputFailed 1 "Fault" 0 "No Fault" ;
VAL_ 515 apa_avmControllerOperatingFailed 1 "Fault" 0 "No Fault" ;
VAL_ 515 apa_keytriggersts 1 "Active" 0 "Inactive" ;
VAL_ 515 apa_avmTrigByTurnningSts 1 "On" 0 "Off" ;
VAL_ 515 apa_avmSingleViewSts 31 "Reserved" 30 "Reserved" 29 "Reserved" 28 "Reserved" 27 "Reserved" 26 "Reserved" 25 "Reserved" 24 "Reserved" 23 "Reserved" 22 "Reserved" 21 "Reserved" 20 "Reserved" 19 "Reserved" 18 "Reserved" 17 "Reserved" 16 "Reserved" 15 "Side View" 14 "Dynamic rear view" 13 "Dynamic front view" 12 "3D Rear-Right view" 11 "3D Rear-Left view" 10 "3D Front-Right view" 9 "3D Front-Left view" 8 "3D Right side view" 7 "3D Left side view" 6 "3D Top view of the trail" 5 "3D Top view of the head" 4 "2D Right view" 3 "2D Left view" 2 "2D Rear view" 1 "2D Front view" 0 "3D rotation view" ;
VAL_ 515 apa_avmFrontModWarningSts 1 "Warning" 0 "No Warning" ;
VAL_ 515 apa_avmRearModWarningSts 1 "Warning" 0 "No Warning" ;
VAL_ 515 apa_avmLeftModWarningSts 1 "Warning" 0 "No Warning" ;
VAL_ 515 apa_avmRightModWarningSts 1 "Warning" 0 "No Warning" ;
VAL_ 515 apa_avmCalibrationSts 1 "Calibrated" 0 "Not calibrated" ;
VAL_ 515 apa_avmTrajectory_display 1 "ON" 0 "OFF" ;
VAL_ 515 apa_avmAutoswitching_display 1 "ON" 0 "OFF" ;
VAL_ 515 apa_avmCarBodyTransparent 1 "ON" 0 "OFF" ;
VAL_ 515 apa_avmSwSts 1 "Inhibited" 0 "Normal" ;
VAL_ 515 apa_avmMonitVideoOutput 1 "Request" 0 "No request" ;
VAL_ 515 apa_avmPDCfailureWarn 7 "Reserved" 6 "Reserved" 5 "Reserved" 4 "PDC&&AVM failuer warning" 3 "AVM failure warning" 2 "PDC failure warning" 1 "APA failure warning" 0 "No warning" ;
VAL_ 515 apa_avm_QuitSw 1 "Inhibited" 0 "Normal" ;
VAL_ 515 APA_AVM_Voicefeedback 17 "VCU not ready" 16 "ACC ON" 15 "speed too high" 14 "APA failure" 13 "APA already closed" 12 "APA closed" 11 "APA already open" 10 "APA open" 9 "CarbodyTransparent already closed" 8 "CarbodyTransparent closed" 7 "CarbodyTransparent already open" 6 "CarbodyTransparent open" 5 "AVM failure" 4 "AVM already closed" 3 "AVM closed" 2 "AVM already open" 1 "AVM open" 0 "No Request" ;
VAL_ 520 avm_sts 15 "Reserved" 14 "Reserved" 13 "Reserved" 12 "Reserved" 11 "Reserved" 10 "Reserved" 9 "Reserved" 8 "Reserved" 7 "Reserved" 6 "Reserved" 5 "Reserved" 4 "Reserved" 3 "Reserved" 2 "Reserved" 1 "AVM ON" 0 "Standby state" ;
VAL_ 520 avm_hmiIndex 15 "Reserved" 14 "Reserved" 13 "Reserved" 12 "Reserved" 11 "Reserved" 10 "Reserved" 9 "Reserved" 8 "Reserved" 7 "Reserved" 6 "Reserved" 5 "Reserved" 4 "Reserved" 3 "Reserved" 2 "EOL/Test" 1 "Main screen" 0 "OFF" ;
VAL_ 520 avm_viewMode 3 "Reserved" 2 "Reserved" 1 "2D View Mode" 0 "3D View Mode" ;
VAL_ 520 avm_displayReq 3 "Reserved" 2 "Request to display small View" 1 "Request to display normal view" 0 "No request" ;
VAL_ 520 avm_MODSts 3 "Reserved" 2 "Reserved" 1 "ON" 0 "OFF" ;
VAL_ 520 avm_frontCaneraFailed 1 "Fault" 0 "No Fault" ;
VAL_ 520 avm_rearCaneraFailed 1 "Fault" 0 "No Fault" ;
VAL_ 520 avm_leftCaneraFailed 1 "Fault" 0 "No Fault" ;
VAL_ 520 avm_rightCaneraFailed 1 "Fault" 0 "No Fault" ;
VAL_ 520 avm_videoOutputFailed 1 "Fault" 0 "No Fault" ;
VAL_ 520 avm_controllerOperatingFailed 1 "Fault" 0 "No Fault" ;
VAL_ 520 avm_trigByTurnningSts 1 "On" 0 "Off" ;
VAL_ 520 avm_singleViewSts 31 "Reserved" 30 "Reserved" 29 "Reserved" 28 "Reserved" 27 "Reserved" 26 "Reserved" 25 "Reserved" 24 "Reserved" 23 "Reserved" 22 "Reserved" 21 "Reserved" 20 "Reserved" 19 "Reserved" 18 "Reserved" 17 "Reserved" 16 "Reserved" 15 "Side View" 14 "Dynamic rear view" 13 "Dynamic front view" 12 "3D Rear-Right view" 11 "3D Rear-Left view" 10 "3D Front-Right view" 9 "3D Front-Left view" 8 "3D Right side view" 7 "3D Left side view" 6 "3D Top view of the trail" 5 "3D Top view of the head" 4 "2D Right view" 3 "2D Left view" 2 "2D Rear view" 1 "2D Front view" 0 "3D rotation view" ;
VAL_ 520 avm_frontModWarningSts 1 "Warning" 0 "No Warning" ;
VAL_ 520 avm_rearModWarningSts 1 "Warning" 0 "No Warning" ;
VAL_ 520 avm_leftModWarningSts 1 "Warning" 0 "No Warning" ;
VAL_ 520 avm_rightModWarningSts 1 "Warning" 0 "No Warning" ;
VAL_ 520 avm_calibrationSts 1 "Calibrated" 0 "Not calibrated" ;
VAL_ 520 avm_Trajectory_display 1 "ON" 0 "OFF" ;
VAL_ 520 avm_Autoswitching_display 1 "ON" 0 "OFF" ;
VAL_ 520 avm_CarBodyTransparent 1 "ON" 0 "OFF" ;
VAL_ 520 avm_SwSts 1 "Inhibited" 0 "Normal" ;
VAL_ 520 avm_PDCfailureWarn 7 "Reserved" 6 "Reserved" 5 "Reserved" 4 "PDC&&AVM failuer warning" 3 "AVM failure warning" 2 "PDC failure warning" 1 "Reserved" 0 "No Request" ;
VAL_ 520 avm_QuitSw 1 "Inhibited" 0 "Normal" ;
VAL_ 530 esc_vehicleSpeed 8191 "Invalid" ;
VAL_ 530 esc_vehicleSpeedValid 1 "VALID" 0 "INVALID" ;
VAL_ 530 esc_absFault 1 "FAULT" 0 "NORMAL" ;
VAL_ 530 esc_absActive 1 "ACTIVE" 0 "INACTIVE" ;
VAL_ 530 esc_vdcActive 1 "ACTIVE" 0 "INACTIVE" ;
VAL_ 530 esc_escActive 1 "ACTIVE" 0 "INACTIVE" ;
VAL_ 530 esc_tcsActive 1 "ACTIVE" 0 "INACTIVE" ;
VAL_ 530 esc_OBD_MILOnRq 1 "OBD Mil Request On" 0 "NO_REQUEST" ;
VAL_ 530 esc_avhActive 1 "ACTIVE" 0 "INACTIVE" ;
VAL_ 530 esc_avhStandby 1 "STANDBY" 0 "NOT_STANDBY" ;
VAL_ 530 esc_avhAvailable 1 "AVAILABLE" 0 "NOT_AVAILABLE" ;
VAL_ 530 esc_cdpActive 1 "ACTIVE" 0 "INACTIVE" ;
VAL_ 530 esc_cdpAvailable 1 "AVAILABLE" 0 "NOT_AVAILABLE" ;
VAL_ 530 esc_hdcSts 2 "ACTIVE" 1 "STANDBY" 0 "OFF" ;
VAL_ 530 esc_hdcAvailable 1 "AVAILABLE" 0 "NOT_AVAILABLE" ;
VAL_ 530 esc_hhcActive 1 "ACTIVE" 0 "INACTIVE" ;
VAL_ 530 esc_hhcAvailable 1 "AVAILABLE" 0 "NOT_AVAILABLE" ;
VAL_ 530 esc_masCylBrakePressure 4095 "Invalid" ;
VAL_ 530 esc_masCylBrakePressureValid 1 "VALID" 0 "INVALID" ;
VAL_ 530 esc_wheelCyBrakeForceExist 1 "BRAKE_FORCE_AVAILABLE" 0 "NO_BRAKE_FORCE" ;
VAL_ 530 esc_ebdFault 1 "FAULT" 0 "NOMAL" ;
VAL_ 530 esc_offSts 1 "ON" 0 "OFF" ;
VAL_ 530 esc_escFault 1 "FAULT" 0 "NOMAL" ;
VAL_ 530 esc_emergencyBrakeSts 1 "ACTIVE" 0 "INACTIVE" ;
VAL_ 530 esc_dtcActive 1 "ACTIVE" 0 "INACTIVE" ;
VAL_ 530 esc_gearholdRequst 1 "SHIFTING_SUPRESSED" 0 "SHIFTING_NOT_SUPRESSED" ;
VAL_ 537 mrr_accBrakePreferred 1 "DEMAND" 0 "NO_DEMAND" ;
VAL_ 537 mrr_accUpperComftBandReq 1 "DEMAND" 0 "NO_DEMAND" ;
VAL_ 537 mrr_accDriveOff 1 "DEMAND" 0 "NO_DEMAND" ;
VAL_ 537 mrr_accStandstillReq 1 "DEMAND" 0 "NO_DEMAND" ;
VAL_ 537 mrr_accVlcShutdownReq 3 "INITIAL" 2 "IMMEDIATE_OFF" 1 "FAST_OFF" 0 "SOFT_OFF" ;
VAL_ 537 mrr_accState 7 "FAILURE_MODE" 6 "STANDSTILL" 5 "BRAKE-ONLY_MODE" 4 "OVERRIDE" 3 "ACTIVE-CONTROL_MODE" 2 "STANDBY_MODE" 1 "PASSIVE_MODE" 0 "OFF_MODE" ;
VAL_ 537 mrr_accMode 7 "FAILURE_MODE" 6 "RESERVED" 5 "BRAKE-ONLY_MODE" 4 "OVERRIDE" 3 "ACTIVE-CONTROL_MODE" 2 "STANDBY_MODE" 1 "PASSIVE_MODE" 0 "OFF_MODE" ;
VAL_ 537 mrr_frtVehStrReminderSts 3 "reserved" 2 "Fault" 1 "ON" 0 "OFF" ;
VAL_ 538 mpc_leftVisualization 3 "WARNING" 2 "INTERVENTION" 1 "LINE_TRACKING" 0 "NO_DISPLAY" ;
VAL_ 538 mpc_rightVisualization 3 "WARNING" 2 "INTERVENTION" 1 "LINE_TRACKING" 0 "NO_DISPLAY" ;
VAL_ 538 mpc_laneAssitType 7 "Invalid" 6 "Reserved" 5 "Reserved" 4 "LDW+LCC" 3 "LDW+LKA" 2 "LDW" 1 "OFF" 0 "No Req" ;
VAL_ 538 mpc_adasTorqueReqSts 1 "ACTIVE" 0 "INACTIVE" ;
VAL_ 538 mpc_lasSensitivity 3 "reserved" 2 "highSensitivity" 1 "lowSensitivity" 0 "no information" ;
VAL_ 538 mpc_lasSts 7 "Reserved" 6 "Reserved" 5 "CAMERA_BLOCKED" 4 "FAULT_ADAS" 3 "ACTIVE_ADAS" 2 "STANDBY_ADAS" 1 "OFF_ADAS" 0 "NO_INFOMATION" ;
VAL_ 538 mpc_adasTakeoverReq 3 "RESERVED" 2 "LEVEL2(Text+high frequency sound)" 1 "LEVEL1(Text+low frequency sound)" 0 "INACTIVE" ;
VAL_ 538 mpc_tjaSts 7 "Reserved" 6 "Passive" 5 "CAMERA_BLOCKED" 4 "FAULT" 3 "ACTIVE" 2 "STANDBY" 1 "OFF" 0 "NO_INFOMATION" ;
VAL_ 538 mpc_isaOverSpdWarningSts 1 "Overspeed warning" 0 "No Overspeed warning" ;
VAL_ 538 mpc_tjaindinfo 4 "ICA error" 3 "Reserved" 2 "ICA activate" 1 "ICA on" 0 "ICA off" ;
VAL_ 538 mpc_isaMode 5 "DEFECT" 4 "NAVIGATION_MODE" 3 "VISION_MODE" 2 "FUSION_MODE" 1 "OFF" 0 "NO_INFOMATION" ;
VAL_ 538 mpc_adasTorqueReqValid 1 "VALID" 0 "INVALID" ;
VAL_ 538 mpc_isaSpeedLimit 27 "SPL_130" 26 "SPL_125" 25 "SPL_120" 24 "SPL_115" 23 "SPL_110" 22 "SPL_105" 21 "SPL_100" 20 "SPL_95" 19 "SPL_90" 18 "SPL_85" 17 "SPL_80" 16 "SPL_75" 15 "SPL_70" 14 "SPL_65" 13 "SPL_60" 12 "SPL_55" 11 "SPL_50" 10 "SPL_45" 9 "SPL_40" 8 "SPL_35" 7 "SPL_30" 6 "SPL_25" 5 "SPL_20" 4 "SPL_15" 3 "SPL_10" 2 "SPL_5" 1 "SPL_CANCELLED" 0 "NO_DISPLAY" ;
VAL_ 538 mpc_isaOnOffSts 3 "INVALID" 2 "ON with voice" 1 "ON without voice" 0 "OFF" ;
VAL_ 569 mrr_aebReq 1 "DEMAND" 0 "NO_DEMAND" ;
VAL_ 569 mrr_abaLevel 3 "LEVEL 3" 2 "LEVEL 2" 1 "LEVEL 1" 0 "LEVEL 0" ;
VAL_ 569 mrr_abaReq 1 "DEMAND" 0 "NO_DEMAND" ;
VAL_ 569 mrr_awbReq 1 "DEMAND" 0 "NO_DEMAND" ;
VAL_ 569 mrr_awbLevel 7 "Reserved" 6 "Reserved" 5 "Reserved" 4 "LEVEL 4" 3 "LEVEL 3" 2 "LEVEL 2" 1 "LEVEL 1" 0 "NO_LEVEL" ;
VAL_ 569 mrr_abpReq 1 "DEMAND" 0 "NO_DEMAND" ;
VAL_ 569 mrr_aebOnOffSts 3 "Invalid" 2 "RESERVED" 1 "ON" 0 "OFF" ;
VAL_ 569 mrr_accTakeOverReq 1 "VALID_TAKEOVER_REQUEST" 0 "NO_TAKEOVER_REQUEST" ;
VAL_ 569 mrr_PEBSWarning 7 "Reserved" 6 "Reserved" 5 "Braking  to PED" 4 "PreWarning to PED" 3 "Braking  to car" 2 "Latent distance Warning" 1 "PreWarning to car" 0 "NO_WARNING" ;
VAL_ 569 mrr_timeGapSet 7 "Reserved" 6 "Reserved" 5 "Reserved" 4 "Reserved" 3 "TAUGAP_2" 2 "TAUGAP_1" 1 "TAUGAP_0" 0 "No Request" ;
VAL_ 569 mrr_fcwOnOffSts 3 "Invalid" 2 "Reserved" 1 "ON" 0 "OFF" ;
VAL_ 569 mrr_textInfo 15 "Reserved" 14 "acc can't active because of ASC" 13 "acc opened" 12 "TJA activation can't meet" 11 "Front Vehicle Driveoff" 10 "please press reset or acceleration pedal" 9 "acc exited" 8 "acc cancelled" 7 "acc radar blocked" 6 "acc fault" 5 "acc activation can't meet" 4 "please put forward" 3 "please release the hanbrake" 2 "please fasten the safety bele" 1 "acc active" 0 "no display" ;
VAL_ 569 mrr_fcwSts 3 "INVALID" 2 "RESERVED" 1 "ON" 0 "OFF" ;
VAL_ 569 mrr_aebSts 3 "INVALID" 2 "RESERVED" 1 "ON" 0 "OFF" ;
VAL_ 571 mrr_r1_systemErrorSts 1 "Error" 0 "No error" ;
VAL_ 571 mrr_r1_BSDLCAWorkingSts 1 "On" 0 "Off" ;
VAL_ 571 mrr_r1_RCTAWorkingSts 1 "On" 0 "Off" ;
VAL_ 571 mrr_r1_DOWWorkingSts 1 "On" 0 "Off" ;
VAL_ 571 mrr_r1_RCWWorkingSts 1 "On" 0 "Off" ;
VAL_ 571 mrr_r1_leftBSDLCAWarning 3 "Invalid" 2 "Warning level 2" 1 "Warning level 1" 0 "NoWarning" ;
VAL_ 571 mrr_r1_leftRCTAWarnning 1 "Active" 0 "Inactive" ;
VAL_ 571 mrr_r1_leftDOWWarnning 3 "Invalid" 2 "Warning level 2" 1 "Warning level 1" 0 "Inactive" ;
VAL_ 571 mrr_r1_rearCollisionWarning 1 "Active" 0 "Inactive" ;
VAL_ 571 mrr_r1_rightBSDLCAWarning 3 "Invalid" 2 "Warning level 2" 1 "Warning level 1" 0 "NoWarning" ;
VAL_ 571 mrr_r1_rightRCTAWarnning 1 "Active" 0 "Inactive" ;
VAL_ 571 mrr_r1_rightDOWWarnning 3 "Invalid" 2 "Warning level 2" 1 "Warning level 1" 0 "Inactive" ;
VAL_ 571 mrr_r1_targetStsLR 1 "Exist" 0 "No exist" ;
VAL_ 571 mrr_r1_targetDangerLevelLR 3 "Reserved" 2 "Level 2" 1 "Level 1" 0 "Invalid" ;
VAL_ 571 mrr_r1_targetStsRR 1 "Exist" 0 "No exist" ;
VAL_ 571 mrr_r1_targetDangerLevelRR 3 "Reserved" 2 "Level 2" 1 "Level 1" 0 "Invalid" ;
VAL_ 571 mrr_r1_targetTypeLR 7 "Reserved" 6 "Reserved" 5 "Other" 4 "Sedan" 3 "pedestrian" 2 "2wheel" 1 "Truck" 0 "Invalid" ;
VAL_ 571 mrr_r1_targetTypeRR 7 "Reserved" 6 "Reserved" 5 "Other" 4 "Sedan" 3 "pedestrian" 2 "2wheel" 1 "Truck" 0 "Invalid" ;
VAL_ 577 vcu_accPedalPosValid 1 "VALID" 0 "INVALID" ;
VAL_ 577 vcu_tcmFail 1 "LIMPHOME_TCM" 0 "NORMAL_TCM" ;
VAL_ 577 vcu_motorRunning 1 "MOTOR_RUNNING" 0 "MOTOR_NOT_RUNNING" ;
VAL_ 577 vcu_overrideSts 1 "DRIVER_OVERRIDE" 0 "NO_OVERRIDE" ;
VAL_ 577 vcu_brakePedalSts 1 "NORMAL_CLOSE" 0 "NORMAL_OPEN" ;
VAL_ 577 vcu_brakePedalStsValid 1 "VALID" 0 "INVALID" ;
VAL_ 577 vcu_actualGearValid 1 "VALID" 0 "INVALID" ;
VAL_ 577 vcu_targetGearValid 1 "VALID" 0 "INVALID" ;
VAL_ 577 vcu_actualGear 3 "D" 2 "N" 1 "R" 0 "P" ;
VAL_ 577 vcu_targetGear 3 "D" 2 "N" 1 "R" 0 "P" ;
VAL_ 577 vcu_ccState 7 "FAILURE_MODE" 6 "STANDSTILL" 5 "BRAKE-ONLY_MODE" 4 "OVERRIDE" 3 "ACTIVE-CONTROL_MODE" 2 "STANDBY_MODE" 1 "PASSIVE_MODE" 0 "OFF_MODE" ;
VAL_ 577 vcu_vDisSet 255 "Invalid" ;
VAL_ 626 esc_sumOfEdgeFLWSSValid 1 "VALID" 0 "INVALID" ;
VAL_ 626 esc_sumOfEdgeFRWSSValid 1 "VALID" 0 "INVALID" ;
VAL_ 626 esc_wheelDirectionFLValid 1 "VALID" 0 "INVALID" ;
VAL_ 626 esc_wheelDirectionFRValid 1 "VALID" 0 "INVALID" ;
VAL_ 626 esc_wheelDirectionFL 3 "STOP" 2 "REVERSE" 1 "FORWARD" 0 "INVALID" ;
VAL_ 626 esc_wheelDirectionFR 3 "STOP" 2 "REVERSE" 1 "FORWARD" 0 "INVALID" ;
VAL_ 642 esc_sumOfEdgeRLWSSValid 1 "VALID" 0 "INVALID" ;
VAL_ 642 esc_sumOfEdgeRRWSSValid 1 "VALID" 0 "INVALID" ;
VAL_ 642 esc_wheelDirectionRLValid 1 "VALID" 0 "INVALID" ;
VAL_ 642 esc_wheelDirectionRRValid 1 "VALID" 0 "INVALID" ;
VAL_ 642 esc_wheelDirectionRL 3 "STOP" 2 "REVERSE" 1 "FORWARD" 0 "INVALID" ;
VAL_ 642 esc_wheelDirectionRR 3 "STOP" 2 "REVERSE" 1 "FORWARD" 0 "INVALID" ;
VAL_ 673 bcm_turnLampSerialReq 3 "Reserved" 2 "Reserved" 1 "Request" 0 "No Request" ;
VAL_ 673 bcm_turnLampFlickerReq 3 "Very High" 2 "HIGH" 1 "LOW" 0 "No Request" ;
VAL_ 673 bcm_drlReq 1 "Request" 0 "No Request" ;
VAL_ 673 bcm_posLampReq 1 "Request" 0 "No Request" ;
VAL_ 673 bcm_lowBeamReq 1 "Request" 0 "No Request" ;
VAL_ 673 bcm_highBeamReq 1 "Request" 0 "No Request" ;
VAL_ 673 bcm_leftTurnLampReq 1 "Request" 0 "No Request" ;
VAL_ 673 bcm_rightTurnLampReq 1 "Request" 0 "No Request" ;
VAL_ 673 bcm_hoodSts 1 "Opened" 0 "Closed" ;
VAL_ 673 bcm_hazardLightSts 1 "ON" 0 "OFF" ;
VAL_ 673 bcm_leftTurnLampSwSts 1 "ON" 0 "OFF" ;
VAL_ 673 bcm_leftTurnLampSts 1 "ON" 0 "OFF" ;
VAL_ 673 bcm_WipperMaintenanceSts 1 "ON" 0 "OFF" ;
VAL_ 673 bcm_pdcSwitchSet 1 "Pressed" 0 "No Press" ;
VAL_ 673 bcm_rightTurnLampSts 1 "ON" 0 "OFF" ;
VAL_ 673 bcm_HornSts 1 "Ringing" 0 "No Ring" ;
VAL_ 673 bcm_brakeLightReq 1 "Request" 0 "No Request" ;
VAL_ 673 bcm_rightTurnLampSwSts 1 "ON" 0 "OFF" ;
VAL_ 673 bcm_doorFLSts 1 "Opened" 0 "Closed" ;
VAL_ 673 bcm_doorFRSts 1 "Opened" 0 "Closed" ;
VAL_ 673 bcm_doorRLSts 1 "Opened" 0 "Closed" ;
VAL_ 673 bcm_doorRRSts 1 "Opened" 0 "Closed" ;
VAL_ 673 bcm_doorFLLockSts 1 "UNLOCK" 0 "LOCK" ;
VAL_ 673 bcm_LeftMirrorSw 1 "SW Pressed" 0 "SW Not Pressed" ;
VAL_ 673 bcm_rightMirrorSw 1 "SW Pressed" 0 "SW Not Pressed" ;
VAL_ 673 bcm_frontWiperParkingSts 1 "IN_PARK_AREA" 0 "OUT_PARK_AREA" ;
VAL_ 673 bcm_rearWiperParkingSts 1 "IN_PARK_AREA" 0 "OUT_PARK_AREA" ;
VAL_ 673 bcm_antiTheftSts 3 "HALF_ARMED" 2 "ALARM" 1 "ARMED" 0 "DISARMED" ;
VAL_ 673 bcm_fuelCapSts 3 "None" 2 "TAPERROR" 1 "OPEN" 0 "CLOSED" ;
VAL_ 673 bcm_frontWiperSts 7 "INVALID" 6 "SWTICH_FAILURE_RESERVED" 5 "AUTO_RESERVED" 4 "WASH" 3 "INTERRUPT_RESERVED" 2 "HIGH_SPEED" 1 "LOW_SPEED" 0 "STOP" ;
VAL_ 673 bcm_chrgCapSts 1 "OPEN" 0 "CLOSE" ;
VAL_ 673 bcm_gunUnlockCtrlReq 1 "Request" 0 "No Request" ;
VAL_ 673 bcm_readyReq 1 "Request" 0 "No Request" ;
VAL_ 673 bcm_mirrorAdjust 7 "Reserved" 6 "Reserved" 5 "Reserved" 4 "MIRROR_AROUND_Y_AXIS_RIGHT" 3 "MIRROR_AROUND_Y_AXIS_LEFT" 2 "MIRROR_AROUND_X_AXIS_DOWN" 1 "MIRROR_AROUND_X_AXIS_UP" 0 "NULL_OPERATING" ;
VAL_ 673 bcm_tailgateOpenSW 1 "ACTION" 0 "NO_ACTION" ;
VAL_ 673 bcm_apaOnOffSet 1 "Pressed" 0 "Released" ;
VAL_ 673 bcm_avmOnOffSet 1 "Pressed" 0 "Released" ;
VAL_ 673 bcm_driveMode 1 "Pressed" 0 "Released" ;
VAL_ 673 bcm_parkAutoCloseDRLSts 1 "ON" 0 "OFF" ;
VAL_ 673 bcm_HvReq 3 "INVALID" 2 "Reserved" 1 "EBS_ON" 0 "NO_REQUEST" ;
VAL_ 673 BCM_CloselightReq 1 "Request" 0 "No Request" ;
VAL_ 674 esc_cddActive 1 "ACTIVE" 0 "INACTIVE" ;
VAL_ 674 esc_cddAvailable 1 "AVAILABLE" 0 "NOT_AVAILABLE" ;
VAL_ 674 esc_cddError 1 "FAULT" 0 "NORMAL" ;
VAL_ 674 esc_cddTempOff 1 "TempTooHigh" 0 "NotHigh" ;
VAL_ 674 esc_abaActive 1 "ACTIVE" 0 "INACTIVE" ;
VAL_ 674 esc_abaAvailable 1 "AVAILABLE" 0 "NOT_AVAILABLE" ;
VAL_ 674 esc_abpActive 1 "ACTIVE" 0 "INACTIVE" ;
VAL_ 674 esc_abpAvailable 1 "AVAILABLE" 0 "NOT_AVAILABLE" ;
VAL_ 674 esc_aebActive 1 "ACTIVE" 0 "INACTIVE" ;
VAL_ 674 esc_aebAvailable 1 "AVAILABLE" 0 "NOT_AVAILABLE" ;
VAL_ 674 esc_awbActive 1 "ACTIVE" 0 "INACTIVE" ;
VAL_ 674 esc_awbAvailable 1 "AVAILABLE" 0 "NOT_AVAILABLE" ;
VAL_ 674 esc_vehicleStandstill 2 "RESERVED" 1 "STANDSTILL" 0 "NOT_STANDSTILL" ;
VAL_ 674 esc_vehicleStandstillValid 1 "VALID" 0 "INVALID" ;
VAL_ 674 esc_brakelightIlluminate 1 "ILLUMINATE" 0 "NOT_ILLUMINATE" ;
VAL_ 674 esc_vlcTorqReq 8191 "Invalid" ;
VAL_ 674 esc_vlcTorqReqActive 1 "ACTIVE" 0 "NOT_ACTIVE" ;
VAL_ 674 esc_vlcError 1 "ERROR" 0 "NOT_ERROR" ;
VAL_ 674 esc_vlcAvalible 1 "AVAILABLE" 0 "NOT_AVAILABLE" ;
VAL_ 674 esc_vlcInterTargetAx 255 "Invalid" ;
VAL_ 674 esc_hmiWarningOn 3 "NOT_AVAILABLE" 2 "RED" 1 "YELLOW" 0 "NO_REQUEST" ;
VAL_ 674 esc_hmiWarningOn_Q 2 "FAULTY" 1 "NORMAL" 0 "NOT_INITIALIZED" ;
VAL_ 674 esc_vlcActive 1 "ACTIVE" 0 "INACTIVE" ;
VAL_ 674 esc_hbbSts 3 "DISABLED" 2 "FAILED_BOOST_BACKUP" 1 "FAILED_BOOST" 0 "NORMAL_MODE" ;
VAL_ 674 esc_hbbActive 1 "ACTIVE" 0 "INACTIVE" ;
VAL_ 684 bcm_sl_currentPos 3 "Reserved" 2 "Middle" 1 "Opened" 0 "Closed" ;
VAL_ 684 bcm_sl_roatingSts 3 "Error" 2 "Down roating" 1 "Up roating" 0 "Move Complete" ;
VAL_ 684 bcm_sl_isRoatingEn 1 "Disable" 0 "Enable" ;
VAL_ 684 bcm_sl_Valid 1 "Invalid" 0 "Valid" ;
VAL_ 684 bcm_apm_flVentilationFb 3 "Reserved" 2 "Failed" 1 "Success" 0 "Default" ;
VAL_ 684 bcm_apm_frVentilationFb 3 "Reserved" 2 "Failed" 1 "Success" 0 "Default" ;
VAL_ 684 bcm_apm_rlVentilationFb 3 "Reserved" 2 "Failed" 1 "Success" 0 "Default" ;
VAL_ 684 bcm_apm_rrVentilationFb 3 "Reserved" 2 "Failed" 1 "Success" 0 "Default" ;
VAL_ 684 bcm_srm_srOpenPosition 127 "Invalid" ;
VAL_ 684 bcm_ssm_ssOpenPosition 127 "Invalid" ;
VAL_ 684 bcm_ebs_U_BATT 255 "Invalid" ;
VAL_ 684 bcm_sl_errSts 7 "Low Temperature" 6 "Switch sticked fault" 5 "Stucked" 4 "Over Current" 3 "Over Temperature" 2 "lding" 1 "abnormal voltage" 0 "Normal" ;
VAL_ 684 bcm_rsm_lightSWReason 7 "Reserved" 6 "Reserved" 5 "Reserved" 4 "Darkstart" 3 "Tunnel" 2 "Dark" 1 "Others" 0 "Day" ;
VAL_ 705 bcm_pepsPowerMode 7 "INVALID_POWERMODE" 6 "RESERVE_POWERMODE3" 5 "RESERVE_POWERMODE2" 4 "RESERVE_POWERMODE1" 3 "RESERVE_POWERMODE" 2 "ON_POWERMODE" 1 "OFF_POWERMODE" 0 "DEFAULT_POWERMODE" ;
VAL_ 705 bcm_IMMOReleaseIndication 1 "INDICATION" 0 "NO_INDICATION" ;
VAL_ 705 bcm_pepsKeyNotInCarInd 1 "WARNING" 0 "NO_WARNING" ;
VAL_ 705 bcm_keyValid 2 "INVALID" 1 "YES" 0 "NO" ;
VAL_ 705 bcm_pepsKeySerchFailInd 1 "WARNING" 0 "NO_WARNING" ;
VAL_ 705 bcm_pepsKeyCloserInd 1 "WARNING" 0 "NO_WARNING" ;
VAL_ 705 bcm_pepsFobLowBatWarning 1 "WARNING" 0 "NO_WARNING" ;
VAL_ 705 bcm_pepsPowerRelayErrWarning 1 "WARNING" 0 "NO_WARNING" ;
VAL_ 705 bcm_RearWindowLockSts 1 "UNLOCK" 0 "LOCK" ;
VAL_ 705 bcm_IndicationPressBrake 1 "Warning" 0 "No warning" ;
VAL_ 705 bcm_LowFrequencyAntennaFault 1 "Fault" 0 "Normal" ;
VAL_ 705 bcm_remoteMode 3 "Reserved" 2 "REMOTE" 1 "NORMAL" 0 "INVALID" ;
VAL_ 705 bcm_ble_response 3 "Reserved" 2 "Anti theft authentication success(防盗认证成功)" 1 "Anti theft authentication failed(防盗认证失败)" 0 "default" ;
VAL_ 705 bcm_autoGlassCloseWarning 1 "Warning" 0 "No warning" ;
VAL_ 705 bcm_rke_fuelPortCapOpenCtrl 3 "INVALID" 2 "RESERVED" 1 "OPEN_FUELPORT" 0 "NO_COMMAND_FUELPORT" ;
VAL_ 705 bcm_fhcActionLeftFront 2 "RETRACT" 1 "EXTRACT" 0 "NONE" ;
VAL_ 705 bcm_fhcActionRightFront 2 "RETRACT" 1 "EXTRACT" 0 "NONE" ;
VAL_ 705 bcm_fhcActionLeftRear 2 "RETRACT" 1 "EXTRACT" 0 "NONE" ;
VAL_ 705 bcm_fhcActionRightRear 2 "RETRACT" 1 "EXTRACT" 0 "NONE" ;
VAL_ 705 bcm_pepsKeyInCarInd 1 "WARNING" 0 "NO_WARNING" ;
VAL_ 705 bcm_tbox_response 3 "Reserved" 2 "Anti theft authentication success(防盗认证成功)" 1 "Anti theft authentication failed(防盗认证失败)" 0 "default" ;
VAL_ 705 bcm_approachingUnlockFedb 3 "INVALID" 2 "INACTIVE" 1 "ACTIVE" 0 "Default" ;
VAL_ 705 bcm_followMeHomeFedb 7 "INVALID" 4 "60S" 3 "30S" 2 "15S" 1 "OFF" 0 "RESERVED" ;
VAL_ 705 bcm_awayLockFeedback 3 "INVALID" 2 "INACTIVE" 1 "ACTIVE" 0 "RESERVED" ;
VAL_ 705 bcm_MirrorAutoFoldUnfoldSts 3 "INVALID" 2 "ON" 1 "OFF" 0 "NO  Request" ;
VAL_ 706 esc_epbFaultLamp 3 "RESERVED_EPB1" 2 "LAMP_FLASH" 1 "LAMP_ON" 0 "LAMP_OFF" ;
VAL_ 706 esc_epbParkingLamp 3 "RESERVED_EPB2" 2 "LAMP_FLASH" 1 "LAMP_ON" 0 "LAMP_OFF" ;
VAL_ 706 esc_epbTextDisplay 15 "INVALID" 14 "RESERVED_EPB11" 13 "RESERVED_EPB10" 12 "RESERVED_EPB9" 11 "RESERVED_EPB8" 10 "RESERVED_EPB7" 9 "RESERVED_EPB6" 8 "RESERVED_EPB5" 7 "RESERVED_EPB4" 6 "RESERVED_EPB3" 5 "PRESS_BRAKE_PEDAL" 4 "OPEN_PARK_BRAKE_BY_SWITCH" 3 "FASTEN_SEATBELT" 2 "CLAMPFORCE_NOT_ENOUGH" 1 "GRADIENT_TOO_HIGH" 0 "NO_TEXT_MESSAGE" ;
VAL_ 706 esc_epbSts 7 "RESERVED_EPB14" 6 "RESERVED_EPB13" 5 "RESERVED_EPB12" 4 "RELEASING" 3 "PARKING" 2 "RELEASED" 1 "PARKED" 0 "DEFAULT" ;
VAL_ 706 esc_epbTextDisplayOnIVI 3 "Parking brake fault" 2 "Please wear your seat belt for releasing the parking" 1 "Press the brake pedal first,then release the EBP button" 0 "OFF" ;
VAL_ 706 esc_epbAutoApplyInAction 1 "TRUE" 0 "FALSE" ;
VAL_ 706 esc_epbTowModeInAction 1 "TRUE" 0 "FALSE" ;
VAL_ 720 ble_phoneLocation 8 "后背门PE区" 7 "右前PE区" 6 "左前PE区" 5 "车内" 4 "靠近解锁区" 3 "远离闭锁区" 2 "迎宾开灯区" 1 "迎宾无效区" 0 "Invalid" ;
VAL_ 720 ble_keyIndex 6 "钥匙索引6" 5 "钥匙索引5" 4 "钥匙索引4" 3 "钥匙索引3" 2 "钥匙索引2" 1 "钥匙索引1" 0 "Invalid" ;
VAL_ 720 ble_KeyIdentify 3 "遥控钥匙有效" 2 "非车主手机蓝牙钥匙有效" 1 "车主手机蓝牙钥匙有效" 0 "Invalid" ;
VAL_ 720 ble_VelPermissionSet 3 "禁止起动" 2 "仅后备箱控制" 1 "全功能权限" 0 "Invalid" ;
VAL_ 753 AC_PoorInAirQuality 1 "Poor" 0 "Normal" ;
VAL_ 753 AC_PM25Sts 3 "Reserved" 2 "Complete" 1 "Collecting" 0 "Standby" ;
VAL_ 753 AC_AutoModeSt 3 "Strong" 2 "Normal" 1 "Soft" 0 "Invalid" ;
VAL_ 753 AC_OneTouchCoolSts 1 "On" 0 "Off" ;
VAL_ 753 AC_OneTouchHeatSts 1 "On" 0 "Off" ;
VAL_ 762 vcu_consumpRatio10km 2047 "Invalid" ;
VAL_ 762 vcu_consumpRatioInstant 2047 "Invalid" ;
VAL_ 762 vcu_RecoveryPowerAllowed 1023 "Invalid" 0 "Init" ;
VAL_ 762 vcu_GearPosNotEqual 4 "TowMode Exit Warning" 3 "EPB Warning" 2 "BrakePedal Warning" 1 "VehicleSpeed Warning" 0 "Equal" ;
VAL_ 762 vcu_RecoveryPowerAcutal 1023 "Invalid" 0 "Init" ;
VAL_ 762 VCU_StandStillPreheatBattWarn 1 "BattPreheat" 0 "Normal" ;
VAL_ 762 VCU_LowTempInhibitPowerUpWarn 1 "InhibitPowerUp" 0 "Normal" ;
VAL_ 762 VCU_SOCmodeSet 3 "Reserved" 2 "REVmode" 1 "EVmode" 0 "SmartMode" ;
VAL_ 769 vcu_avgPwrCurrentTrip 2047 "Invalid" ;
VAL_ 769 vcu_avgPwrSincelastcharge 2047 "Invalid" ;
VAL_ 769 vcu_avgPwroftripA 2047 "Invalid" ;
VAL_ 769 vcu_PwroftripB 16383 "Invalid" ;
VAL_ 769 vcu_avgPwroftripB 2047 "Invalid" ;
VAL_ 772 bms_thermalReqState 7 "COLD_FAULT" 6 "HOT_FAULT" 5 "HEATING" 4 "WATER" 3 "URGENT" 2 "NORMAL" 1 "COMFORT" 0 "STANDBY" ;
VAL_ 777 gsm_faultSts 1 "FAULT" 0 "NORMAL" ;
VAL_ 777 gsm_gearSelectorPos 7 "SENSOR_FAULT" 6 "RESERVE_GSM3" 5 "RESERVE_GSM2" 4 "NO_TARGET" 3 "D" 2 "N" 1 "R" 0 "P" ;
VAL_ 777 gsm_faultLevel 3 "FAULT LEVEL 3" 2 "FAULT LEVEL 2" 1 "FAULT LEVEL 1" 0 "NORMAL" ;
VAL_ 777 gsm_intervention 1 "Driver Request Intervention" 0 "No Intervention" ;
VAL_ 777 gsm_apa_gearReqfdbk 1 "Enable" 0 "Disable" ;
VAL_ 777 gsm_warnInformation 7 "Reserved" 6 "Reserved" 5 "Reserved" 4 "Knob is clamp，please check（换挡杆卡滞，请检查）" 3 "Unlock Button Invalid" 2 "P Button Invalid" 1 "please press unlock buttton" 0 "no warn" ;
VAL_ 782 bms_vPackBmu 16383 "Invalid" ;
VAL_ 782 bms_vPackBms 16383 "Invalid" ;
VAL_ 782 bms_iPack 16383 "Invalid" ;
VAL_ 782 bms_pPack 8191 "Invalid" ;
VAL_ 793 swm_Photo 1 "Pressed" 0 "Released" ;
VAL_ 793 swm_ACCSW 1 "Pressed" 0 "Released" ;
VAL_ 793 swm_ACCSWValid 1 "Valid" 0 "Invalid" ;
VAL_ 793 swm_ACCRESorAdd 1 "Pressed" 0 "Released" ;
VAL_ 793 swm_ACCRESorAddValid 1 "Valid" 0 "Invalid" ;
VAL_ 793 swm_ACCSETorSub 1 "Pressed" 0 "Released" ;
VAL_ 793 swm_ACCSETorSubValid 1 "Valid" 0 "Invalid" ;
VAL_ 793 swm_ACCInterval 1 "Pressed" 0 "Released" ;
VAL_ 793 swm_ACCIntervalValid 1 "Valid" 0 "Invalid" ;
VAL_ 793 swm_CNCL 1 "Pressed" 0 "Released" ;
VAL_ 793 swm_CNCLValid 1 "Valid" 0 "Invalid" ;
VAL_ 793 swm_TJAHWASwtich 1 "Pressed" 0 "Released" ;
VAL_ 793 swm_TJAHWASwtichValid 1 "Valid" 0 "Invalid" ;
VAL_ 793 swm_menu 1 "Pressed" 0 "Released" ;
VAL_ 793 swm_OK 1 "Pressed" 0 "Released" ;
VAL_ 793 swm_upAdd 1 "Pressed" 0 "Released" ;
VAL_ 793 swm_downMinus 1 "Pressed" 0 "Released" ;
VAL_ 793 swm_leftLast 1 "Pressed" 0 "Released" ;
VAL_ 793 swm_rightNext 1 "Pressed" 0 "Released" ;
VAL_ 793 swm_nvsSwitch 1 "Pressed" 0 "Released" ;
VAL_ 793 swm_phone 1 "Pressed" 0 "Released" ;
VAL_ 793 swm_voice 1 "Pressed" 0 "Released" ;
VAL_ 793 swm_highbeam 1 "ON" 0 "OFF" ;
VAL_ 793 swm_overtakingLight 1 "ON" 0 "OFF" ;
VAL_ 793 swm_turnSW 3 "Reserve" 2 "Turn Right" 1 "Turn Left" 0 "OFF" ;
VAL_ 793 swm_changeLaneSW 3 "Reserve" 2 "Change lane to Right" 1 "Change lane to left" 0 "OFF" ;
VAL_ 793 swm_frontWashing 1 "ON" 0 "OFF" ;
VAL_ 793 swm_frontWiper 7 "Reserved" 6 "Reserved" 5 "Reserved" 4 "High velocity" 3 "Low velocity" 2 "Auto" 1 "MIST" 0 "OFF" ;
VAL_ 793 swm_backWiper 3 "Reserved" 2 "Reserved" 1 "On" 0 "OFF" ;
VAL_ 793 swm_backWashing 1 "ON" 0 "OFF" ;
VAL_ 793 swm_autoWiper 7 "Reserved" 6 "Reserved" 5 "Reserved" 4 "gear4" 3 "gear3" 2 "gear2" 1 "gear1" 0 "Default" ;
VAL_ 793 swm_trumpet 1 "Pressed" 0 "Released" ;
VAL_ 793 swm_userdefined 1 "Pressed" 0 "Released" ;
VAL_ 793 swm_CCSwitch 1 "Pressed" 0 "Released" ;
VAL_ 793 swm_CCSwitchInvalid 1 "Valid" 0 "Invalid" ;
